VERSION "dbc-export 1 2025.20.8"

NS_ :

BS_:

BU_: ADSP APB APP APS APSB BB BMS CC CMP CMPD CP DAS DI DIF DIR DPB EPAS3P EPAS3S EPASTP EPASTS EPBL EPBR ESP EVSE FC GTW HCML HCMR HVP IBST ICR IDB LS OCS1P PARK PCS PM PMF PMR PNCD PTC RADC RCM RCM2 RCM3 RCU SCCM SCM SCS SDCR TAS TCU TPMS TRCM UI UIS UMC USM VC VCFRONT VCLEFT VCRIGHT VCSEC VEH

BO_ 753 VCFRONT_eFuseDebugStatus: 8 VCFRONT
 SG_ VCFRONT_eFuseDebugStatusIndex M : 0|5@1+ (1,0) [0|31] "" Vector__XXX
 SG_ VCFRONT_leftControllerState m1 : 8|2@1+ (1,0) [0|3] "" Vector__XXX
 SG_ VCFRONT_leftControllerFault m1 : 10|1@1+ (1,0) [0|1] "" Vector__XXX
 SG_ VCFRONT_vcleftSelfTestResult m1 : 11|4@1+ (1,0) [0|15] "" Vector__XXX
 SG_ VCFRONT_leftControllerTemp m1 : 15|11@1+ (0.125,-40) [-40|150] "degC" Vector__XXX
 SG_ VCFRONT_leftControllerEFuseVNFSt m1 : 26|3@1+ (1,0) [0|7] "" Vector__XXX
 SG_ VCFRONT_leftControllerEFuseOutpu m1 : 29|1@1+ (1,0) [0|1] "" Vector__XXX
 SG_ VCFRONT_leftControllerEFuse_0002 m1 : 30|1@1+ (1,0) [0|1] "" Vector__XXX
 SG_ VCFRONT_leftControllerVoltage m1 : 31|14@1+ (0.1,0) [0|1638.3] "V" Vector__XXX
 SG_ VCFRONT_leftControllerEFuseBypas m1 : 45|1@1+ (1,0) [0|1] "" Vector__XXX
 SG_ VCFRONT_leftControllerEFuse_0001 m1 : 46|1@1+ (1,0) [0|1] "" Vector__XXX
 SG_ VCFRONT_leftControllerCurrent m1 : 47|14@1+ (0.1,0) [0|1638.3] "A" Vector__XXX
 SG_ VCFRONT_leftControllerEFuseVNFSe m1 : 61|2@1+ (1,0) [0|3] "" Vector__XXX
 SG_ VCFRONT_PCSState m2 : 8|2@1+ (1,0) [0|3] "" Vector__XXX
 SG_ VCFRONT_PCSFault m2 : 10|1@1+ (1,0) [0|1] "" Vector__XXX
 SG_ VCFRONT_pcsSelfTestResult m2 : 11|4@1+ (1,0) [0|15] "" Vector__XXX
 SG_ VCFRONT_PCSTemp m2 : 15|11@1+ (0.125,-40) [-40|150] "degC" Vector__XXX
 SG_ VCFRONT_PCSEFuseVNFState m2 : 26|3@1+ (1,0) [0|7] "" Vector__XXX
 SG_ VCFRONT_PCSEFuseOutput m2 : 29|1@1+ (1,0) [0|1] "" Vector__XXX
 SG_ VCFRONT_PCSEFuseOutputDesired m2 : 30|1@1+ (1,0) [0|1] "" Vector__XXX
 SG_ VCFRONT_PCSVoltage m2 : 31|14@1+ (0.1,0) [0|1638.3] "V" Vector__XXX
 SG_ VCFRONT_PCSEFuseBypass m2 : 45|1@1+ (1,0) [0|1] "" Vector__XXX
 SG_ VCFRONT_PCSEFuseBypassDesired m2 : 46|1@1+ (1,0) [0|1] "" Vector__XXX
 SG_ VCFRONT_PCSEFuseVNFSelfTestStatu m2 : 61|2@1+ (1,0) [0|3] "" Vector__XXX
 SG_ VCFRONT_iBoosterState m3 : 8|2@1+ (1,0) [0|3] "" Vector__XXX
 SG_ VCFRONT_iBoosterFault m3 : 10|1@1+ (1,0) [0|1] "" Vector__XXX
 SG_ VCFRONT_iBoosterSelfTestResult m3 : 11|4@1+ (1,0) [0|15] "" Vector__XXX
 SG_ VCFRONT_iBoosterTemp m3 : 15|11@1+ (0.125,-40) [-40|150] "degC" Vector__XXX
 SG_ VCFRONT_IBoosterEFuseVNFState m3 : 26|3@1+ (1,0) [0|7] "" Vector__XXX
 SG_ VCFRONT_IBoosterEFuseOutput m3 : 29|1@1+ (1,0) [0|1] "" Vector__XXX
 SG_ VCFRONT_IBoosterEFuseOutputDesir m3 : 30|1@1+ (1,0) [0|1] "" Vector__XXX
 SG_ VCFRONT_iBoosterVoltage m3 : 31|14@1+ (0.1,0) [0|51.1] "V" Vector__XXX
 SG_ VCFRONT_IBoosterEFuseBypass m3 : 45|1@1+ (1,0) [0|1] "" Vector__XXX
 SG_ VCFRONT_IBoosterEFuseBypassDesir m3 : 46|1@1+ (1,0) [0|1] "" Vector__XXX
 SG_ VCFRONT_iBoosterCurrent m3 : 47|14@1+ (0.1,0) [0|1638.3] "A" Vector__XXX
 SG_ VCFRONT_IBoosterEFuseVNFSelfTest m3 : 61|2@1+ (1,0) [0|3] "" Vector__XXX
 SG_ VCFRONT_EPAS3PState m4 : 8|2@1+ (1,0) [0|3] "" Vector__XXX
 SG_ VCFRONT_EPAS3PFault m4 : 10|1@1+ (1,0) [0|1] "" Vector__XXX
 SG_ VCFRONT_EPAS3PSelfTestResult m4 : 11|4@1+ (1,0) [0|15] "" Vector__XXX
 SG_ VCFRONT_EPAS3PTemp m4 : 15|11@1+ (0.125,-40) [-40|150] "degC" Vector__XXX
 SG_ VCFRONT_EPAS3PEFuseVNFState m4 : 26|3@1+ (1,0) [0|7] "" Vector__XXX
 SG_ VCFRONT_EPAS3PEFuseOutput m4 : 29|1@1+ (1,0) [0|1] "" Vector__XXX
 SG_ VCFRONT_EPAS3PEFuseOutputDesired m4 : 30|1@1+ (1,0) [0|1] "" Vector__XXX
 SG_ VCFRONT_EPAS3PVoltage m4 : 31|9@1+ (0.1,0) [0|51.1] "V" Vector__XXX
 SG_ VCFRONT_EPAS3PEFuseHardshortThre m4 : 40|4@1+ (1,0) [0|15] "" Vector__XXX
 SG_ VCFRONT_EPAS3PEFuseBypass m4 : 45|1@1+ (1,0) [0|1] "" Vector__XXX
 SG_ VCFRONT_EPAS3PEFuseBypassDesired m4 : 46|1@1+ (1,0) [0|1] "" Vector__XXX
 SG_ VCFRONT_EPAS3PCurrent m4 : 47|14@1+ (0.1,0) [0|1638.3] "A" Vector__XXX
 SG_ VCFRONT_EPAS3PEFuseVNFSelfTestSt m4 : 61|2@1+ (1,0) [0|3] "" Vector__XXX
 SG_ VCFRONT_EPAS3SState m5 : 8|2@1+ (1,0) [0|3] "" Vector__XXX
 SG_ VCFRONT_EPAS3SFault m5 : 10|1@1+ (1,0) [0|1] "" Vector__XXX
 SG_ VCFRONT_EPAS3SSelfTestResult m5 : 11|4@1+ (1,0) [0|15] "" Vector__XXX
 SG_ VCFRONT_EPAS3STemp m5 : 15|11@1+ (0.125,-40) [-40|150] "degC" Vector__XXX
 SG_ VCFRONT_EPAS3SEFuseVNFState m5 : 26|3@1+ (1,0) [0|7] "" Vector__XXX
 SG_ VCFRONT_EPAS3SEFuseOutput m5 : 29|1@1+ (1,0) [0|1] "" Vector__XXX
 SG_ VCFRONT_EPAS3SEFuseOutputDesired m5 : 30|1@1+ (1,0) [0|1] "" Vector__XXX
 SG_ VCFRONT_EPAS3SVoltage m5 : 31|14@1+ (0.1,0) [0|1638.3] "V" Vector__XXX
 SG_ VCFRONT_EPAS3SEFuseBypass m5 : 45|1@1+ (1,0) [0|1] "" Vector__XXX
 SG_ VCFRONT_EPAS3SEFuseBypassDesired m5 : 46|1@1+ (1,0) [0|1] "" Vector__XXX
 SG_ VCFRONT_EPAS3SCurrent m5 : 47|14@1+ (0.1,0) [0|1638.3] "A" Vector__XXX
 SG_ VCFRONT_EPAS3SEFuseVNFSelfTestSt m5 : 61|2@1+ (1,0) [0|3] "" Vector__XXX
 SG_ VCFRONT_ESPMotorState m6 : 8|2@1+ (1,0) [0|3] "" Vector__XXX
 SG_ VCFRONT_ESPMotorFault m6 : 10|1@1+ (1,0) [0|1] "" Vector__XXX
 SG_ VCFRONT_ESPMotorSelfTestResult m6 : 11|4@1+ (1,0) [0|15] "" Vector__XXX
 SG_ VCFRONT_ESPMotorTemp m6 : 15|11@1+ (0.125,-40) [-40|150] "degC" Vector__XXX
 SG_ VCFRONT_ESPMotorEFuseVNFState m6 : 26|3@1+ (1,0) [0|7] "" Vector__XXX
 SG_ VCFRONT_ESPMotorEFuseOutput m6 : 29|1@1+ (1,0) [0|1] "" Vector__XXX
 SG_ VCFRONT_ESPMotorEFuseOutputDesir m6 : 30|1@1+ (1,0) [0|1] "" Vector__XXX
 SG_ VCFRONT_ESPMotorVoltage m6 : 31|14@1+ (0.1,0) [0|1638.3] "V" Vector__XXX
 SG_ VCFRONT_ESPMotorEFuseBypass m6 : 45|1@1+ (1,0) [0|1] "" Vector__XXX
 SG_ VCFRONT_ESPMotorEFuseBypassDesir m6 : 46|1@1+ (1,0) [0|1] "" Vector__XXX
 SG_ VCFRONT_ESPMotorCurrent m6 : 47|14@1+ (0.1,0) [0|1638.3] "A" Vector__XXX
 SG_ VCFRONT_ESPMotorEFuseVNFSelfTest m6 : 61|2@1+ (1,0) [0|3] "" Vector__XXX
 SG_ VCFRONT_ESPValveState m7 : 8|2@1+ (1,0) [0|3] "" Vector__XXX
 SG_ VCFRONT_ESPValveFault m7 : 10|1@1+ (1,0) [0|1] "" Vector__XXX
 SG_ VCFRONT_ESPValveTemp m7 : 12|11@1+ (0.125,-40) [-40|150] "degC" Vector__XXX
 SG_ VCFRONT_ESPValveVoltage m7 : 28|16@1+ (0.1,0) [0|6553.5] "V" Vector__XXX
 SG_ VCFRONT_ESPValveCurrent m7 : 44|16@1+ (0.01,0) [0|655.35] "A" Vector__XXX
 SG_ VCFRONT_autopilot2State m9 : 8|2@1+ (1,0) [0|3] "" Vector__XXX
 SG_ VCFRONT_autopilot2Fault m9 : 10|1@1+ (1,0) [0|1] "" Vector__XXX
 SG_ VCFRONT_autopilot2Temp m9 : 11|11@1+ (0.125,-40) [-40|150] "degC" Vector__XXX
 SG_ VCFRONT_autopilot2Voltage m9 : 27|16@1+ (0.1,0) [0|6553.5] "V" Vector__XXX
 SG_ VCFRONT_autopilot2Current m9 : 43|10@1+ (0.044,0) [0|45.012] "A" Vector__XXX
 SG_ VCFRONT_sleepBypassState m10 : 8|1@1+ (1,0) [0|1] "" Vector__XXX
 SG_ VCFRONT_sleepBypassFault m10 : 9|1@1+ (1,0) [0|1] "" Vector__XXX
 SG_ VCFRONT_sleepBypassVoltage m10 : 10|16@1+ (0.1,0) [0|6553.5] "V" Vector__XXX
 SG_ VCFRONT_sleepBypassCurrent m10 : 26|16@1+ (0.1,0) [0|6553.5] "A" Vector__XXX
 SG_ VCFRONT_vbatFusedHighState m13 : 8|1@1+ (1,0) [0|1] "" Vector__XXX
 SG_ VCFRONT_vbatFusedHighFault m13 : 9|1@1+ (1,0) [0|1] "" Vector__XXX
 SG_ VCFRONT_vbatFusedSelfTestResult m13 : 10|4@1+ (1,0) [0|15] "" Vector__XXX
 SG_ VCFRONT_vbatFusedHighTemp m13 : 14|11@1+ (0.125,-40) [-40|150] "degC" Vector__XXX
 SG_ VCFRONT_vbatFusedHighVoltage m13 : 30|16@1+ (0.1,0) [0|6553.5] "V" Vector__XXX
 SG_ VCFRONT_vbatFusedHighCurrent m13 : 46|16@1+ (0.1,0) [0|6553.5] "A" Vector__XXX
 SG_ VCFRONT_chargedIBSAmpHours m17 : 8|16@1+ (1,0) [0|65535] "Ah" Vector__XXX
 SG_ VCFRONT_dischargedIBSAmpHours m17 : 24|16@1+ (1,0) [0|65535] "Ah" Vector__XXX
 SG_ VCFRONT_IBSUnfilteredTemperature m17 : 40|16@1- (0.01,0) [-327.67|327.67] "degC" Vector__XXX

BO_ 769 VCFRONT_info: 8 VCFRONT
 SG_ VCFRONT_infoIndex M : 0|8@1+ (1,0) [0|255] "" Vector__XXX
 SG_ VCFRONT_infoBuildType m10 : 8|3@1+ (1,0) [0|7] "" Vector__XXX
 SG_ VCFRONT_infoBuildConfigId m10 : 16|16@1+ (1,0) [0|65535] "" Vector__XXX
 SG_ VCFRONT_infoHardwareId m10 : 32|16@1+ (1,0) [0|65535] "" Vector__XXX
 SG_ VCFRONT_infoComponentId m10 : 48|16@1+ (1,0) [0|65535] "" Vector__XXX
 SG_ VCFRONT_infoPcbaId m11 : 8|8@1+ (1,0) [0|255] "" Vector__XXX
 SG_ VCFRONT_infoAssemblyId m11 : 16|8@1+ (1,0) [0|255] "" Vector__XXX
 SG_ VCFRONT_infoUsageId m11 : 24|16@1+ (1,0) [0|65535] "" Vector__XXX
 SG_ VCFRONT_infoSubUsageId m11 : 40|16@1+ (1,0) [0|65535] "" Vector__XXX
 SG_ VCFRONT_infoAppCrc m13 : 8|32@1+ (1,0) [0|4294967295] "" Vector__XXX
 SG_ VC_infoHCMLAppCRC m16 : 32|32@1+ (1,0) [0|4294967295] "" Vector__XXX
 SG_ VCFRONT_infoAppGitHash m17 : 8|56@1+ (1,0) [0|7.20575940379e+16] "" Vector__XXX
 SG_ VCFRONT_infoBootGitHash m18 : 8|56@1+ (1,0) [0|7.20575940379e+16] "" Vector__XXX
 SG_ VCFRONT_infoPlatformType m19 : 8|8@1+ (1,0) [0|255] "" Vector__XXX
 SG_ VCFRONT_infoBootUdsProtoVersion m20 : 8|16@1+ (1,0) [0|65535] "" Vector__XXX
 SG_ VCFRONT_infoBootCrc m20 : 24|32@1+ (1,0) [0|4294967295] "" Vector__XXX
 SG_ VC_infoHCMRAppCRC m23 : 32|32@1+ (1,0) [0|4294967295] "" Vector__XXX

BO_ 1014 VCFRONT_lightStatus: 8 VCFRONT
 SG_ VCFRONT_lowBeamLeftStatus : 0|2@1+ (1,0) [0|3] "" Vector__XXX
 SG_ VCFRONT_lowBeamRightStatus : 2|2@1+ (1,0) [0|3] "" Vector__XXX
 SG_ VCFRONT_highBeamLeftStatus : 4|2@1+ (1,0) [0|3] "" Vector__XXX
 SG_ VCFRONT_highBeamRightStatus : 6|2@1+ (1,0) [0|3] "" Vector__XXX
 SG_ VCFRONT_DRLLeftStatus : 8|2@1+ (1,0) [0|3] "" Vector__XXX
 SG_ VCFRONT_DRLRightStatus : 10|2@1+ (1,0) [0|3] "" Vector__XXX
 SG_ VCFRONT_fogLeftStatus : 12|2@1+ (1,0) [0|3] "" Vector__XXX
 SG_ VCFRONT_fogRightStatus : 14|2@1+ (1,0) [0|3] "" Vector__XXX
 SG_ VCFRONT_sideMarkersStatus : 16|2@1+ (1,0) [0|3] "" Vector__XXX
 SG_ VCFRONT_sideRepeaterLeftStatus : 18|2@1+ (1,0) [0|3] "" Vector__XXX
 SG_ VCFRONT_sideRepeaterRightStatus : 20|2@1+ (1,0) [0|3] "" Vector__XXX
 SG_ VCFRONT_turnSignalLeftStatus : 22|2@1+ (1,0) [0|3] "" Vector__XXX
 SG_ VCFRONT_turnSignalRightStatus : 24|2@1+ (1,0) [0|3] "" Vector__XXX
 SG_ VCFRONT_parkLeftStatus : 26|2@1+ (1,0) [0|3] "" Vector__XXX
 SG_ VCFRONT_parkRightStatus : 28|2@1+ (1,0) [0|3] "" Vector__XXX
 SG_ VCFRONT_lowBeamLeftReadyForAimin : 30|1@1+ (1,0) [0|1] "" Vector__XXX
 SG_ VCFRONT_lowBeamRightReadyForAimi : 31|1@1+ (1,0) [0|1] "" Vector__XXX
 SG_ VCFRONT_lowBeamsOnForDRL : 32|1@1+ (1,0) [0|1] "" Vector__XXX
 SG_ VC_rightHeadlampHealth : 33|3@1+ (1,0) [0|7] "" Vector__XXX
 SG_ VC_leftHeadlampHealth : 36|3@1+ (1,0) [0|7] "" Vector__XXX
 SG_ VCFRONT_lightStatusMuxIndex M : 39|3@1+ (1,0) [0|7] "" Vector__XXX
 SG_ VCFRONT_isAdaptiveHighBeamAvaila m1 : 42|1@1+ (1,0) [0|1] "" Vector__XXX
 SG_ VCFRONT_isAdaptiveHighBeamFaulte m1 : 43|1@1+ (1,0) [0|1] "" Vector__XXX
 SG_ VCFRONT_isBendLightingAvailable m1 : 44|1@1+ (1,0) [0|1] "" Vector__XXX
 SG_ VCFRONT_advancedDrivingBeamStatu m1 : 45|2@1+ (1,0) [0|3] "" Vector__XXX
 SG_ VCFRONT_headlampBendAngle m1 : 47|8@1- (0.1,0) [-12.7|12.7] "deg" Vector__XXX
 SG_ VCFRONT_headlampRoadClass m1 : 55|2@1+ (1,0) [0|3] "" Vector__XXX

BO_ 1013 VCFRONT_lighting: 8 VCFRONT
 SG_ VCFRONT_indicatorLeftRequest : 0|2@1+ (1,0) [0|3] "" Vector__XXX
 SG_ VCFRONT_indicatorRightRequest : 2|2@1+ (1,0) [0|3] "" Vector__XXX
 SG_ VCFRONT_hazardLightRequest : 4|4@1+ (1,0) [0|15] "" Vector__XXX
 SG_ VCFRONT_ambientLightingBrightnes : 8|8@1+ (0.5,0) [0|127] "%" Vector__XXX
 SG_ VCFRONT_switchLightingBrightness : 16|8@1+ (0.5,0) [0|127] "%" Vector__XXX
 SG_ VCFRONT_courtesyLightingRequest : 24|1@1+ (1,0) [0|1] "" Vector__XXX
 SG_ VCFRONT_hazardSwitchBacklight : 27|1@1+ (1,0) [0|1] "" Vector__XXX
 SG_ VCFRONT_highBeamControlState : 28|2@1+ (1,0) [0|3] "" Vector__XXX
 SG_ VCFRONT_dynamicBrakeLightState : 30|2@1+ (1,0) [0|3] "" Vector__XXX
 SG_ VCFRONT_lightingCoreState : 32|4@1+ (1,0) [0|15] "" Vector__XXX
 SG_ VCFRONT_intHighBeamsFunctionStat : 36|1@1+ (1,0) [0|1] "" Vector__XXX
 SG_ VCFRONT_latchedHighBeamsFunction : 37|1@1+ (1,0) [0|1] "" Vector__XXX
 SG_ VCFRONT_frontFogFunctionState : 38|1@1+ (1,0) [0|1] "" Vector__XXX
 SG_ VCFRONT_headlightsReadyOrTimedOu : 39|1@1+ (1,0) [0|1] "" Vector__XXX
 SG_ VCFRONT_turnIndicatorStalk : 40|2@1+ (1,0) [0|3] "" Vector__XXX
 SG_ VCFRONT_highBeamLatchingState : 42|2@1+ (1,0) [0|3] "" Vector__XXX
 SG_ VCFRONT_lightingCustomState : 44|5@1+ (1,0) [0|31] "" Vector__XXX
 SG_ VC_fastFlashHazardsActive : 49|1@1+ (1,0) [0|1] "" Vector__XXX
 SG_ VCFRONT_indicatorLeftInternal : 50|2@1+ (1,0) [0|3] "" Vector__XXX
 SG_ VCFRONT_indicatorRightInternal : 52|2@1+ (1,0) [0|3] "" Vector__XXX

BO_ 1801 VCFRONT_logging0point1Hz: 8 VCFRONT
 SG_ VCFRONT_logging0point1HzIndex M : 0|5@1+ (1,0) [0|31] "" Vector__XXX
 SG_ VC_hcmlFactoryOfOrigin m26 : 5|2@1+ (1,0) [0|3] "" Vector__XXX
 SG_ VC_hcmlHellaPartNumberStatus m26 : 7|1@1+ (1,0) [0|1] "" Vector__XXX
 SG_ VC_hcmlHellaPartNumber m26 : 8|32@1+ (1,0) [0|4294967295] "-" Vector__XXX
 SG_ VC_hcmlCurrentBinMappingType m26 : 40|2@1+ (1,0) [0|3] "" Vector__XXX
 SG_ VC_hcmlCurrentBin0Value m26 : 42|3@1+ (1,0) [0|7] "" Vector__XXX
 SG_ VC_hcmlCurrentBin1Value m26 : 45|3@1+ (1,0) [0|7] "" Vector__XXX
 SG_ VC_hcmlCurrentBin2Value m26 : 48|3@1+ (1,0) [0|7] "" Vector__XXX
 SG_ VC_hcmlCurrentBin3Value m26 : 51|3@1+ (1,0) [0|7] "" Vector__XXX
 SG_ VC_hcmlCurrentBin4Value m26 : 54|3@1+ (1,0) [0|7] "" Vector__XXX
 SG_ VC_hcmlCurrentBin5Value m26 : 57|3@1+ (1,0) [0|7] "" Vector__XXX
 SG_ VC_hcmlRegionAndSide m26 : 60|3@1+ (1,0) [0|7] "" Vector__XXX
 SG_ VC_hcmrFactoryOfOrigin m27 : 5|2@1+ (1,0) [0|3] "" Vector__XXX
 SG_ VC_hcmrHellaPartNumberStatus m27 : 7|1@1+ (1,0) [0|1] "" Vector__XXX
 SG_ VC_hcmrHellaPartNumber m27 : 8|32@1+ (1,0) [0|4294967295] "-" Vector__XXX
 SG_ VC_hcmrCurrentBinMappingType m27 : 40|2@1+ (1,0) [0|3] "" Vector__XXX
 SG_ VC_hcmrCurrentBin0Value m27 : 42|3@1+ (1,0) [0|7] "" Vector__XXX
 SG_ VC_hcmrCurrentBin1Value m27 : 45|3@1+ (1,0) [0|7] "" Vector__XXX
 SG_ VC_hcmrCurrentBin2Value m27 : 48|3@1+ (1,0) [0|7] "" Vector__XXX
 SG_ VC_hcmrCurrentBin3Value m27 : 51|3@1+ (1,0) [0|7] "" Vector__XXX
 SG_ VC_hcmrCurrentBin4Value m27 : 54|3@1+ (1,0) [0|7] "" Vector__XXX
 SG_ VC_hcmrCurrentBin5Value m27 : 57|3@1+ (1,0) [0|7] "" Vector__XXX
 SG_ VC_hcmrRegionAndSide m27 : 60|3@1+ (1,0) [0|7] "" Vector__XXX

BO_ 705 VCFRONT_logging10Hz: 8 VCFRONT
 SG_ VCFRONT_logging10HzIndex M : 0|3@1+ (1,0) [0|7] "" Vector__XXX
 SG_ VCFRONT_pumpBatteryOutVoltage m0 : 3|7@1+ (0.2,0) [0|20] "V" Vector__XXX
 SG_ VCFRONT_pumpPowertrainOutVoltage m0 : 10|7@1+ (0.2,0) [0|20] "V" Vector__XXX
 SG_ VCFRONT_pumpBatteryInitd m0 : 17|1@1+ (1,0) [0|1] "" Vector__XXX
 SG_ VCFRONT_pumpPowertrainInitd m0 : 18|1@1+ (1,0) [0|1] "" Vector__XXX
 SG_ VCFRONT_pumpBatteryEnabled m0 : 19|1@1+ (1,0) [0|1] "" Vector__XXX
 SG_ VCFRONT_pumpPowertrainEnabled m0 : 20|1@1+ (1,0) [0|1] "" Vector__XXX
 SG_ VCFRONT_pumpBatteryPowerOn m0 : 21|1@1+ (1,0) [0|1] "" Vector__XXX
 SG_ VCFRONT_pumpPowertrainPowerOn m0 : 22|1@1+ (1,0) [0|1] "" Vector__XXX
 SG_ VCFRONT_pumpsWake m0 : 23|1@1+ (1,0) [0|1] "" Vector__XXX
 SG_ VCFRONT_pumpBatSpiError m0 : 24|1@1+ (1,0) [0|1] "" Vector__XXX
 SG_ VCFRONT_pumpPtSpiError m0 : 25|1@1+ (1,0) [0|1] "" Vector__XXX
 SG_ VCFRONT_coolantFlowChillerActual m0 : 26|8@1+ (0.1,0) [0|25] "LPM" Vector__XXX
 SG_ VCFRONT_radiatorFanOutVoltage m0 : 34|7@1+ (0.2,0) [0|20] "V" Vector__XXX
 SG_ VCFRONT_radiatorFanInitd m0 : 41|1@1+ (1,0) [0|1] "" Vector__XXX
 SG_ VCFRONT_radiatorFanEnabled m0 : 42|1@1+ (1,0) [0|1] "" Vector__XXX
 SG_ VCFRONT_radiatorFanPowerOn m0 : 43|1@1+ (1,0) [0|1] "" Vector__XXX
 SG_ VCFRONT_radiatorFanPhaseCurrent m0 : 44|8@1+ (0.25,-10) [-10|50] "A" Vector__XXX
 SG_ VCFRONT_radiatorFanPhaseIMax m0 : 52|7@1+ (0.25,5) [5|35] "A" Vector__XXX
 SG_ VCFRONT_thmlFanSpiError m0 : 59|1@1+ (1,0) [0|1] "" Vector__XXX
 SG_ VCFRONT_chargeTrapNominalCOP1Bat m0 : 60|1@1+ (1,0) [0|1] "" Vector__XXX
 SG_ VCFRONT_chargeTrapNominalCOP1Chi m0 : 61|1@1+ (1,0) [0|1] "" Vector__XXX

BO_ 897 VCFRONT_logging1Hz: 8 VCFRONT
 SG_ VCFRONT_logging1HzIndex M : 0|5@1+ (1,0) [0|31] "" Vector__XXX
 SG_ VCFRONT_modeTransitionID m0 : 5|6@1+ (1,0) [0|63] "" Vector__XXX
 SG_ VCFRONT_modeDesired m0 : 11|2@1+ (1,0) [0|3] "" Vector__XXX
 SG_ VCFRONT_targetPTActiveCool m0 : 13|7@1+ (1,0) [0|100] "degC" Vector__XXX
 SG_ VCFRONT_targetPtOptionalActiveCo m0 : 20|7@1+ (1,0) [0|100] "degC" Vector__XXX
 SG_ VCFRONT_targetPTPassive m0 : 27|7@1+ (1,-20) [-20|80] "degC" Vector__XXX
 SG_ VCFRONT_targetBatActiveCool m0 : 34|7@1+ (1,0) [0|100] "degC" Vector__XXX
 SG_ VCFRONT_targetBatOptionalActiveC m0 : 41|7@1+ (1,0) [0|100] "degC" Vector__XXX
 SG_ VCFRONT_targetBatPassive m0 : 48|7@1+ (1,-20) [-20|80] "degC" Vector__XXX
 SG_ VCFRONT_targetBatActiveHeat m0 : 55|7@1+ (1,-40) [-40|60] "degC" Vector__XXX
 SG_ VCFRONT_condenserPressureLimit m1 : 5|6@1+ (0.16,10) [10|20] "bar" Vector__XXX
 SG_ VCFRONT_fanDemandCondenser m1 : 11|7@1+ (1,0) [0|100] "%" Vector__XXX
 SG_ VCFRONT_fanDemandRadiator m1 : 18|7@1+ (1,0) [0|100] "%" Vector__XXX
 SG_ VCFRONT_tempRefrigSuction m1 : 25|8@1+ (0.5,-40) [-40|85] "degC" Vector__XXX
 SG_ VCFRONT_pumpBatteryFETTemp m1 : 33|8@1+ (1,-40) [-40|150] "degC" Vector__XXX
 SG_ VCFRONT_pumpPowertrainFETTemp m1 : 41|8@1+ (1,-40) [-40|150] "degC" Vector__XXX
 SG_ VCFRONT_radiatorFanFETTemp m1 : 49|8@1+ (1,-40) [-40|150] "degC" Vector__XXX
 SG_ VCFRONT_radiatorFanRunReason m1 : 57|4@1+ (1,0) [0|15] "" Vector__XXX
 SG_ VCFRONT_coolantValveModeWrong m1 : 61|1@1+ (1,0) [0|1] "" Vector__XXX
 SG_ VCFRONT_coolantTempBasedMode m1 : 62|2@1+ (1,0) [0|3] "" Vector__XXX
 SG_ VCFRONT_coolantValveRecalReason m2 : 5|3@1+ (1,0) [0|7] "" Vector__XXX
 SG_ VCFRONT_coolantValveCountRange m2 : 8|10@1+ (1,375) [375|1375] "ticks" Vector__XXX
 SG_ VCFRONT_coolantValveAngleDrift m2 : 18|10@1+ (0.25,-127) [-127|127] "degrees" Vector__XXX
 SG_ VCFRONT_coolantValveRecalCount m2 : 28|16@1+ (1,0) [0|65535] "" Vector__XXX
 SG_ VCFRONT_coolantValveWindupEst m2 : 44|6@1+ (2,0) [0|126] "ticks" Vector__XXX
 SG_ VCFRONT_coolantValveRadBypass m2 : 50|7@1+ (1,0) [0|100] "%" Vector__XXX
 SG_ VCFRONT_usingModeledPs m2 : 57|1@1+ (1,0) [0|1] "" Vector__XXX
 SG_ VCFRONT_usingModeledPd m2 : 58|1@1+ (1,0) [0|1] "" Vector__XXX
 SG_ VCFRONT_usingModeledPl m2 : 59|1@1+ (1,0) [0|1] "" Vector__XXX
 SG_ VCFRONT_usingModeledTs m2 : 60|1@1+ (1,0) [0|1] "" Vector__XXX
 SG_ VCFRONT_usingModeledTd m2 : 61|1@1+ (1,0) [0|1] "" Vector__XXX
 SG_ VCFRONT_usingModeledTl m2 : 62|1@1+ (1,0) [0|1] "" Vector__XXX
 SG_ VCFRONT_hpChargeCableType m5 : 5|2@1+ (1,0) [0|3] "" Vector__XXX
 SG_ VCFRONT_subcoolActual m5 : 8|7@1- (0.4,15.2) [-10|40] "degC" Vector__XXX
 SG_ VCFRONT_hpSubcoolTarget m5 : 16|5@1+ (1,0) [0|31] "degC" Vector__XXX
 SG_ VCFRONT_CMPDischargeSuperheat m5 : 21|5@1- (1,6) [-10|21] "degC" Vector__XXX
 SG_ VCFRONT_hpCOP m5 : 26|6@1+ (0.1,0) [0|6] "-" Vector__XXX
 SG_ VCFRONT_lowSideWattsLift m5 : 32|7@1+ (60,0) [0|7600] "W" Vector__XXX
 SG_ VCFRONT_tempSuperheatActual m5 : 39|10@1+ (0.1,-20) [-20|80] "degC" Vector__XXX
 SG_ VCFRONT_tempSuperheatTarget m5 : 49|10@1+ (0.1,0) [0|60] "degC" Vector__XXX
 SG_ VCFRONT_refrigerantHasBeenFilled m5 : 59|1@1+ (1,0) [0|1] "" Vector__XXX
 SG_ VCFRONT_refCommissionStatus m5 : 60|2@1+ (1,0) [0|3] "" Vector__XXX
 SG_ VCFRONT_LCCPurgeActive m5 : 62|1@1+ (1,0) [0|1] "" Vector__XXX
 SG_ VCFRONT_exteriorQuietModeEnabled m6 : 5|1@1+ (1,0) [0|1] "" Vector__XXX
 SG_ VCFRONT_exteriorQuietModeAllowed m6 : 6|1@1+ (1,0) [0|1] "" Vector__XXX
 SG_ VCFRONT_CCQdotFdFrwrdTarget m6 : 7|7@1+ (80,0) [0|10100] "W" Vector__XXX
 SG_ VCFRONT_CCQdotFdbk m6 : 14|7@1- (80,0) [-5000|5000] "W" Vector__XXX
 SG_ VCFRONT_CCQdotActual m6 : 21|7@1+ (80,0) [0|10100] "W" Vector__XXX
 SG_ VCFRONT_evapFdFrwrdTarget m6 : 28|7@1+ (80,0) [0|10100] "W" Vector__XXX
 SG_ VCFRONT_evapFdbk m6 : 35|7@1- (100,-3300) [-9700|3000] "W" Vector__XXX
 SG_ VCFRONT_DIQdotA m6 : 42|7@1+ (80,0) [0|10000] "W" Vector__XXX
 SG_ VCFRONT_evapFdFrwrdTargetMinimum m6 : 49|7@1+ (80,0) [0|10000] "W" Vector__XXX
 SG_ VCFRONT_passiveCoolingState m6 : 56|2@1+ (1,0) [0|3] "" Vector__XXX
 SG_ VCFRONT_totalLoadCoolingDominant m6 : 58|1@1+ (1,0) [0|1] "" Vector__XXX
 SG_ VCFRONT_feedfwdLoadCoolingDomina m6 : 59|1@1+ (1,0) [0|1] "" Vector__XXX
 SG_ VCFRONT_modelLoadCoolingDominant m6 : 60|1@1+ (1,0) [0|1] "" Vector__XXX
 SG_ VCFRONT_hpPotentialLowRefrig m6 : 61|1@1+ (1,0) [0|1] "" Vector__XXX
 SG_ VCFRONT_hpRefrigerantPurgeState m6 : 62|2@1+ (1,0) [0|3] "" Vector__XXX
 SG_ VCFRONT_estPressureLiq m7 : 5|6@1+ (0.5,0) [0|31] "bar" Vector__XXX
 SG_ VCFRONT_estPressureSuct m7 : 11|7@1+ (0.125,0) [0|11.5] "bar" Vector__XXX
 SG_ VCFRONT_estPressureDisch m7 : 18|7@1+ (0.25,0) [0|31.75] "bar" Vector__XXX
 SG_ VCFRONT_estTempLiq m7 : 25|8@1- (0.8,68.8) [-33|170] "degC" Vector__XXX
 SG_ VCFRONT_estTempSuct m7 : 33|6@1- (1,2) [-30|33] "degC" Vector__XXX
 SG_ VCFRONT_estTempDisch m7 : 39|7@1- (1.5,75) [-20|169] "degC" Vector__XXX
 SG_ VCFRONT_estCompressorRpm m7 : 46|9@1+ (30,0) [0|15000] "rpm" Vector__XXX
 SG_ VCFRONT_estQLift m7 : 55|6@1+ (100,0) [0|6300] "W" Vector__XXX
 SG_ VCFRONT_cycleModelConverged m7 : 61|1@1+ (1,0) [0|1] "" Vector__XXX
 SG_ VCFRONT_compStandbyCoastDownMode m7 : 62|1@1+ (1,0) [0|1] "" Vector__XXX
 SG_ VCFRONT_compStandbyShowroomMode m7 : 63|1@1+ (1,0) [0|1] "" Vector__XXX
 SG_ VCFRONT_chillerExvCalibOffset m8 : 5|5@1- (8,0) [-127|120] "ticks" Vector__XXX
 SG_ VCFRONT_evapExvCalibOffset m8 : 10|5@1- (8,0) [-127|120] "ticks" Vector__XXX
 SG_ VCFRONT_recircExvCalibOffset m8 : 15|5@1- (8,0) [-127|120] "ticks" Vector__XXX
 SG_ VCFRONT_lccExvCalibOffset m8 : 20|5@1- (8,0) [-127|120] "ticks" Vector__XXX
 SG_ VCFRONT_ccLeftExvCalibOffset m8 : 25|5@1- (8,0) [-127|120] "ticks" Vector__XXX
 SG_ VCFRONT_ccRightExvCalibOffset m8 : 30|5@1- (8,0) [-127|120] "ticks" Vector__XXX
 SG_ VCFRONT_chillerEXVControlState m8 : 35|3@1+ (1,0) [0|7] "" Vector__XXX
 SG_ VCFRONT_evapEXVControlState m8 : 38|3@1+ (1,0) [0|7] "" Vector__XXX
 SG_ VCFRONT_recircEXVControlState m8 : 41|3@1+ (1,0) [0|7] "" Vector__XXX
 SG_ VCFRONT_lccEXVControlState m8 : 44|3@1+ (1,0) [0|7] "" Vector__XXX
 SG_ VCFRONT_cclEXVControlState m8 : 47|3@1+ (1,0) [0|7] "" Vector__XXX
 SG_ VCFRONT_ccrEXVControlState m8 : 50|3@1+ (1,0) [0|7] "" Vector__XXX
 SG_ VCFRONT_chillerExvCalibFailed m8 : 53|1@1+ (1,0) [0|1] "" Vector__XXX
 SG_ VCFRONT_evapExvCalibFailed m8 : 54|1@1+ (1,0) [0|1] "" Vector__XXX
 SG_ VCFRONT_recircExvCalibFailed m8 : 55|1@1+ (1,0) [0|1] "" Vector__XXX
 SG_ VCFRONT_lccExvCalibFailed m8 : 56|1@1+ (1,0) [0|1] "" Vector__XXX
 SG_ VCFRONT_ccLeftExvCalibFailed m8 : 57|1@1+ (1,0) [0|1] "" Vector__XXX
 SG_ VCFRONT_ccRightExvCalibFailed m8 : 58|1@1+ (1,0) [0|1] "" Vector__XXX
 SG_ VCFRONT_ambientTempSniffActive m8 : 59|1@1+ (1,0) [0|1] "" Vector__XXX
 SG_ VCFRONT_ambientTempPassiveSniffi m8 : 60|1@1+ (1,0) [0|1] "" Vector__XXX
 SG_ VCFRONT_ambientTempRadSampling m8 : 61|1@1+ (1,0) [0|1] "" Vector__XXX
 SG_ VCFRONT_ambientTempSpeedSampling m8 : 62|1@1+ (1,0) [0|1] "" Vector__XXX
 SG_ VCFRONT_feedFwdMDotEvaporator m12 : 5|8@1+ (0.005,0) [0|1] "-" Vector__XXX
 SG_ VCFRONT_hpCabinHeatBatteryHeatAm m12 : 13|1@1+ (1,0) [0|1] "" Vector__XXX
 SG_ VCFRONT_hpCabinHeatBatteryHeatCO m12 : 14|1@1+ (1,0) [0|1] "" Vector__XXX
 SG_ VCFRONT_feedFwdMDotCabinCondense m12 : 15|8@1+ (0.005,0) [0|1] "-" Vector__XXX
 SG_ VCFRONT_feedBackEvapTempControll m12 : 23|7@1+ (0.01,-0.5) [-0.5|0.5] "-" Vector__XXX
 SG_ VCFRONT_feedBackDuctTempControll m12 : 30|8@1+ (0.01,-1) [-1|1] "-" Vector__XXX
 SG_ VCFRONT_isSolenoidAllowed m12 : 38|1@1+ (1,0) [0|1] "" Vector__XXX
 SG_ VCFRONT_maxChillerCoolingPower m12 : 39|8@1+ (100,0) [0|20000] "W" Vector__XXX
 SG_ VCFRONT_fanControlRadCanCool m12 : 47|1@1+ (1,0) [0|1] "" Vector__XXX
 SG_ VCFRONT_fanControlFeedfwdActive m12 : 48|1@1+ (1,0) [0|1] "" Vector__XXX
 SG_ VCFRONT_fanControlRadiatorUa m12 : 49|7@1+ (8,0) [0|1000] "W/C" Vector__XXX
 SG_ VCFRONT_fanControlRadiatorInletT m12 : 56|6@1- (1.8,36) [-20|90] "C" Vector__XXX
 SG_ VCFRONT_hpASBatteryHeatingAllowe m14 : 5|1@1+ (1,0) [0|1] "" Vector__XXX
 SG_ VCFRONT_hpCOP1BatteryHeatingAllo m14 : 6|1@1+ (1,0) [0|1] "" Vector__XXX
 SG_ VCFRONT_hpCabinHeatScavengeOnly m14 : 7|1@1+ (1,0) [0|1] "" Vector__XXX
 SG_ VCFRONT_hpCabinHeatAmbientSource m14 : 8|1@1+ (1,0) [0|1] "" Vector__XXX
 SG_ VCFRONT_hpCabinHeatReheatScaveng m14 : 9|1@1+ (1,0) [0|1] "" Vector__XXX
 SG_ VCFRONT_hpCabinHeatReheatAmbient m14 : 10|1@1+ (1,0) [0|1] "" Vector__XXX
 SG_ VCFRONT_hpCabinHeatBlend m14 : 11|1@1+ (1,0) [0|1] "" Vector__XXX
 SG_ VCFRONT_hpCabinHeatCOP1 m14 : 12|1@1+ (1,0) [0|1] "" Vector__XXX
 SG_ VCFRONT_hpCabinHeatBatteryHeatRe m14 : 13|1@1+ (1,0) [0|1] "" Vector__XXX
 SG_ VCFRONT_hpCabinHeatBatteryCoolRe m14 : 14|1@1+ (1,0) [0|1] "" Vector__XXX
 SG_ VCFRONT_hpCabinCoolEvaporator m14 : 15|1@1+ (1,0) [0|1] "" Vector__XXX
 SG_ VCFRONT_hpCabinCoolEvaporatorReh m14 : 16|1@1+ (1,0) [0|1] "" Vector__XXX
 SG_ VCFRONT_hpBatteryHeatAmbientSour m14 : 17|1@1+ (1,0) [0|1] "" Vector__XXX
 SG_ VCFRONT_hpBatteryHeatCOP1 m14 : 18|1@1+ (1,0) [0|1] "" Vector__XXX
 SG_ VCFRONT_hpBatteryCool m14 : 19|1@1+ (1,0) [0|1] "" Vector__XXX
 SG_ VCFRONT_hpBatteryCoolCabinConden m14 : 20|1@1+ (1,0) [0|1] "" Vector__XXX
 SG_ VCFRONT_hpBatteryCoolCabinC_0001 m14 : 21|1@1+ (1,0) [0|1] "" Vector__XXX
 SG_ VCFRONT_hpBatteryCoolCabinReheat m14 : 22|1@1+ (1,0) [0|1] "" Vector__XXX
 SG_ VCFRONT_hpBatteryCoolEvaporator m14 : 23|1@1+ (1,0) [0|1] "" Vector__XXX
 SG_ VCFRONT_suctionSuperheatEstTsSNA m14 : 24|4@1+ (2,0) [0|30] "degC" Vector__XXX
 SG_ VCFRONT_tempRefrigSuctionEst m14 : 28|6@1- (1.2,0) [-25|37.2] "degC" Vector__XXX
 SG_ VCFRONT_hpBattOverTempHvacDisabl m14 : 34|1@1+ (1,0) [0|1] "" Vector__XXX
 SG_ VCFRONT_hpDiagLouverCalib m14 : 35|1@1+ (1,0) [0|1] "" Vector__XXX
 SG_ VCFRONT_hpDiagHighSideNotNominal m14 : 36|1@1+ (1,0) [0|1] "" Vector__XXX
 SG_ VCFRONT_hpForceModeRadClear m14 : 37|1@1+ (1,0) [0|1] "" Vector__XXX
 SG_ VCFRONT_estPressureDischargeSat m14 : 38|7@1+ (0.25,0) [0|31.75] "bar" Vector__XXX
 SG_ VCFRONT_tempRefrigLiquid m14 : 45|11@1+ (0.125,-40) [-40|150] "degC" Vector__XXX
 SG_ VCFRONT_totalBattHeatingPower m14 : 56|7@1+ (150,0) [0|19050] "W" Vector__XXX
 SG_ VCFRONT_hpPotentialFrozenRadiato m14 : 63|1@1+ (1,0) [0|1] "" Vector__XXX
 SG_ VCFRONT_passiveSeriesRegOn m16 : 5|1@1+ (1,0) [0|1] "" Vector__XXX
 SG_ VCFRONT_passiveDemandRadBypass m16 : 8|7@1+ (1,0) [0|100] "%" Vector__XXX
 SG_ VCFRONT_targetLccActiveCoolCap m16 : 16|7@1+ (1,0) [0|100] "degC" Vector__XXX
 SG_ VCFRONT_targetLccActiveCoolEff m16 : 24|7@1+ (1,0) [0|100] "degC" Vector__XXX
 SG_ VCFRONT_coolantValveDailyAngleTr m16 : 32|7@1+ (60,0) [0|7500] "degrees" Vector__XXX
 SG_ VCFRONT_dischargePressureLimit m16 : 40|7@1+ (0.25,0) [0|26] "bar" Vector__XXX
 SG_ VCFRONT_radMovementBlockActive m16 : 47|1@1+ (1,0) [0|1] "" Vector__XXX
 SG_ VCFRONT_radBypassMoveReason m16 : 48|4@1+ (1,0) [0|15] "" Vector__XXX
 SG_ VCFRONT_hpBattHeatingPower m16 : 52|7@1+ (100,0) [0|10000] "W" Vector__XXX
 SG_ VCFRONT_tempCoolantPTInletEstSta m16 : 59|2@1+ (1,0) [0|3] "" Vector__XXX
 SG_ VCFRONT_hpColdStagnationLimit m17 : 8|7@1+ (1,-40) [-40|80] "degC" Vector__XXX
 SG_ VCFRONT_hpHotStagnationLimit m17 : 16|7@1+ (1,-40) [-40|80] "degC" Vector__XXX
 SG_ VCFRONT_hpCompFlowIndex m17 : 23|8@1+ (1,0) [30|255] "-" Vector__XXX
 SG_ VCFRONT_hpCompFlowIndexFiltered m17 : 31|8@1+ (1,0) [30|255] "-" Vector__XXX
 SG_ VCFRONT_subcoolEstTlSNA m17 : 39|6@1- (2,0) [-10|53] "degC" Vector__XXX
 SG_ VCFRONT_subcoolEstPlSNA m17 : 45|6@1- (2,0) [-10|53] "degC" Vector__XXX
 SG_ VCFRONT_tempRefrigLiquidEst m17 : 51|6@1+ (2,0) [0|125] "degC" Vector__XXX
 SG_ VCFRONT_pressureRefrigLiquidEst m17 : 57|6@1+ (0.5,0) [0|31] "bar" Vector__XXX
 SG_ VCFRONT_cmpIsentropicCheckPassed m17 : 63|1@1+ (1,0) [0|1] "" Vector__XXX
 SG_ VCFRONT_louverPosReason m18 : 5|4@1+ (1,0) [0|15] "" Vector__XXX
 SG_ VCFRONT_hpEnergyFlowIndex m18 : 9|8@1+ (4,0) [0|1020] "-" Vector__XXX
 SG_ VCFRONT_hpEnergyFlowIndexFiltere m18 : 17|8@1+ (4,0) [0|1020] "-" Vector__XXX
 SG_ VCFRONT_ductLeftAtSS m18 : 25|1@1+ (1,0) [0|1] "" Vector__XXX
 SG_ VCFRONT_ductRightAtSS m18 : 26|1@1+ (1,0) [0|1] "" Vector__XXX
 SG_ VCFRONT_minCompressorRPMAllowed m18 : 27|7@1+ (90,0) [0|11430] "rpm" Vector__XXX
 SG_ VCFRONT_ccRefrigerantMassFlow m18 : 34|6@1+ (4,0) [0|251] "g/s" Vector__XXX
 SG_ VCFRONT_highSideDpResidual m18 : 40|7@1- (0.1,0) [-6|6] "bar" Vector__XXX
 SG_ VCFRONT_abnormalHighSuctionSuper m18 : 47|1@1+ (1,0) [0|1] "" Vector__XXX
 SG_ VCFRONT_coolantValveAngleTravel m18 : 48|10@1+ (5,0) [0|5000] "degrees" Vector__XXX
 SG_ VCFRONT_chargeShuttleType m18 : 58|2@1+ (1,0) [0|3] "" Vector__XXX
 SG_ VCFRONT_hpRefrigTempSensorCheckC m18 : 60|1@1+ (1,0) [0|1] "" Vector__XXX
 SG_ VCFRONT_hpRefrigPressureSensorCh m18 : 61|1@1+ (1,0) [0|1] "" Vector__XXX
 SG_ VCFRONT_tempSuperheatActFiltered m21 : 5|8@1- (0.25,26.5) [-5|58] "degC" Vector__XXX
 SG_ VCFRONT_tempRefrigDischarge m21 : 13|11@1+ (0.125,-40) [-40|150] "degC" Vector__XXX
 SG_ VCFRONT_pumpBatteryRPMTarget m21 : 24|8@1+ (30,0) [0|7500] "rpm" Vector__XXX
 SG_ VCFRONT_pumpPowertrainRPMTarget m21 : 32|8@1+ (30,0) [0|7500] "rpm" Vector__XXX
 SG_ VCFRONT_coolantFlowChillerTarget m21 : 40|8@1+ (0.161,0) [0|25] "LPM" Vector__XXX
 SG_ VCFRONT_radiatorFanRPMTarget m21 : 48|8@1+ (40,0) [0|10000] "rpm" Vector__XXX
 SG_ VCFRONT_batteryDischArbState m21 : 56|3@1+ (1,0) [0|7] "" Vector__XXX
 SG_ VCFRONT_preventReEntryTillNexthp m21 : 59|1@1+ (1,0) [0|1] "" Vector__XXX
 SG_ VCFRONT_chillerBattHeatingPowerA m21 : 60|1@1+ (1,0) [0|1] "" Vector__XXX
 SG_ VCFRONT_isExpectedQChillerVeryHi m21 : 61|1@1+ (1,0) [0|1] "" Vector__XXX
 SG_ VCFRONT_superheatProtectionLimit m25 : 5|10@1+ (0.1,0) [0|60] "degC" Vector__XXX
 SG_ VCFRONT_chillerDemandWatts m25 : 16|8@1+ (100,0) [0|20000] "W" Vector__XXX
 SG_ VCFRONT_nominalTevapHWLimit m25 : 24|7@1+ (0.5,0) [0|60] "degC" Vector__XXX
 SG_ VCFRONT_solverIterTotalLoad m25 : 32|6@1+ (2,0) [0|126] "" Vector__XXX
 SG_ VCFRONT_battCoolEvapEnableDelay m25 : 38|1@1+ (1,0) [0|1] "" Vector__XXX
 SG_ VCFRONT_solverIterFeedforward m25 : 40|6@1+ (2,0) [0|126] "" Vector__XXX
 SG_ VCFRONT_ambientTempState m25 : 46|2@1+ (1,0) [0|3] "" Vector__XXX
 SG_ VCFRONT_ambientTempUnlatchReason m25 : 48|3@1+ (1,0) [0|7] "" Vector__XXX
 SG_ VCFRONT_compressorSuctionVaporQu m25 : 51|5@1+ (0.01,0.7) [0.7|1] "-" Vector__XXX
 SG_ VCFRONT_cabinHeatingCOP1MinActiv m25 : 56|7@1+ (10,0) [0|1100] "-" Vector__XXX

BO_ 513 VCFRONT_loggingAndVitals10Hz: 8 VCFRONT
 SG_ VCFRONT_loggingAndVitals10HzInde M : 0|3@1+ (1,0) [0|7] "" Vector__XXX
 SG_ VCFRONT_pumpBatteryRPMActual m0 : 8|8@1+ (30,0) [0|7500] "rpm" Vector__XXX
 SG_ VCFRONT_pumpPowertrainRPMActual m0 : 16|8@1+ (30,0) [0|7500] "rpm" Vector__XXX
 SG_ VCFRONT_radiatorFanRPMActual m0 : 24|8@1+ (40,0) [0|10000] "rpm" Vector__XXX
 SG_ VCFRONT_exvFlowTarget m0 : 32|8@1+ (0.5,0) [0|100] "%" Vector__XXX
 SG_ VCFRONT_activeLouverOpenPosTarg m0 : 40|7@1+ (1,0) [0|100] "%" Vector__XXX
 SG_ VCFRONT_pressureRefrigLiquid m0 : 47|9@1+ (0.08,0) [0|37.25] "bar" Vector__XXX
 SG_ VCFRONT_compSleepRequest m0 : 56|1@1+ (1,0) [0|1] "" Vector__XXX
 SG_ VCFRONT_fanDemand m1 : 3|7@1+ (1,0) [0|100] "%" Vector__XXX
 SG_ VCFRONT_compressorState m1 : 10|2@1+ (1,0) [0|3] "" Vector__XXX
 SG_ VCFRONT_compDemandEvap m1 : 12|7@1+ (1,0) [0|100] "%" Vector__XXX
 SG_ VCFRONT_exvState m1 : 19|4@1+ (1,0) [0|15] "" Vector__XXX
 SG_ VCFRONT_solenoidEvapState m1 : 23|2@1+ (1,0) [0|3] "" Vector__XXX
 SG_ VCFRONT_compDemandChiller m1 : 25|7@1+ (1,0) [0|100] "%" Vector__XXX
 SG_ VCFRONT_coolantValveMode m1 : 32|2@1+ (1,0) [0|3] "" Vector__XXX
 SG_ VCFRONT_compFaultSeverity m1 : 34|2@1+ (1,0) [0|3] "" Vector__XXX
 SG_ VCFRONT_solenoidEngaged m1 : 36|1@1+ (1,0) [0|1] "" Vector__XXX
 SG_ VCFRONT_hpHighSideHX m1 : 37|2@1+ (1,0) [0|3] "" Vector__XXX
 SG_ VCFRONT_hpLowSideHX m1 : 39|2@1+ (1,0) [0|3] "" Vector__XXX
 SG_ VCFRONT_hpDominantLoad m1 : 41|3@1+ (1,0) [0|7] "" Vector__XXX
 SG_ VCFRONT_hpBlendType m1 : 44|2@1+ (1,0) [0|3] "" Vector__XXX
 SG_ VCFRONT_hpQuietModeEnabled m1 : 46|1@1+ (1,0) [0|1] "" Vector__XXX
 SG_ VCFRONT_hpCabinLoadType m1 : 47|2@1+ (1,0) [0|3] "" Vector__XXX
 SG_ VCFRONT_hpBatteryLoadType m1 : 49|2@1+ (1,0) [0|3] "" Vector__XXX
 SG_ VCFRONT_hpReqCoolantMode m1 : 51|3@1+ (1,0) [0|7] "" Vector__XXX
 SG_ VCFRONT_hpReqTransScavenge m1 : 54|1@1+ (1,0) [0|1] "" Vector__XXX
 SG_ VCFRONT_compLiqPumpOutState m1 : 55|3@1+ (1,0) [0|7] "" Vector__XXX
 SG_ VCFRONT_frunkStateDBG m1 : 58|4@1+ (1,0) [0|15] "" Vector__XXX
 SG_ VCFRONT_frunkSwitchGroupState m1 : 62|2@1+ (1,0) [0|3] "" Vector__XXX
 SG_ VCFRONT_chillerExvFlow m2 : 3|8@1+ (0.5,0) [0|100] "%" Vector__XXX
 SG_ VCFRONT_evapExvFlow m2 : 11|8@1+ (0.5,0) [0|100] "%" Vector__XXX
 SG_ VCFRONT_recircExvFlow m2 : 19|8@1+ (0.5,0) [0|100] "%" Vector__XXX
 SG_ VCFRONT_lccExvFlow m2 : 27|8@1+ (0.5,0) [0|100] "%" Vector__XXX
 SG_ VCFRONT_cclExvFlow m2 : 35|8@1+ (0.5,0) [0|100] "%" Vector__XXX
 SG_ VCFRONT_ccrExvFlow m2 : 43|8@1+ (0.5,0) [0|100] "%" Vector__XXX
 SG_ VCFRONT_chillerExvState m2 : 51|4@1+ (1,0) [0|15] "" Vector__XXX
 SG_ VCFRONT_evapExvState m2 : 55|4@1+ (1,0) [0|15] "" Vector__XXX
 SG_ VCFRONT_recircExvState m2 : 59|4@1+ (1,0) [0|15] "" Vector__XXX
 SG_ VCFRONT_chillerExvFlowTarget m3 : 3|8@1+ (0.5,0) [0|100] "%" Vector__XXX
 SG_ VCFRONT_evapExvFlowTarget m3 : 11|8@1+ (0.5,0) [0|100] "%" Vector__XXX
 SG_ VCFRONT_recircExvFlowTarget m3 : 19|8@1+ (0.5,0) [0|100] "%" Vector__XXX
 SG_ VCFRONT_lccExvFlowTarget m3 : 27|8@1+ (0.5,0) [0|100] "%" Vector__XXX
 SG_ VCFRONT_cclExvFlowTarget m3 : 35|8@1+ (0.5,0) [0|100] "%" Vector__XXX
 SG_ VCFRONT_ccrExvFlowTarget m3 : 43|8@1+ (0.5,0) [0|100] "%" Vector__XXX
 SG_ VCFRONT_lccExvState m3 : 51|4@1+ (1,0) [0|15] "" Vector__XXX
 SG_ VCFRONT_cclExvState m3 : 55|4@1+ (1,0) [0|15] "" Vector__XXX
 SG_ VCFRONT_ccrExvState m3 : 59|4@1+ (1,0) [0|15] "" Vector__XXX

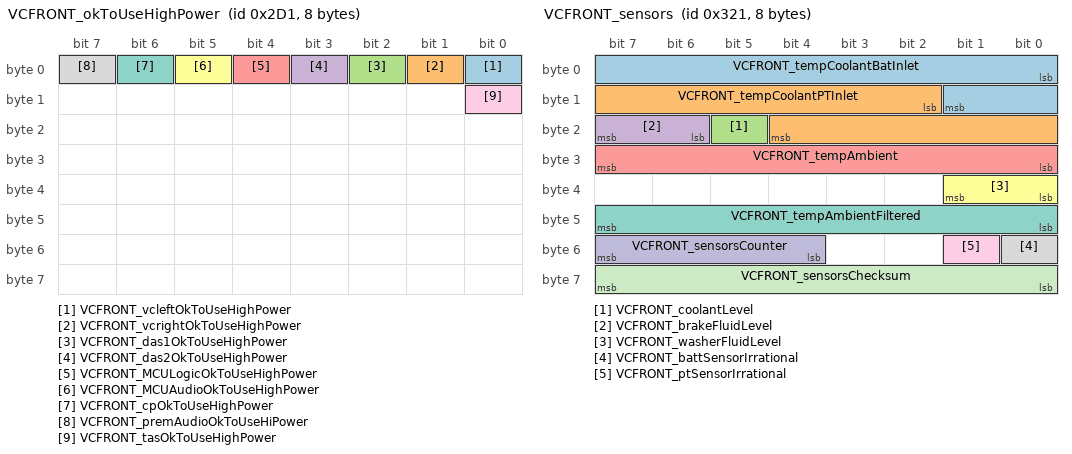
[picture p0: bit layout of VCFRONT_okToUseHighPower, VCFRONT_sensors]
BO_ 721 VCFRONT_okToUseHighPower: 8 VCFRONT
 SG_ VCFRONT_vcleftOkToUseHighPower : 0|1@1+ (1,0) [0|1] "" Vector__XXX
 SG_ VCFRONT_vcrightOkToUseHighPower : 1|1@1+ (1,0) [0|1] "" Vector__XXX
 SG_ VCFRONT_das1OkToUseHighPower : 2|1@1+ (1,0) [0|1] "" Vector__XXX
 SG_ VCFRONT_das2OkToUseHighPower : 3|1@1+ (1,0) [0|1] "" Vector__XXX
 SG_ VCFRONT_MCULogicOkToUseHighPower : 4|1@1+ (1,0) [0|1] "" Vector__XXX
 SG_ VCFRONT_MCUAudioOkToUseHighPower : 5|1@1+ (1,0) [0|1] "" Vector__XXX
 SG_ VCFRONT_cpOkToUseHighPower : 6|1@1+ (1,0) [0|1] "" Vector__XXX
 SG_ VCFRONT_premAudioOkToUseHiPower : 7|1@1+ (1,0) [0|1] "" Vector__XXX
 SG_ VCFRONT_tasOkToUseHighPower : 8|1@1+ (1,0) [0|1] "" Vector__XXX

BO_ 957 VCFRONT_parkedEnergyLoss: 8 VCFRONT
 SG_ VCFRONT_energyLossIndex M : 0|3@1+ (1,0) [0|7] "" Vector__XXX
 SG_ VCFRONT_userEnergyLossSinceDrive m1 : 8|14@1+ (0.01,0) [0|163.83] "kWh" Vector__XXX
 SG_ VCFRONT_preconditioningEner_0001 m1 : 22|14@1+ (0.01,0) [0|163.83] "kWh" Vector__XXX
 SG_ VCFRONT_cabinOverheatEnergy_0001 m1 : 36|14@1+ (0.01,0) [0|163.83] "kWh" Vector__XXX
 SG_ VCFRONT_mobileAppEnergyLoss_0001 m1 : 50|14@1+ (0.01,0) [0|163.83] "kWh" Vector__XXX
 SG_ VCFRONT_summonStandbyEnergy_0001 m2 : 8|14@1+ (0.01,0) [0|163.83] "kWh" Vector__XXX
 SG_ VCFRONT_sentryModeEnergyLos_0001 m2 : 22|14@1+ (0.01,0) [0|163.83] "kWh" Vector__XXX
 SG_ VCFRONT_backgroundEnergyLos_0001 m2 : 36|14@1+ (0.01,0) [0|163.83] "kWh" Vector__XXX
 SG_ VCFRONT_evapDryingEnergyLos_0001 m2 : 50|14@1+ (0.01,0) [0|163.83] "kWh" Vector__XXX
 SG_ VCFRONT_userEnergyLossSinceCharg m3 : 8|14@1+ (0.01,0) [0|163.83] "kWh" Vector__XXX
 SG_ VCFRONT_preconditioningEnergyLos m3 : 22|14@1+ (0.01,0) [0|163.83] "kWh" Vector__XXX
 SG_ VCFRONT_cabinOverheatEnergyLossS m3 : 36|14@1+ (0.01,0) [0|163.83] "kWh" Vector__XXX
 SG_ VCFRONT_mobileAppEnergyLossSince m3 : 50|14@1+ (0.01,0) [0|163.83] "kWh" Vector__XXX
 SG_ VCFRONT_summonStandbyEnergyLossS m4 : 8|14@1+ (0.01,0) [0|163.83] "kWh" Vector__XXX
 SG_ VCFRONT_sentryModeEnergyLossSinc m4 : 22|14@1+ (0.01,0) [0|163.83] "kWh" Vector__XXX
 SG_ VCFRONT_backgroundEnergyLossSinc m4 : 36|14@1+ (0.01,0) [0|163.83] "kWh" Vector__XXX
 SG_ VCFRONT_evapDryingEnergyLossSinc m4 : 50|14@1+ (0.01,0) [0|163.83] "kWh" Vector__XXX

BO_ 260 VCFRONT_partyDebug: 8 VCFRONT
 SG_ VCFRONT_vcleftHighPower : 0|1@1+ (1,0) [0|1] "" Vector__XXX
 SG_ VCFRONT_vcrightHighPower : 1|1@1+ (1,0) [0|1] "" Vector__XXX
 SG_ VCFRONT_uiHighPower : 2|1@1+ (1,0) [0|1] "" Vector__XXX
 SG_ VCFRONT_5VAStable : 3|1@1+ (1,0) [0|1] "" Vector__XXX
 SG_ VCFRONT_5VBStable : 4|1@1+ (1,0) [0|1] "" Vector__XXX
 SG_ VCFRONT_12VAStable : 5|1@1+ (1,0) [0|1] "" Vector__XXX
 SG_ VCFRONT_12VBStable : 6|1@1+ (1,0) [0|1] "" Vector__XXX
 SG_ VCFRONT_railA : 7|1@1+ (1,0) [0|1] "" Vector__XXX
 SG_ VCFRONT_railB : 8|1@1+ (1,0) [0|1] "" Vector__XXX
 SG_ VCFRONT_chargePumpStable : 9|1@1+ (1,0) [0|1] "" Vector__XXX
 SG_ VCFRONT_vehicleSM : 10|5@1+ (1,0) [0|31] "" Vector__XXX
 SG_ VCFRONT_revBattFault : 15|1@1+ (1,0) [0|1] "" Vector__XXX
 SG_ VCFRONT_battSM : 16|4@1+ (1,0) [0|15] "" Vector__XXX
 SG_ VCFRONT_U13Init : 20|1@1+ (1,0) [0|1] "" Vector__XXX
 SG_ VCFRONT_U16Init : 21|1@1+ (1,0) [0|1] "" Vector__XXX
 SG_ VCFRONT_anyVehLoadShedActiveDBG : 22|1@1+ (1,0) [0|1] "" Vector__XXX
 SG_ VCFRONT_battVoltage : 24|12@1+ (0.005443676,0) [0|22.29185322] "V" Vector__XXX
 SG_ VCFRONT_battCurrent : 40|16@1- (0.005,0) [-163.84|163.835] "A" Vector__XXX

BO_ 801 VCFRONT_sensors: 8 VCFRONT
 SG_ VCFRONT_tempCoolantBatInlet : 0|10@1+ (0.125,-40) [-40|85] "degC" Vector__XXX
 SG_ VCFRONT_tempCoolantPTInlet : 10|11@1+ (0.125,-40) [-40|200] "degC" Vector__XXX
 SG_ VCFRONT_coolantLevel : 21|1@1+ (1,0) [0|1] "" Vector__XXX
 SG_ VCFRONT_brakeFluidLevel : 22|2@1+ (1,0) [0|3] "" Vector__XXX
 SG_ VCFRONT_tempAmbient : 24|8@1+ (0.5,-40) [-40|80] "degC" Vector__XXX
 SG_ VCFRONT_washerFluidLevel : 32|2@1+ (1,0) [0|3] "" Vector__XXX
 SG_ VCFRONT_tempAmbientFiltered : 40|8@1+ (0.5,-40) [-40|80] "degC" Vector__XXX
 SG_ VCFRONT_battSensorIrrational : 48|1@1+ (1,0) [0|1] "" Vector__XXX
 SG_ VCFRONT_ptSensorIrrational : 49|1@1+ (1,0) [0|1] "" Vector__XXX
 SG_ VCFRONT_sensorsCounter : 52|4@1+ (1,0) [0|15] "" Vector__XXX
 SG_ VCFRONT_sensorsChecksum : 56|8@1+ (1,0) [0|255] "" Vector__XXX

BO_ 737 VCFRONT_status: 8 VCFRONT
 SG_ VCFRONT_statusIndex M : 0|3@1+ (1,0) [0|7] "" Vector__XXX
 SG_ VCFRONT_frunkLatchStatus m0 : 3|4@1+ (1,0) [0|15] "" Vector__XXX
 SG_ VCFRONT_wiperSpeed m0 : 8|4@1+ (1,0) [0|15] "" Vector__XXX
 SG_ VCFRONT_wiperPosition m0 : 12|3@1+ (1,0) [0|7] "" Vector__XXX
 SG_ VCFRONT_wiperBlocked m0 : 15|1@1+ (1,0) [0|1] "" Vector__XXX
 SG_ VCFRONT_wiperState m0 : 16|4@1+ (1,0) [0|15] "" Vector__XXX
 SG_ VCFRONT_crashDetectedType m0 : 20|2@1+ (1,0) [0|3] "" Vector__XXX
 SG_ VCFRONT_crashState m0 : 22|2@1+ (1,0) [0|3] "" Vector__XXX
 SG_ VCFRONT_crashUnlockOverrideSet m0 : 24|1@1+ (1,0) [0|1] "" Vector__XXX
 SG_ VCFRONT_washPumpState m0 : 25|2@1+ (1,0) [0|3] "" Vector__XXX
 SG_ VCFRONT_turnIndicatorControlType m0 : 27|2@1+ (1,0) [0|3] "" Vector__XXX
 SG_ VCFRONT_wiperHealth m0 : 32|3@1+ (1,0) [0|7] "" Vector__XXX
 SG_ VCFRONT_frunkLatchCurrent m0 : 40|8@1- (0.157480314374,0) [-10|10] "A" Vector__XXX
 SG_ VCFRONT_frunkInteriorRelSwitch m0 : 48|1@1+ (1,0) [0|1] "" Vector__XXX
 SG_ VCFRONT_anyClosureOpen m0 : 49|1@1+ (1,0) [0|1] "" Vector__XXX
 SG_ VCFRONT_anyDoorOpen m0 : 50|1@1+ (1,0) [0|1] "" Vector__XXX
 SG_ VCFRONT_hornOn m0 : 51|1@1+ (1,0) [0|1] "" Vector__XXX
 SG_ VCFRONT_radarHeaterState m0 : 52|3@1+ (1,0) [0|7] "" Vector__XXX
 SG_ VCFRONT_trunkExteriorWakeSwitch m0 : 55|1@1+ (1,0) [0|1] "" Vector__XXX
 SG_ VCFRONT_passengerBuckleStatus m0 : 57|1@1+ (1,0) [0|1] "" Vector__XXX
 SG_ VCFRONT_frunkLatchType m0 : 58|2@1+ (1,0) [0|3] "" Vector__XXX
 SG_ VCFRONT_headlampLeftFanStatus m0 : 60|1@1+ (1,0) [0|1] "" Vector__XXX
 SG_ VCFRONT_headlampRightFanStatus m0 : 61|1@1+ (1,0) [0|1] "" Vector__XXX
 SG_ VCFRONT_frunkAccessPost m0 : 62|1@1+ (1,0) [0|1] "" Vector__XXX
 SG_ VCFRONT_isActiveHeatingBattery m0 : 63|1@1+ (1,0) [0|1] "" Vector__XXX
 SG_ VCFRONT_iBoosterWakeLine m1 : 3|1@1+ (1,0) [0|1] "" Vector__XXX
 SG_ VCFRONT_epasWakeLine m1 : 4|1@1+ (1,0) [0|1] "" Vector__XXX
 SG_ VCFRONT_iBoosterStateDBG m1 : 5|3@1+ (1,0) [0|7] "" Vector__XXX
 SG_ VCFRONT_vehicleStatusDBG m1 : 8|5@1+ (1,0) [0|31] "" Vector__XXX
 SG_ VCFRONT_timeSpentSleeping m1 : 13|10@1+ (1,0) [0|1023] "s" Vector__XXX
 SG_ VCFRONT_sleepCurrent m1 : 24|12@1+ (0.125,-511.875) [-511.875|-0.125] "mA" Vector__XXX
 SG_ VCFRONT_hibernationState m1 : 36|3@1+ (1,0) [0|7] "" Vector__XXX
 SG_ VCFRONT_wiperECUType m1 : 40|2@1+ (1,0) [0|3] "" Vector__XXX
 SG_ VCFRONT_wiperHeaterState m1 : 42|3@1+ (1,0) [0|7] "" Vector__XXX
 SG_ VCFRONT_occupantCount m1 : 45|3@1+ (1,0) [0|7] "" Vector__XXX
 SG_ VCFRONT_closureEasterEggState m1 : 48|3@1+ (1,0) [0|7] "" Vector__XXX
 SG_ VCFRONT_espWakeLine m1 : 51|1@1+ (1,0) [0|1] "" Vector__XXX
 SG_ VCFRONT_allowEvapInLowAmbient m1 : 52|1@1+ (1,0) [0|1] "" Vector__XXX
 SG_ VCFRONT_potentialRadiatorSteam m1 : 53|1@1+ (1,0) [0|1] "" Vector__XXX
 SG_ VCFRONT_potentialRadiatorSteamUI m1 : 54|1@1+ (1,0) [0|1] "" Vector__XXX
 SG_ VCFRONT_hvacReqOffForFasterCharg m1 : 55|1@1+ (1,0) [0|1] "" Vector__XXX
 SG_ VCFRONT_homelinkV2Response0 m2 : 8|8@1+ (1,0) [0|255] "" Vector__XXX
 SG_ VCFRONT_homelinkV2Response1 m2 : 16|8@1+ (1,0) [0|255] "" Vector__XXX
 SG_ VCFRONT_homelinkV2Response2 m2 : 24|8@1+ (1,0) [0|255] "" Vector__XXX
 SG_ VCFRONT_homelinkV2Response3 m2 : 32|8@1+ (1,0) [0|255] "" Vector__XXX
 SG_ VCFRONT_homelinkV2Response4 m2 : 40|8@1+ (1,0) [0|255] "" Vector__XXX
 SG_ VCFRONT_homelinkCommStatus m2 : 48|2@1+ (1,0) [0|3] "" Vector__XXX
 SG_ VCFRONT_maxEvapHeatRejection m3 : 8|8@1+ (65,0) [0|16575] "W" Vector__XXX
 SG_ VCFRONT_minEvapHeatRejection m3 : 16|8@1+ (15,0) [0|3800] "W" Vector__XXX
 SG_ VCFRONT_freezeEvapITerm m3 : 24|1@1+ (1,0) [0|1] "" Vector__XXX
 SG_ VCFRONT_isEvapOperationAllowed m3 : 25|1@1+ (1,0) [0|1] "" Vector__XXX
 SG_ VCFRONT_chillerDemandActive m3 : 26|1@1+ (1,0) [0|1] "" Vector__XXX
 SG_ VCFRONT_compPerfRecoveryLimited m3 : 27|1@1+ (1,0) [0|1] "" Vector__XXX
 SG_ VCFRONT_hvacModeNotAttainable m3 : 28|1@1+ (1,0) [0|1] "" Vector__XXX
 SG_ VCFRONT_hasLowRefrigerant m3 : 29|1@1+ (1,0) [0|1] "" Vector__XXX
 SG_ VCFRONT_isColdStartRunning m3 : 30|1@1+ (1,0) [0|1] "" Vector__XXX
 SG_ VCFRONT_isHeatPumpOilPurgeActive m3 : 31|1@1+ (1,0) [0|1] "" Vector__XXX
 SG_ VCFRONT_pressureRefrigSuction m3 : 32|7@1+ (0.125,0) [0|11.5] "bar" Vector__XXX
 SG_ VCFRONT_pressureRefrigDischarge m3 : 40|9@1+ (0.08,0) [0|37.25] "bar" Vector__XXX
 SG_ VCFRONT_hvacPerfTestCommand m3 : 49|3@1+ (1,0) [0|7] "" Vector__XXX
 SG_ VCFRONT_coolantFillRoutineStatus m3 : 52|2@1+ (1,0) [0|3] "" Vector__XXX
 SG_ VCFRONT_refrigFillRoutineStatus m3 : 54|2@1+ (1,0) [0|3] "" Vector__XXX
 SG_ VCFRONT_isCOP1Running m3 : 56|1@1+ (1,0) [0|1] "" Vector__XXX
 SG_ VCFRONT_closeValvesRoutineStatus m3 : 57|2@1+ (1,0) [0|3] "" Vector__XXX
 SG_ VCFRONT_thermalPerfTestRunning m3 : 59|1@1+ (1,0) [0|1] "" Vector__XXX
 SG_ VCFRONT_5VARailStable m4 : 3|1@1+ (1,0) [0|1] "" Vector__XXX
 SG_ VCFRONT_5VBRailStable m4 : 4|1@1+ (1,0) [0|1] "" Vector__XXX
 SG_ VCFRONT_12VARailStable m4 : 5|1@1+ (1,0) [0|1] "" Vector__XXX
 SG_ VCFRONT_12VBRailStable m4 : 6|1@1+ (1,0) [0|1] "" Vector__XXX
 SG_ VCFRONT_railAState m4 : 7|1@1+ (1,0) [0|1] "" Vector__XXX
 SG_ VCFRONT_railBState m4 : 8|1@1+ (1,0) [0|1] "" Vector__XXX
 SG_ VCFRONT_ChargePumpVoltageStable m4 : 9|1@1+ (1,0) [0|1] "" Vector__XXX
 SG_ VCFRONT_PEResetLineState m4 : 10|1@1+ (1,0) [0|1] "" Vector__XXX
 SG_ VCFRONT_HSDInitCompleteU13 m4 : 11|1@1+ (1,0) [0|1] "" Vector__XXX
 SG_ VCFRONT_HSDInitCompleteU16 m4 : 12|1@1+ (1,0) [0|1] "" Vector__XXX
 SG_ VCFRONT_vbatMonitorVoltage m4 : 16|12@1+ (0.005443676,0) [0|22.2864099452] "V" Vector__XXX
 SG_ VCFRONT_AS8510Voltage m4 : 28|12@1+ (0.005443676,0) [0|22.2864099452] "V" Vector__XXX
 SG_ VCFRONT_vbatProt m4 : 40|12@1+ (0.005443676,0) [0|22.29185322] "V" Vector__XXX
 SG_ VCFRONT_logVerbosity m4 : 52|3@1+ (1,0) [0|7] "" Vector__XXX
 SG_ VCFRONT_cabinCoolingCapacityLimi m5 : 6|1@1+ (1,0) [0|1] "" Vector__XXX
 SG_ VCFRONT_cabinHeatingCapacityLimi m5 : 7|1@1+ (1,0) [0|1] "" Vector__XXX
 SG_ VCFRONT_compPowerSupportingHvac m5 : 8|11@1+ (10,0) [0|20470] "W" Vector__XXX
 SG_ VCFRONT_compPowerSupportingPT m5 : 19|11@1+ (10,0) [0|20470] "W" Vector__XXX
 SG_ VCFRONT_maxHeatingPowerLeftCC m5 : 30|7@1+ (100,0) [0|12000] "W" Vector__XXX
 SG_ VCFRONT_maxHeatingPowerRightCC m5 : 37|7@1+ (100,0) [0|12000] "W" Vector__XXX
 SG_ VCFRONT_activeLouverOpenPos m5 : 44|7@1+ (1,0) [0|100] "%" Vector__XXX
 SG_ VCFRONT_activeLouverState m5 : 51|5@1+ (1,0) [0|31] "" Vector__XXX
 SG_ VCFRONT_windshieldCameraHeaterPo m5 : 56|6@1+ (2.5,0) [0|155] "W" Vector__XXX

BO_ 1349 VCFRONT_systemStatus: 8 VCFRONT
 SG_ VCFRONT_systemStatusMuxIndex M : 0|2@1+ (1,0) [0|3] "" Vector__XXX
 SG_ VCFRONT_systemStatusCounter : 52|4@1+ (1,0) [0|15] "" Vector__XXX
 SG_ VCFRONT_systemStatusChecksum : 56|8@1+ (1,0) [0|255] "" Vector__XXX
 SG_ VCFRONT_loadShedReason m1 : 3|9@1+ (1,0) [0|511] "" Vector__XXX
 SG_ VCFRONT_VCRightEFuseLoadShedStag m1 : 12|5@1+ (1,0) [0|31] "" Vector__XXX
 SG_ VCFRONT_VCLeftEFuseLoadShedStage m1 : 20|5@1+ (1,0) [0|31] "" Vector__XXX
 SG_ VCFRONT_DCDCSaturationLoadShedSt m1 : 28|5@1+ (1,0) [0|31] "" Vector__XXX
 SG_ VCFRONT_vehicleLoadShedStage m1 : 36|2@1+ (1,0) [0|3] "" Vector__XXX
 SG_ VCFRONT_HVFaultVehicleLoadShedRe m1 : 38|1@1+ (1,0) [0|1] "" Vector__XXX
 SG_ VCFRONT_postCrashVehicleLoadShed m1 : 39|1@1+ (1,0) [0|1] "" Vector__XXX
 SG_ VCFRONT_HVFaultVehicleLoadShedAc m1 : 40|1@1+ (1,0) [0|1] "" Vector__XXX
 SG_ VCFRONT_factoryVehicleLoadShedAc m1 : 41|1@1+ (1,0) [0|1] "" Vector__XXX
 SG_ VCFRONT_anyVehicleLoadShedActive m1 : 42|1@1+ (1,0) [0|1] "" Vector__XXX
 SG_ VCFRONT_DIVehLoadShedActive m1 : 43|1@1+ (1,0) [0|1] "" Vector__XXX
 SG_ VCFRONT_HVFaultLoadShedStateDBG m1 : 44|2@1+ (1,0) [0|3] "" Vector__XXX
 SG_ VCFRONT_LVUnhealthyVehicleLoadSh m1 : 46|1@1+ (1,0) [0|1] "" Vector__XXX
 SG_ VCFRONT_loadShedStsCondenserFan m2 : 3|1@1+ (1,0) [0|1] "" Vector__XXX
 SG_ VCFRONT_loadShedStsPTPump m2 : 6|1@1+ (1,0) [0|1] "" Vector__XXX
 SG_ VCFRONT_loadShedMCUAudio m2 : 10|1@1+ (1,0) [0|1] "" Vector__XXX
 SG_ VCFRONT_loadShedHVDownTriggerDBG m2 : 11|1@1+ (1,0) [0|1] "" Vector__XXX
 SG_ VCFRONT_loadShedPCSSatTriggerDBG m2 : 12|1@1+ (1,0) [0|1] "" Vector__XXX
 SG_ VCFRONT_loadShedStsBatteryPump m2 : 13|1@1+ (1,0) [0|1] "" Vector__XXX
 SG_ VCFRONT_loadShedStsAPGlassHeater m2 : 14|1@1+ (1,0) [0|1] "" Vector__XXX
 SG_ VCFRONT_loadShedStsMCUGraphics m2 : 15|1@1+ (1,0) [0|1] "" Vector__XXX
 SG_ VCFRONT_IBSCurrentRMS_loadShed m2 : 16|7@1+ (0.05,0) [0|6.35] "A" Vector__XXX
 SG_ VCFRONT_loadShedAhLeakyBktCntDBG m2 : 23|9@1+ (0.001,0) [0|0.511] "Ah" Vector__XXX
 SG_ VCFRONT_loadShedPcs m2 : 33|1@1+ (1,0) [0|1] "" Vector__XXX
 SG_ VCFRONT_loadShedGTWDownstrmRails m2 : 35|1@1+ (1,0) [0|1] "" Vector__XXX
 SG_ VCFRONT_loadShedPCSMIATriggerDBG m2 : 36|1@1+ (1,0) [0|1] "" Vector__XXX
 SG_ VCFRONT_loadShedTAS m2 : 37|1@1+ (1,0) [0|1] "" Vector__XXX
 SG_ VCFRONT_loadShedBackStopBktCntDB m2 : 38|5@1+ (0.05,0) [0|1.55] "Ah" Vector__XXX
 SG_ VCFRONT_loadShedPCSLeakyBktCtDBG m2 : 44|6@1+ (100,0) [0|6300] "mV" Vector__XXX
 SG_ VCFRONT_loadShedUI m2 : 50|1@1+ (1,0) [0|1] "" Vector__XXX
 SG_ VCFRONT_loadShedAutoPilot m2 : 51|1@1+ (1,0) [0|1] "" Vector__XXX

BO_ 929 VCFRONT_vehicleStatus: 8 VCFRONT
 SG_ VCFRONT_vehicleStatusMuxIndex M : 0|1@1+ (1,0) [0|1] "" Vector__XXX
 SG_ VCFRONT_vehicleStatusCounter : 52|4@1+ (1,0) [0|15] "" Vector__XXX
 SG_ VCFRONT_vehicleStatusChecksum : 56|8@1+ (1,0) [0|255] "" Vector__XXX
 SG_ VCFRONT_preconditionRequest m0 : 1|1@1+ (1,0) [0|1] "" Vector__XXX
 SG_ VCFRONT_APGlassHeaterState m0 : 2|3@1+ (1,0) [0|7] "" Vector__XXX
 SG_ VCFRONT_thermalSystemType m0 : 5|1@1+ (1,0) [0|1] "" Vector__XXX
 SG_ VCFRONT_standbySupplySupported m0 : 6|1@1+ (1,0) [0|1] "" Vector__XXX
 SG_ VCFRONT_driverPresent m0 : 7|1@1+ (1,0) [0|1] "" Vector__XXX
 SG_ VCFRONT_passengerPresent m0 : 8|1@1+ (1,0) [0|1] "" Vector__XXX
 SG_ VCFRONT_accPlusAvailable m0 : 9|1@1+ (1,0) [0|1] "" Vector__XXX
 SG_ VCFRONT_diPowerOnState m0 : 10|3@1+ (1,0) [0|7] "" Vector__XXX
 SG_ VCFRONT_12vStatusForDrive m0 : 14|2@1+ (1,0) [0|3] "" Vector__XXX
 SG_ VCFRONT_dcr12VMilliOhms m0 : 16|8@1+ (1,0) [0|255] "mOhm" Vector__XXX
 SG_ VC_userPresenceState m0 : 24|2@1+ (1,0) [0|3] "" Vector__XXX
 SG_ VCFRONT_factoryLimitsOverrideOk m0 : 27|1@1+ (1,0) [0|1] "" Vector__XXX
 SG_ VCFRONT_ota12VSupportRequest m0 : 29|1@1+ (1,0) [0|1] "" Vector__XXX
 SG_ VCFRONT_driverBuckleStatus m0 : 30|1@1+ (1,0) [0|1] "" Vector__XXX
 SG_ VCFRONT_driverDoorStatus m0 : 31|1@1+ (1,0) [0|1] "" Vector__XXX
 SG_ VCFRONT_driverUnbuckled m0 : 32|2@1+ (1,0) [0|3] "" Vector__XXX
 SG_ VCFRONT_passengerUnbuckled m0 : 34|2@1+ (1,0) [0|3] "" Vector__XXX
 SG_ VCFRONT_2RowLeftUnbuckled m0 : 36|2@1+ (1,0) [0|3] "" Vector__XXX
 SG_ VCFRONT_2RowCenterUnbuckled m0 : 38|2@1+ (1,0) [0|3] "" Vector__XXX
 SG_ VCFRONT_2RowRightUnbuckled m0 : 40|2@1+ (1,0) [0|3] "" Vector__XXX
 SG_ VCFRONT_pcsEFuseVoltage m0 : 42|10@1+ (0.1,0) [0|102.2] "V" Vector__XXX
 SG_ VCFRONT_bmsHvChargeEnable m1 : 1|1@1+ (1,0) [0|1] "" Vector__XXX
 SG_ VCFRONT_3RowLeftUnbuckled m1 : 2|2@1+ (1,0) [0|3] "" Vector__XXX
 SG_ VCFRONT_3RowRightUnbuckled m1 : 4|2@1+ (1,0) [0|3] "" Vector__XXX
 SG_ VCFRONT_maxBattHeatRejection m1 : 6|10@1+ (30,0) [0|30690] "W" Vector__XXX
 SG_ VCFRONT_hvacReqBattCoolOutTemp m1 : 16|9@1+ (0.1,40) [40|91.1] "degC" Vector__XXX
 SG_ VCFRONT_PCSCurrent m1 : 25|13@1- (0.1,0) [-409.6|409.5] "A" Vector__XXX
 SG_ VCFRONT_refSystemNominal m1 : 38|1@1+ (1,0) [0|1] "" Vector__XXX
 SG_ VCFRONT_driverEnteredCabinEstima m1 : 39|1@1+ (1,0) [0|1] "" Vector__XXX
 SG_ VCFRONT_anySWEFuseActive m1 : 40|1@1+ (1,0) [0|1] "" Vector__XXX
 SG_ VCFRONT_hpBattHeatingPowerTrgt m1 : 41|7@1+ (100,0) [0|10000] "W" Vector__XXX

BO_ 507 VCLEFT_TLCStatus: 8 VCLEFT
 SG_ VCLEFT_TLCStatusIndex M : 0|2@1+ (1,0) [0|3] "" Vector__XXX
 SG_ VCLEFT_TLCTemperature m1 : 2|8@1- (1,68) [-59|195] "degC" Vector__XXX
 SG_ VCLEFT_TLCLeftTurnVoltage m1 : 10|8@1+ (0.1,0) [0|25.4] "V" Vector__XXX
 SG_ VCLEFT_TLCRightTurnVoltage m1 : 18|8@1+ (0.1,0) [0|25.4] "V" Vector__XXX
 SG_ VCLEFT_TLCState_LeftTurn m1 : 26|3@1+ (1,0) [0|7] "" Vector__XXX
 SG_ VCLEFT_TLCState_RightTurn m1 : 29|3@1+ (1,0) [0|7] "" Vector__XXX
 SG_ VCLEFT_TLCState_Tail m1 : 32|3@1+ (1,0) [0|7] "" Vector__XXX
 SG_ VCLEFT_TLCState_Stop m1 : 35|3@1+ (1,0) [0|7] "" Vector__XXX
 SG_ VCLEFT_TLCState_Fog m1 : 38|3@1+ (1,0) [0|7] "" Vector__XXX
 SG_ VCLEFT_TLCState_Reverse m1 : 41|3@1+ (1,0) [0|7] "" Vector__XXX

BO_ 2013 VCLEFT_alertLog: 8 VCLEFT
 SG_ VCLEFT_alertID M : 0|10@1+ (1,0) [0|1023] "" Vector__XXX
 SG_ VCLEFT_alertState : 15|1@1+ (1,0) [0|1] "" Vector__XXX
 SG_ VCLEFT_a001_InternalWatchdog m1 : 16|1@1+ (1,0) [0|1] "" Vector__XXX
 SG_ VCLEFT_a002_CPUUndervoltage m2 : 16|1@1+ (1,0) [0|1] "" Vector__XXX
 SG_ VCLEFT_a002_PowerOnReset m2 : 17|1@1+ (1,0) [0|1] "" Vector__XXX
 SG_ VCLEFT_a010_UnderVoltageDetected m10 : 16|1@1+ (1,0) [0|1] "" Vector__XXX
 SG_ VCLEFT_a010_UnderVoltageTimeout m10 : 17|1@1+ (1,0) [0|1] "" Vector__XXX
 SG_ VCLEFT_a015_NVMMMemOverflow m15 : 16|1@1+ (1,0) [0|1] "" Vector__XXX
 SG_ VCLEFT_a015_NVMMFilesystemError m15 : 17|1@1+ (1,0) [0|1] "" Vector__XXX
 SG_ VCLEFT_a015_NVMMRecordIDError m15 : 18|1@1+ (1,0) [0|1] "" Vector__XXX
 SG_ VCLEFT_a057_VEH_cpControl m57 : 16|1@1+ (1,0) [0|1] "" Vector__XXX
 SG_ VCLEFT_a059_voltageDrop m59 : 16|12@1+ (0.005443676,0) [0|22.29185322] "" Vector__XXX
 SG_ VCLEFT_a059_resistanceEstimate m59 : 28|12@1+ (0.00244,0) [0|9.9918] "" Vector__XXX
 SG_ VCLEFT_a059_current m59 : 40|12@1+ (0.05,0) [0|204.75] "" Vector__XXX
 SG_ VCLEFT_a063_switchChannel m63 : 16|8@1+ (1,0) [0|255] "" Vector__XXX
 SG_ VCLEFT_a063_switchType m63 : 24|8@1+ (1,0) [0|255] "" Vector__XXX
 SG_ VCLEFT_a063_ADCVoltage m63 : 32|8@1+ (0.025,0) [0|6.375] "" Vector__XXX
 SG_ VCLEFT_a063_disconnected m63 : 40|1@1+ (1,0) [0|1] "" Vector__XXX
 SG_ VCLEFT_a063_indeterminate m63 : 41|1@1+ (1,0) [0|1] "" Vector__XXX
 SG_ VCLEFT_a063_stuckActive m63 : 42|1@1+ (1,0) [0|1] "" Vector__XXX
 SG_ VCLEFT_a063_faulted m63 : 43|1@1+ (1,0) [0|1] "" Vector__XXX
 SG_ VCLEFT_a082_RIPC_epbPrivateState m82 : 16|1@1+ (1,0) [0|1] "" Vector__XXX
 SG_ VCLEFT_a082_RIPC_remoteHSD m82 : 17|1@1+ (1,0) [0|1] "" Vector__XXX
 SG_ VCLEFT_a082_RIPC_railStatus m82 : 18|1@1+ (1,0) [0|1] "" Vector__XXX
 SG_ VCLEFT_a082_RIPC_remoteMux m82 : 19|1@1+ (1,0) [0|1] "" Vector__XXX
 SG_ VCLEFT_a083_LIPC_epbPrivateState m83 : 16|1@1+ (1,0) [0|1] "" Vector__XXX
 SG_ VCLEFT_a083_LIPC_remoteHSD m83 : 17|1@1+ (1,0) [0|1] "" Vector__XXX
 SG_ VCLEFT_a083_LIPC_railStatus m83 : 18|1@1+ (1,0) [0|1] "" Vector__XXX
 SG_ VCLEFT_a083_LIPC_HSDFaults m83 : 19|1@1+ (1,0) [0|1] "" Vector__XXX
 SG_ VCLEFT_a084_CH_StatusC m84 : 16|1@1+ (1,0) [0|1] "" Vector__XXX
 SG_ VCLEFT_a085_PARTY_buttonStatus m85 : 16|1@1+ (1,0) [0|1] "" Vector__XXX
 SG_ VCLEFT_a086_VEH_LVBMS_statusHigh m86 : 16|1@1+ (1,0) [0|1] "" Vector__XXX
 SG_ VCLEFT_a086_VEH_LVBMS_statusLow m86 : 17|1@1+ (1,0) [0|1] "" Vector__XXX
 SG_ VCLEFT_a086_VEH_status m86 : 18|1@1+ (1,0) [0|1] "" Vector__XXX
 SG_ VCLEFT_a086_VEH_12VBatteryStatus m86 : 19|1@1+ (1,0) [0|1] "" Vector__XXX
 SG_ VCLEFT_a086_VEH_LVPowerState m86 : 20|1@1+ (1,0) [0|1] "" Vector__XXX
 SG_ VCLEFT_a086_VEH_lightStatus m86 : 21|1@1+ (1,0) [0|1] "" Vector__XXX
 SG_ VCLEFT_a086_VEH_systemStatus m86 : 22|1@1+ (1,0) [0|1] "" Vector__XXX
 SG_ VCLEFT_a086_VEH_thermalStatus m86 : 23|1@1+ (1,0) [0|1] "" Vector__XXX
 SG_ VCLEFT_a086_VEH_vehNm m86 : 24|1@1+ (1,0) [0|1] "" Vector__XXX
 SG_ VCLEFT_a086_BDY_12VBatteryStatus m86 : 63|1@1+ (1,0) [0|1] "" Vector__XXX
 SG_ VCLEFT_a087_VEH_temperature m87 : 16|1@1+ (1,0) [0|1] "" Vector__XXX
 SG_ VCLEFT_a087_VEH_thermalControl m87 : 17|1@1+ (1,0) [0|1] "" Vector__XXX
 SG_ VCLEFT_a087_VEH_torque m87 : 18|1@1+ (1,0) [0|1] "" Vector__XXX
 SG_ VCLEFT_a087_VEH_status m87 : 19|1@1+ (1,0) [0|1] "" Vector__XXX
 SG_ VCLEFT_a087_PARTY_torque m87 : 20|1@1+ (1,0) [0|1] "" Vector__XXX
 SG_ VCLEFT_a087_PARTY_status m87 : 21|1@1+ (1,0) [0|1] "" Vector__XXX
 SG_ VCLEFT_a087_PARTY_temperature m87 : 22|1@1+ (1,0) [0|1] "" Vector__XXX
 SG_ VCLEFT_a087_PARTY_thermalControl m87 : 23|1@1+ (1,0) [0|1] "" Vector__XXX
 SG_ VCLEFT_a088_VEH_temperature m88 : 16|1@1+ (1,0) [0|1] "" Vector__XXX
 SG_ VCLEFT_a088_VEH_thermalControl m88 : 17|1@1+ (1,0) [0|1] "" Vector__XXX
 SG_ VCLEFT_a088_VEH_torque m88 : 18|1@1+ (1,0) [0|1] "" Vector__XXX
 SG_ VCLEFT_a088_VEH_status m88 : 19|1@1+ (1,0) [0|1] "" Vector__XXX
 SG_ VCLEFT_a088_PARTY_torque m88 : 20|1@1+ (1,0) [0|1] "" Vector__XXX
 SG_ VCLEFT_a088_PARTY_status m88 : 21|1@1+ (1,0) [0|1] "" Vector__XXX
 SG_ VCLEFT_a088_PARTY_temperature m88 : 22|1@1+ (1,0) [0|1] "" Vector__XXX
 SG_ VCLEFT_a088_PARTY_thermalControl m88 : 23|1@1+ (1,0) [0|1] "" Vector__XXX
 SG_ VCLEFT_a089_PARTY_party1 m89 : 16|1@1+ (1,0) [0|1] "" Vector__XXX
 SG_ VCLEFT_a089_PARTY_status m89 : 17|1@1+ (1,0) [0|1] "" Vector__XXX
 SG_ VCLEFT_a089_VEH_status m89 : 18|1@1+ (1,0) [0|1] "" Vector__XXX
 SG_ VCLEFT_a089_BDY_party1 m89 : 19|1@1+ (1,0) [0|1] "" Vector__XXX
 SG_ VCLEFT_a089_BDY_status m89 : 20|1@1+ (1,0) [0|1] "" Vector__XXX

CM_ BO_ 753 "Front body controller message: e fuse debug status";
CM_ SG_ 753 VCFRONT_eFuseDebugStatusIndex "Front body controller: e fuse debug status index";
CM_ SG_ 753 VCFRONT_leftControllerState "Front body controller: left controller state";
CM_ SG_ 753 VCFRONT_leftControllerFault "Front body controller: left controller fault";
CM_ SG_ 753 VCFRONT_vcleftSelfTestResult "Reports the result of the most recent self-test of the Vehicle Controller Left (VCLEFT) eFuse.";
CM_ SG_ 753 VCFRONT_leftControllerTemp "Front body controller: left controller temp";
CM_ SG_ 753 VCFRONT_leftControllerEFuseVNFSt "State of the leftController eFuse";
CM_ SG_ 753 VCFRONT_leftControllerEFuseOutpu "Output state of the leftController efuse";
CM_ SG_ 753 VCFRONT_leftControllerEFuse_0002 "Output of the leftController efuse";
CM_ SG_ 753 VCFRONT_leftControllerVoltage "Front body controller: left controller voltage";
CM_ SG_ 753 VCFRONT_leftControllerEFuseBypas "Bypass output state of the leftController efuse";
CM_ SG_ 753 VCFRONT_leftControllerEFuse_0001 "Bypass output of the leftController efuse";
CM_ SG_ 753 VCFRONT_leftControllerCurrent "Front body controller: left controller current";
CM_ SG_ 753 VCFRONT_leftControllerEFuseVNFSe "Front body controller: left controller e fuse VNF self test status";
CM_ SG_ 753 VCFRONT_PCSState "Front body controller: PCS state";
CM_ SG_ 753 VCFRONT_PCSFault "Front body controller: PCS fault";
CM_ SG_ 753 VCFRONT_pcsSelfTestResult "Reports the result of the most recent self-test of the Power Conversion System (PCS) eFuse.";
CM_ SG_ 753 VCFRONT_PCSTemp "Front body controller: PCS temp";
CM_ SG_ 753 VCFRONT_PCSEFuseVNFState "State of the PCS eFuse";
CM_ SG_ 753 VCFRONT_PCSEFuseOutput "Output state of the PCS efuse";
CM_ SG_ 753 VCFRONT_PCSEFuseOutputDesired "Output of the PCS efuse";
CM_ SG_ 753 VCFRONT_PCSVoltage "Voltage of the power conversion system circuit";
CM_ SG_ 753 VCFRONT_PCSEFuseBypass "Bypass output state of the PCS efuse";
CM_ SG_ 753 VCFRONT_PCSEFuseBypassDesired "Bypass output of the PCS efuse";
CM_ SG_ 753 VCFRONT_PCSEFuseVNFSelfTestStatu "Front body controller: PCSE fuse VNF self test status";
CM_ SG_ 753 VCFRONT_iBoosterState "Front body controller: i booster state";
CM_ SG_ 753 VCFRONT_iBoosterFault "Front body controller: i booster fault";
CM_ SG_ 753 VCFRONT_iBoosterSelfTestResult "Reports the result of the most recent self-test of the iBooster eFuse.";
CM_ SG_ 753 VCFRONT_iBoosterTemp "Front body controller: i booster temp";
CM_ SG_ 753 VCFRONT_IBoosterEFuseVNFState "Front body controller: i booster e fuse VNF state";
CM_ SG_ 753 VCFRONT_IBoosterEFuseOutput "Front body controller: i booster e fuse output";
CM_ SG_ 753 VCFRONT_IBoosterEFuseOutputDesir "Front body controller: i booster e fuse output desired";
CM_ SG_ 753 VCFRONT_iBoosterVoltage "Front body controller: i booster voltage";
CM_ SG_ 753 VCFRONT_IBoosterEFuseBypass "Front body controller: i booster e fuse bypass";
CM_ SG_ 753 VCFRONT_IBoosterEFuseBypassDesir "Front body controller: i booster e fuse bypass desired";
CM_ SG_ 753 VCFRONT_iBoosterCurrent "Front body controller: i booster current";
CM_ SG_ 753 VCFRONT_IBoosterEFuseVNFSelfTest "Front body controller: i booster e fuse VNF self test status";
CM_ SG_ 753 VCFRONT_EPAS3PState "State of the primary power steering circuit";
CM_ SG_ 753 VCFRONT_EPAS3PFault "Front body controller: EPAS3 p fault";
CM_ SG_ 753 VCFRONT_EPAS3PSelfTestResult "Reports the result of the most recent self-test of the Electric Power Assisted Steering Primary (EPAS3P) eFuse.";
CM_ SG_ 753 VCFRONT_EPAS3PTemp "Front body controller: EPAS3 p temp";
CM_ SG_ 753 VCFRONT_EPAS3PEFuseVNFState "State of the EPAS3P eFuse";
CM_ SG_ 753 VCFRONT_EPAS3PEFuseOutput "Output state of the EPAS3P efuse";
CM_ SG_ 753 VCFRONT_EPAS3PEFuseOutputDesired "Output of the EPAS3P efuse";
CM_ SG_ 753 VCFRONT_EPAS3PVoltage "Voltage of the primary power steering circuit";
CM_ SG_ 753 VCFRONT_EPAS3PEFuseHardshortThre "Front body controller: EPAS3 PE fuse hardshort threshold dbg";
CM_ SG_ 753 VCFRONT_EPAS3PEFuseBypass "Bypass output state of the EPAS3P efuse";
CM_ SG_ 753 VCFRONT_EPAS3PEFuseBypassDesired "Bypass output of the EPAS3P efuse";
CM_ SG_ 753 VCFRONT_EPAS3PCurrent "Electrical current of the primary power steering circuit";
CM_ SG_ 753 VCFRONT_EPAS3PEFuseVNFSelfTestSt "Front body controller: EPAS3 PE fuse VNF self test status";
CM_ SG_ 753 VCFRONT_EPAS3SState "State of the secondary power steering circuit";
CM_ SG_ 753 VCFRONT_EPAS3SFault "Front body controller: EPAS3 s fault";
CM_ SG_ 753 VCFRONT_EPAS3SSelfTestResult "Reports the result of the most recent self-test of the Electric Power Assisted Steering Secondary (EPAS3S) eFuse.";
CM_ SG_ 753 VCFRONT_EPAS3STemp "Front body controller: EPAS3 s temp";
CM_ SG_ 753 VCFRONT_EPAS3SEFuseVNFState "State of the EPAS3S eFuse";
CM_ SG_ 753 VCFRONT_EPAS3SEFuseOutput "Output state of the EPAS3S efuse";
CM_ SG_ 753 VCFRONT_EPAS3SEFuseOutputDesired "Output of the EPAS3S efuse";
CM_ SG_ 753 VCFRONT_EPAS3SVoltage "Voltage of the secondary power steering circuit";
CM_ SG_ 753 VCFRONT_EPAS3SEFuseBypass "Bypass output state of the EPAS3S efuse";
CM_ SG_ 753 VCFRONT_EPAS3SEFuseBypassDesired "Bypass output of the EPAS3S efuse";
CM_ SG_ 753 VCFRONT_EPAS3SCurrent "Electrical current of the secondary power steering circuit";
CM_ SG_ 753 VCFRONT_EPAS3SEFuseVNFSelfTestSt "Front body controller: EPAS3 SE fuse VNF self test status";
CM_ SG_ 753 VCFRONT_ESPMotorState "Front body controller: ESP motor state";
CM_ SG_ 753 VCFRONT_ESPMotorFault "Front body controller: ESP motor fault";
CM_ SG_ 753 VCFRONT_ESPMotorSelfTestResult "Reports the result of the most recent self-test of the Electronic Stability Program Motor (ESP Motor) eFuse.";
CM_ SG_ 753 VCFRONT_ESPMotorTemp "Front body controller: ESP motor temp";
CM_ SG_ 753 VCFRONT_ESPMotorEFuseVNFState "State of the ESPMotor eFuse";
CM_ SG_ 753 VCFRONT_ESPMotorEFuseOutput "Output state of the ESPMotor efuse";
CM_ SG_ 753 VCFRONT_ESPMotorEFuseOutputDesir "Output of the ESPMotor efuse";
CM_ SG_ 753 VCFRONT_ESPMotorVoltage "Front body controller: ESP motor voltage";
CM_ SG_ 753 VCFRONT_ESPMotorEFuseBypass "Bypass output state of the ESPMotor efuse";
CM_ SG_ 753 VCFRONT_ESPMotorEFuseBypassDesir "Bypass output of the ESPMotor efuse";
CM_ SG_ 753 VCFRONT_ESPMotorCurrent "Front body controller: ESP motor current";
CM_ SG_ 753 VCFRONT_ESPMotorEFuseVNFSelfTest "Front body controller: ESP motor e fuse VNF self test status";
CM_ SG_ 753 VCFRONT_ESPValveState "State of the stability controller motor circuit";
CM_ SG_ 753 VCFRONT_ESPValveFault "Front body controller: ESP valve fault";
CM_ SG_ 753 VCFRONT_ESPValveTemp "Front body controller: ESP valve temp";
CM_ SG_ 753 VCFRONT_ESPValveVoltage "Front body controller: ESP valve voltage";
CM_ SG_ 753 VCFRONT_ESPValveCurrent "Electrical current of the stability controller motor circuit";
CM_ SG_ 753 VCFRONT_autopilot2State "Front body controller: autopilot2 state";
CM_ SG_ 753 VCFRONT_autopilot2Fault "Front body controller: autopilot2 fault";
CM_ SG_ 753 VCFRONT_autopilot2Temp "Front body controller: autopilot2 temp";
CM_ SG_ 753 VCFRONT_autopilot2Voltage "Front body controller: autopilot2 voltage";
CM_ SG_ 753 VCFRONT_autopilot2Current "Front body controller: autopilot2 current";
CM_ SG_ 753 VCFRONT_sleepBypassState "State of the sleep bypass circuit";
CM_ SG_ 753 VCFRONT_sleepBypassFault "Front body controller: sleep bypass fault";
CM_ SG_ 753 VCFRONT_sleepBypassVoltage "Front body controller: sleep bypass voltage";
CM_ SG_ 753 VCFRONT_sleepBypassCurrent "Front body controller: sleep bypass current";
CM_ SG_ 753 VCFRONT_vbatFusedHighState "Front body controller: vbat fused high state";
CM_ SG_ 753 VCFRONT_vbatFusedHighFault "Front body controller: vbat fused high fault";
CM_ SG_ 753 VCFRONT_vbatFusedSelfTestResult "Front body controller: vbat fused self test result";
CM_ SG_ 753 VCFRONT_vbatFusedHighTemp "Front body controller: vbat fused high temp";
CM_ SG_ 753 VCFRONT_vbatFusedHighVoltage "Front body controller: vbat fused high voltage";
CM_ SG_ 753 VCFRONT_vbatFusedHighCurrent "Front body controller: vbat fused high current";
CM_ SG_ 753 VCFRONT_chargedIBSAmpHours "Front body controller: charged IBS amp hours";
CM_ SG_ 753 VCFRONT_dischargedIBSAmpHours "Front body controller: discharged IBS amp hours";
CM_ SG_ 753 VCFRONT_IBSUnfilteredTemperature "Front body controller: IBS unfiltered temperature";
CM_ BO_ 769 "Front body controller message: info";
CM_ SG_ 769 VCFRONT_infoIndex "Front body controller: info index";
CM_ SG_ 769 VCFRONT_infoBuildType "Front body controller: info build type";
CM_ SG_ 769 VCFRONT_infoBuildConfigId "Front body controller: info build config id";
CM_ SG_ 769 VCFRONT_infoHardwareId "Front body controller: info hardware id";
CM_ SG_ 769 VCFRONT_infoComponentId "Front body controller: info component id";
CM_ SG_ 769 VCFRONT_infoPcbaId "Front body controller: info pcba id";
CM_ SG_ 769 VCFRONT_infoAssemblyId "Front body controller: info assembly id";
CM_ SG_ 769 VCFRONT_infoUsageId "Front body controller: info usage id";
CM_ SG_ 769 VCFRONT_infoSubUsageId "Front body controller: info sub usage id";
CM_ SG_ 769 VCFRONT_infoAppCrc "Front body controller: info app crc";
CM_ SG_ 769 VC_infoHCMLAppCRC "Front body controller: info HCML app CRC";
CM_ SG_ 769 VCFRONT_infoAppGitHash "Front body controller: info app git hash";
CM_ SG_ 769 VCFRONT_infoBootGitHash "Front body controller: info boot git hash";
CM_ SG_ 769 VCFRONT_infoPlatformType "Front body controller: info platform type";
CM_ SG_ 769 VCFRONT_infoBootUdsProtoVersion "Front body controller: info boot uds proto version";
CM_ SG_ 769 VCFRONT_infoBootCrc "Front body controller: info boot crc";
CM_ SG_ 769 VC_infoHCMRAppCRC "Front body controller: info HCMR app CRC";
CM_ BO_ 1014 "Front body controller message: light status";
CM_ SG_ 1014 VCFRONT_lowBeamLeftStatus "State of the left headlamp low beam light source";
CM_ SG_ 1014 VCFRONT_lowBeamRightStatus "State of the right headlamp low beam light source";
CM_ SG_ 1014 VCFRONT_highBeamLeftStatus "State of the left headlamp high beam light source";
CM_ SG_ 1014 VCFRONT_highBeamRightStatus "State of the right headlamp high beam light source";
CM_ SG_ 1014 VCFRONT_DRLLeftStatus "Status of the left daytime running light source";
CM_ SG_ 1014 VCFRONT_DRLRightStatus "Status of the right daytime running light source";
CM_ SG_ 1014 VCFRONT_fogLeftStatus "State of the left front fog light source";
CM_ SG_ 1014 VCFRONT_fogRightStatus "State of the right front fog light source";
CM_ SG_ 1014 VCFRONT_sideMarkersStatus "State of the side marker / auxiliary park light sources (left and right are on a shared HSD)";
CM_ SG_ 1014 VCFRONT_sideRepeaterLeftStatus "State of the left side repeater light source";
CM_ SG_ 1014 VCFRONT_sideRepeaterRightStatus "State of the right side repeater light source";
CM_ SG_ 1014 VCFRONT_turnSignalLeftStatus "State of the left front turn signal light source";
CM_ SG_ 1014 VCFRONT_turnSignalRightStatus "State of the right front turn signal light source";
CM_ SG_ 1014 VCFRONT_parkLeftStatus "State of the left position/park light source";
CM_ SG_ 1014 VCFRONT_parkRightStatus "State of the right position/park light source";
CM_ SG_ 1014 VCFRONT_lowBeamLeftReadyForAimin "Front body controller: low beam left ready for aiming";
CM_ SG_ 1014 VCFRONT_lowBeamRightReadyForAimi "Front body controller: low beam right ready for aiming";
CM_ SG_ 1014 VCFRONT_lowBeamsOnForDRL "Shows if the low beam light source is being used to fulfil the daytime running light function (for Canada)";
CM_ SG_ 1014 VC_rightHeadlampHealth "Signal to report whether the right headlamp is powered and communicating";
CM_ SG_ 1014 VC_leftHeadlampHealth "Signal to report whether the left headlamp is powered and communicating";
CM_ SG_ 1014 VCFRONT_lightStatusMuxIndex "Front body controller: light status mux index";
CM_ SG_ 1014 VCFRONT_isAdaptiveHighBeamAvaila "Indication that the conditions (country code, hardware config, etc.) are acceptable to use the advanced driving beam feature.";
CM_ SG_ 1014 VCFRONT_isAdaptiveHighBeamFaulte "Detects if adaptive high beam functionality is unavailable or not operating as expected due to other dependencies.";
CM_ SG_ 1014 VCFRONT_isBendLightingAvailable "Detects if region and hardware conditions currently allow operation of the bend lighting feature.";
CM_ SG_ 1014 VCFRONT_advancedDrivingBeamStatu "Reports the current advanced driving beam system state.";
CM_ SG_ 1014 VCFRONT_headlampBendAngle "Measures the adaptive headlight bend angle.";
CM_ SG_ 1014 VCFRONT_headlampRoadClass "Reports the road class informing the use of dynamic low beams.";
CM_ BO_ 1013 "Front body controller message: lighting";
CM_ SG_ 1013 VCFRONT_indicatorLeftRequest "Front body controller: indicator left request";
CM_ SG_ 1013 VCFRONT_indicatorRightRequest "Front body controller: indicator right request";
CM_ SG_ 1013 VCFRONT_hazardLightRequest "Front body controller: hazard light request";
CM_ SG_ 1013 VCFRONT_ambientLightingBrightnes "Front body controller: ambient lighting brightnes";
CM_ SG_ 1013 VCFRONT_switchLightingBrightness "Front body controller: switch lighting brightness";
CM_ SG_ 1013 VCFRONT_courtesyLightingRequest "Flag to request courtesy lighting";
CM_ SG_ 1013 VCFRONT_hazardSwitchBacklight "Front body controller: hazard switch backlight";
CM_ SG_ 1013 VCFRONT_highBeamControlState "State of the virtual high beam stalk";
CM_ SG_ 1013 VCFRONT_dynamicBrakeLightState "Front body controller: dynamic brake light state";
CM_ SG_ 1013 VCFRONT_lightingCoreState "Core lighting state";
CM_ SG_ 1013 VCFRONT_intHighBeamsFunctionStat "State of the intermittent high beams lighting function";
CM_ SG_ 1013 VCFRONT_latchedHighBeamsFunction "State of the latched high beams lighting function";
CM_ SG_ 1013 VCFRONT_frontFogFunctionState "State of the front fog lighting function";
CM_ SG_ 1013 VCFRONT_headlightsReadyOrTimedOu "Front body controller: headlights ready or timed out";
CM_ SG_ 1013 VCFRONT_turnIndicatorStalk "Front body controller: turn indicator stalk";
CM_ SG_ 1013 VCFRONT_highBeamLatchingState "State of high beam latching";
CM_ SG_ 1013 VCFRONT_lightingCustomState "Custom lighting mode substate";
CM_ SG_ 1013 VC_fastFlashHazardsActive "Front body controller: fast flash hazards active";
CM_ SG_ 1013 VCFRONT_indicatorLeftInternal "Front body controller: indicator left internal";
CM_ SG_ 1013 VCFRONT_indicatorRightInternal "Front body controller: indicator right internal";
CM_ BO_ 1801 "Front body controller message: logging0point1 hz";
CM_ SG_ 1801 VCFRONT_logging0point1HzIndex "Front body controller: logging0point1 hz index";
CM_ SG_ 1801 VC_hcmlFactoryOfOrigin "Tier 1 supplier (Hella) factory of origin of the left headlamp";
CM_ SG_ 1801 VC_hcmlHellaPartNumberStatus "Front body controller: hcml hella part number status";
CM_ SG_ 1801 VC_hcmlHellaPartNumber "Value of the Hella Part Number written into EEPROM in the left headlamp";
CM_ SG_ 1801 VC_hcmlCurrentBinMappingType "Front body controller: hcml current bin mapping type";
CM_ SG_ 1801 VC_hcmlCurrentBin0Value "Front body controller: hcml current bin0 value";
CM_ SG_ 1801 VC_hcmlCurrentBin1Value "Front body controller: hcml current bin1 value";
CM_ SG_ 1801 VC_hcmlCurrentBin2Value "Front body controller: hcml current bin2 value";
CM_ SG_ 1801 VC_hcmlCurrentBin3Value "Front body controller: hcml current bin3 value";
CM_ SG_ 1801 VC_hcmlCurrentBin4Value "Front body controller: hcml current bin4 value";
CM_ SG_ 1801 VC_hcmlCurrentBin5Value "Front body controller: hcml current bin5 value";
CM_ SG_ 1801 VC_hcmlRegionAndSide "Left headlamp EEPROM region and side";
CM_ SG_ 1801 VC_hcmrFactoryOfOrigin "Tier 1 supplier (Hella) factory of origin of the right headlamp";
CM_ SG_ 1801 VC_hcmrHellaPartNumberStatus "Front body controller: hcmr hella part number status";
CM_ SG_ 1801 VC_hcmrHellaPartNumber "Value of the Hella Part Number written into EEPROM in the right headlamp";
CM_ SG_ 1801 VC_hcmrCurrentBinMappingType "Front body controller: hcmr current bin mapping type";
CM_ SG_ 1801 VC_hcmrCurrentBin0Value "Front body controller: hcmr current bin0 value";
CM_ SG_ 1801 VC_hcmrCurrentBin1Value "Front body controller: hcmr current bin1 value";
CM_ SG_ 1801 VC_hcmrCurrentBin2Value "Front body controller: hcmr current bin2 value";
CM_ SG_ 1801 VC_hcmrCurrentBin3Value "Front body controller: hcmr current bin3 value";
CM_ SG_ 1801 VC_hcmrCurrentBin4Value "Front body controller: hcmr current bin4 value";
CM_ SG_ 1801 VC_hcmrCurrentBin5Value "Front body controller: hcmr current bin5 value";
CM_ SG_ 1801 VC_hcmrRegionAndSide "Right headlamp EEPROM region and side";
CM_ BO_ 705 "Front body controller message: logging10 hz";
CM_ SG_ 705 VCFRONT_logging10HzIndex "Front body controller: logging10 hz index";
CM_ SG_ 705 VCFRONT_pumpBatteryOutVoltage "Front body controller: pump battery out voltage";
CM_ SG_ 705 VCFRONT_pumpPowertrainOutVoltage "Front body controller: pump powertrain out voltage";
CM_ SG_ 705 VCFRONT_pumpBatteryInitd "Front body controller: pump battery initd";
CM_ SG_ 705 VCFRONT_pumpPowertrainInitd "Front body controller: pump powertrain initd";
CM_ SG_ 705 VCFRONT_pumpBatteryEnabled "Front body controller: pump battery enabled";
CM_ SG_ 705 VCFRONT_pumpPowertrainEnabled "Front body controller: pump powertrain enabled";
CM_ SG_ 705 VCFRONT_pumpBatteryPowerOn "Front body controller: pump battery power on";
CM_ SG_ 705 VCFRONT_pumpPowertrainPowerOn "Front body controller: pump powertrain power on";
CM_ SG_ 705 VCFRONT_pumpsWake "Front body controller: pumps wake";
CM_ SG_ 705 VCFRONT_pumpBatSpiError "Front body controller: pump bat spi error";
CM_ SG_ 705 VCFRONT_pumpPtSpiError "Front body controller: pump pt spi error";
CM_ SG_ 705 VCFRONT_coolantFlowChillerActual "Front body controller: coolant flow chiller actual";
CM_ SG_ 705 VCFRONT_radiatorFanOutVoltage "Front body controller: radiator fan out voltage";
CM_ SG_ 705 VCFRONT_radiatorFanInitd "Front body controller: radiator fan initd";
CM_ SG_ 705 VCFRONT_radiatorFanEnabled "Indication that the cooling fan is enabled";
CM_ SG_ 705 VCFRONT_radiatorFanPowerOn "Indication that the cooling fan is powered on";
CM_ SG_ 705 VCFRONT_radiatorFanPhaseCurrent "Front body controller: radiator fan phase current";
CM_ SG_ 705 VCFRONT_radiatorFanPhaseIMax "Front body controller: radiator fan phase i max";
CM_ SG_ 705 VCFRONT_thmlFanSpiError "Front body controller: thml fan spi error";
CM_ SG_ 705 VCFRONT_chargeTrapNominalCOP1Bat "Front body controller: charge trap nominal COP1 batt heat";
CM_ SG_ 705 VCFRONT_chargeTrapNominalCOP1Chi "Front body controller: charge trap nominal COP1 chiller batt heat";
CM_ BO_ 897 "Front body controller message: logging1 hz";
CM_ SG_ 897 VCFRONT_logging1HzIndex "Front body controller: logging1 hz index";
CM_ SG_ 897 VCFRONT_modeTransitionID "Front body controller: mode transition ID";
CM_ SG_ 897 VCFRONT_modeDesired "Front body controller: mode desired";
CM_ SG_ 897 VCFRONT_targetPTActiveCool "Front body controller: target PT active cool";
CM_ SG_ 897 VCFRONT_targetPtOptionalActiveCo "Front body controller: target pt optional active cool";
CM_ SG_ 897 VCFRONT_targetPTPassive "Front body controller: target PT passive";
CM_ SG_ 897 VCFRONT_targetBatActiveCool "Front body controller: target bat active cool";
CM_ SG_ 897 VCFRONT_targetBatOptionalActiveC "Front body controller: target bat optional active cool";
CM_ SG_ 897 VCFRONT_targetBatPassive "Front body controller: target bat passive";
CM_ SG_ 897 VCFRONT_targetBatActiveHeat "Active heating temperature target for the battery coolant loop";
CM_ SG_ 897 VCFRONT_condenserPressureLimit "Front body controller: condenser pressure limit";
CM_ SG_ 897 VCFRONT_fanDemandCondenser "Front body controller: fan demand condenser";
CM_ SG_ 897 VCFRONT_fanDemandRadiator "Front body controller: fan demand radiator";
CM_ SG_ 897 VCFRONT_tempRefrigSuction "Refrigerant system suction temperature";
CM_ SG_ 897 VCFRONT_pumpBatteryFETTemp "Front body controller: pump battery FET temp";
CM_ SG_ 897 VCFRONT_pumpPowertrainFETTemp "Front body controller: pump powertrain FET temp";
CM_ SG_ 897 VCFRONT_radiatorFanFETTemp "Front body controller: radiator fan FET temp";
CM_ SG_ 897 VCFRONT_radiatorFanRunReason "Current radiator fan run readon";
CM_ SG_ 897 VCFRONT_coolantValveModeWrong "Front body controller: coolant valve mode wrong";
CM_ SG_ 897 VCFRONT_coolantTempBasedMode "Front body controller: coolant temp based mode";
CM_ SG_ 897 VCFRONT_coolantValveRecalReason "coolant Valve Reason for Recalibration";
CM_ SG_ 897 VCFRONT_coolantValveCountRange "Range of tick counts of the coolant valve actuator";
CM_ SG_ 897 VCFRONT_coolantValveAngleDrift "Estimated angular drift of the coolant valve";
CM_ SG_ 897 VCFRONT_coolantValveRecalCount "coolant Valve Calibration Count";
CM_ SG_ 897 VCFRONT_coolantValveWindupEst "Front body controller: coolant valve windup est";
CM_ SG_ 897 VCFRONT_coolantValveRadBypass "Percent of coolant bypassing the powertrain radiator";
CM_ SG_ 897 VCFRONT_usingModeledPs "Front body controller: using modeled ps";
CM_ SG_ 897 VCFRONT_usingModeledPd "Front body controller: using modeled pd";
CM_ SG_ 897 VCFRONT_usingModeledPl "Front body controller: using modeled pl";
CM_ SG_ 897 VCFRONT_usingModeledTs "Front body controller: using modeled ts";
CM_ SG_ 897 VCFRONT_usingModeledTd "Front body controller: using modeled td";
CM_ SG_ 897 VCFRONT_usingModeledTl "Front body controller: using modeled tl";
CM_ SG_ 897 VCFRONT_hpChargeCableType "Front body controller: hp charge cable type";
CM_ SG_ 897 VCFRONT_subcoolActual "Front body controller: subcool actual";
CM_ SG_ 897 VCFRONT_hpSubcoolTarget "Front body controller: hp subcool target";
CM_ SG_ 897 VCFRONT_CMPDischargeSuperheat "Front body controller: CMP discharge superheat";
CM_ SG_ 897 VCFRONT_hpCOP "Front body controller: hp COP";
CM_ SG_ 897 VCFRONT_lowSideWattsLift "Front body controller: low side watts lift";
CM_ SG_ 897 VCFRONT_tempSuperheatActual "Front body controller: temp superheat actual";
CM_ SG_ 897 VCFRONT_tempSuperheatTarget "Front body controller: temp superheat target";
CM_ SG_ 897 VCFRONT_refrigerantHasBeenFilled "Front body controller: refrigerant has been filled";
CM_ SG_ 897 VCFRONT_refCommissionStatus "Front body controller: ref commission status";
CM_ SG_ 897 VCFRONT_LCCPurgeActive "Reports if Liquid Cooled Condenser (LCC) refrigerant purge is active on the heat pump.";
CM_ SG_ 897 VCFRONT_exteriorQuietModeEnabled "Front body controller: exterior quiet mode enabled";
CM_ SG_ 897 VCFRONT_exteriorQuietModeAllowed "Front body controller: exterior quiet mode allowed";
CM_ SG_ 897 VCFRONT_CCQdotFdFrwrdTarget "Front body controller: CC qdot fd frwrd target";
CM_ SG_ 897 VCFRONT_CCQdotFdbk "Front body controller: CC qdot fdbk";
CM_ SG_ 897 VCFRONT_CCQdotActual "Front body controller: CC qdot actual";
CM_ SG_ 897 VCFRONT_evapFdFrwrdTarget "Front body controller: evap fd frwrd target";
CM_ SG_ 897 VCFRONT_evapFdbk "Front body controller: evap fdbk";
CM_ SG_ 897 VCFRONT_DIQdotA "Front body controller: DI qdot a";
CM_ SG_ 897 VCFRONT_evapFdFrwrdTargetMinimum "Front body controller: evap fd frwrd target minimum";
CM_ SG_ 897 VCFRONT_passiveCoolingState "Front body controller: passive cooling state";
CM_ SG_ 897 VCFRONT_totalLoadCoolingDominant "Front body controller: total load cooling dominant";
CM_ SG_ 897 VCFRONT_feedfwdLoadCoolingDomina "Front body controller: feedfwd load cooling dominant";
CM_ SG_ 897 VCFRONT_modelLoadCoolingDominant "Front body controller: model load cooling dominant";
CM_ SG_ 897 VCFRONT_hpPotentialLowRefrig "Front body controller: hp potential low refrig";
CM_ SG_ 897 VCFRONT_hpRefrigerantPurgeState "Front body controller: hp refrigerant purge state";
CM_ SG_ 897 VCFRONT_estPressureLiq "Front body controller: est pressure liq";
CM_ SG_ 897 VCFRONT_estPressureSuct "Front body controller: est pressure suct";
CM_ SG_ 897 VCFRONT_estPressureDisch "Front body controller: est pressure disch";
CM_ SG_ 897 VCFRONT_estTempLiq "Front body controller: est temp liq";
CM_ SG_ 897 VCFRONT_estTempSuct "Front body controller: est temp suct";
CM_ SG_ 897 VCFRONT_estTempDisch "Front body controller: est temp disch";
CM_ SG_ 897 VCFRONT_estCompressorRpm "Front body controller: est compressor rpm";
CM_ SG_ 897 VCFRONT_estQLift "Front body controller: est q lift";
CM_ SG_ 897 VCFRONT_cycleModelConverged "Front body controller: cycle model converged";
CM_ SG_ 897 VCFRONT_compStandbyCoastDownMode "Front body controller: comp standby coast down mode";
CM_ SG_ 897 VCFRONT_compStandbyShowroomMode "Front body controller: comp standby showroom mode";
CM_ SG_ 897 VCFRONT_chillerExvCalibOffset "Last calibration offset calculated for the Chiller EXV";
CM_ SG_ 897 VCFRONT_evapExvCalibOffset "Last calibration offset calculated for the Evaporator EXV";
CM_ SG_ 897 VCFRONT_recircExvCalibOffset "Last calibration offset calculated for the Recirc EXV";
CM_ SG_ 897 VCFRONT_lccExvCalibOffset "Last calibration offset calculated for the Liquid Cooled Condenser EXV";
CM_ SG_ 897 VCFRONT_ccLeftExvCalibOffset "Last calibration offset calculated for the Left Cabin Condenser EXV";
CM_ SG_ 897 VCFRONT_ccRightExvCalibOffset "Last calibration offset calculated for the Right Cabin Condenser EXV";
CM_ SG_ 897 VCFRONT_chillerEXVControlState "Control State of the chiller electronic expansion valve";
CM_ SG_ 897 VCFRONT_evapEXVControlState "Control State of the evaporator electronic expansion valve";
CM_ SG_ 897 VCFRONT_recircEXVControlState "Control State of the recirc electronic expansion valve";
CM_ SG_ 897 VCFRONT_lccEXVControlState "Control State of the liquid cooled condenser electronic expansion valve";
CM_ SG_ 897 VCFRONT_cclEXVControlState "Control State of the chiller electronic expansion valve";
CM_ SG_ 897 VCFRONT_ccrEXVControlState "Control State of the right cabin condenser electronic expansion valve";
CM_ SG_ 897 VCFRONT_chillerExvCalibFailed "State of the last calibration for the Chiller EXV";
CM_ SG_ 897 VCFRONT_evapExvCalibFailed "State of the last calibration for the Evaporator EXV";
CM_ SG_ 897 VCFRONT_recircExvCalibFailed "State of the last calibration for the Recirc EXV";
CM_ SG_ 897 VCFRONT_lccExvCalibFailed "State of the last calibration for the Liquid Cooled Condenser EXV";
CM_ SG_ 897 VCFRONT_ccLeftExvCalibFailed "State of the last calibration for the Left Cabin Condenser EXV";
CM_ SG_ 897 VCFRONT_ccRightExvCalibFailed "State of the last calibration for the Right Cabin Condenser EXV";
CM_ SG_ 897 VCFRONT_ambientTempSniffActive "Front body controller: ambient temp sniff active";
CM_ SG_ 897 VCFRONT_ambientTempPassiveSniffi "Front body controller: ambient temp passive sniffing";
CM_ SG_ 897 VCFRONT_ambientTempRadSampling "Front body controller: ambient temp rad sampling";
CM_ SG_ 897 VCFRONT_ambientTempSpeedSampling "Front body controller: ambient temp speed sampling";
CM_ SG_ 897 VCFRONT_feedFwdMDotEvaporator "Front body controller: feed fwd m dot evaporator";
CM_ SG_ 897 VCFRONT_hpCabinHeatBatteryHeatAm "Front body controller: hp cabin heat battery heat amb src";
CM_ SG_ 897 VCFRONT_hpCabinHeatBatteryHeatCO "Front body controller: hp cabin heat battery heat COP1";
CM_ SG_ 897 VCFRONT_feedFwdMDotCabinCondense "Feed forward MDOT for the cabin condenser controller.";
CM_ SG_ 897 VCFRONT_feedBackEvapTempControll "Evap temperature controller feedback.";
CM_ SG_ 897 VCFRONT_feedBackDuctTempControll "Feedback for the duct temp controller.";
CM_ SG_ 897 VCFRONT_isSolenoidAllowed "Front body controller: is solenoid allowed";
CM_ SG_ 897 VCFRONT_maxChillerCoolingPower "Front body controller: max chiller cooling power";
CM_ SG_ 897 VCFRONT_fanControlRadCanCool "Front body controller: fan control rad can cool";
CM_ SG_ 897 VCFRONT_fanControlFeedfwdActive "Front body controller: fan control feedfwd active";
CM_ SG_ 897 VCFRONT_fanControlRadiatorUa "Front body controller: fan control radiator ua";
CM_ SG_ 897 VCFRONT_fanControlRadiatorInletT "Front body controller: fan control radiator inlet temp";
CM_ SG_ 897 VCFRONT_hpASBatteryHeatingAllowe "Front body controller: hp AS battery heating allowed";
CM_ SG_ 897 VCFRONT_hpCOP1BatteryHeatingAllo "Front body controller: hp COP1 battery heating allowed";
CM_ SG_ 897 VCFRONT_hpCabinHeatScavengeOnly "Front body controller: hp cabin heat scavenge only";
CM_ SG_ 897 VCFRONT_hpCabinHeatAmbientSource "Front body controller: hp cabin heat ambient source";
CM_ SG_ 897 VCFRONT_hpCabinHeatReheatScaveng "Front body controller: hp cabin heat reheat scavenge";
CM_ SG_ 897 VCFRONT_hpCabinHeatReheatAmbient "Front body controller: hp cabin heat reheat ambient source";
CM_ SG_ 897 VCFRONT_hpCabinHeatBlend "Front body controller: hp cabin heat blend";
CM_ SG_ 897 VCFRONT_hpCabinHeatCOP1 "Front body controller: hp cabin heat COP1";
CM_ SG_ 897 VCFRONT_hpCabinHeatBatteryHeatRe "Front body controller: hp cabin heat battery heat reheat amb src";
CM_ SG_ 897 VCFRONT_hpCabinHeatBatteryCoolRe "Front body controller: hp cabin heat battery cool reheat";
CM_ SG_ 897 VCFRONT_hpCabinCoolEvaporator "Front body controller: hp cabin cool evaporator";
CM_ SG_ 897 VCFRONT_hpCabinCoolEvaporatorReh "Front body controller: hp cabin cool evaporator reheat";
CM_ SG_ 897 VCFRONT_hpBatteryHeatAmbientSour "Front body controller: hp battery heat ambient source";
CM_ SG_ 897 VCFRONT_hpBatteryHeatCOP1 "Front body controller: hp battery heat COP1";
CM_ SG_ 897 VCFRONT_hpBatteryCool "Front body controller: hp battery cool";
CM_ SG_ 897 VCFRONT_hpBatteryCoolCabinConden "Front body controller: hp battery cool cabin condenser CD";
CM_ SG_ 897 VCFRONT_hpBatteryCoolCabinC_0001 "Front body controller: hp battery cool cabin condenser HD";
CM_ SG_ 897 VCFRONT_hpBatteryCoolCabinReheat "Front body controller: hp battery cool cabin reheat";
CM_ SG_ 897 VCFRONT_hpBatteryCoolEvaporator "Front body controller: hp battery cool evaporator";
CM_ SG_ 897 VCFRONT_suctionSuperheatEstTsSNA "Front body controller: suction superheat est ts SNA";
CM_ SG_ 897 VCFRONT_tempRefrigSuctionEst "Front body controller: temp refrig suction est";
CM_ SG_ 897 VCFRONT_hpBattOverTempHvacDisabl "Front body controller: hp batt over temp hvac disable";
CM_ SG_ 897 VCFRONT_hpDiagLouverCalib "Diagnostics requested a louver calibration.";
CM_ SG_ 897 VCFRONT_hpDiagHighSideNotNominal "Front body controller: hp diag high side not nominal";
CM_ SG_ 897 VCFRONT_hpForceModeRadClear "Front body controller: hp force mode rad clear";
CM_ SG_ 897 VCFRONT_estPressureDischargeSat "Front body controller: est pressure discharge sat";
CM_ SG_ 897 VCFRONT_tempRefrigLiquid "Refrigerant system liquid line temperature";
CM_ SG_ 897 VCFRONT_totalBattHeatingPower "Total battery heating power requested";
CM_ SG_ 897 VCFRONT_hpPotentialFrozenRadiato "Front body controller: hp potential frozen radiator";
CM_ SG_ 897 VCFRONT_passiveSeriesRegOn "Front body controller: passive series reg on";
CM_ SG_ 897 VCFRONT_passiveDemandRadBypass "Front body controller: passive demand rad bypass";
CM_ SG_ 897 VCFRONT_targetLccActiveCoolCap "Front body controller: target lcc active cool cap";
CM_ SG_ 897 VCFRONT_targetLccActiveCoolEff "Front body controller: target lcc active cool eff";
CM_ SG_ 897 VCFRONT_coolantValveDailyAngleTr "Running 10-day average of daily angular travel";
CM_ SG_ 897 VCFRONT_dischargePressureLimit "Front body controller: discharge pressure limit";
CM_ SG_ 897 VCFRONT_radMovementBlockActive "Front body controller: rad movement block active";
CM_ SG_ 897 VCFRONT_radBypassMoveReason "Front body controller: rad bypass move reason";
CM_ SG_ 897 VCFRONT_hpBattHeatingPower "Front body controller: hp batt heating power";
CM_ SG_ 897 VCFRONT_tempCoolantPTInletEstSta "Front body controller: temp coolant PT inlet est status";
CM_ SG_ 897 VCFRONT_hpColdStagnationLimit "Front body controller: hp cold stagnation limit";
CM_ SG_ 897 VCFRONT_hpHotStagnationLimit "Front body controller: hp hot stagnation limit";
CM_ SG_ 897 VCFRONT_hpCompFlowIndex "Front body controller: hp comp flow index";
CM_ SG_ 897 VCFRONT_hpCompFlowIndexFiltered "Front body controller: hp comp flow index filtered";
CM_ SG_ 897 VCFRONT_subcoolEstTlSNA "Front body controller: subcool est tl SNA";
CM_ SG_ 897 VCFRONT_subcoolEstPlSNA "Front body controller: subcool est pl SNA";
CM_ SG_ 897 VCFRONT_tempRefrigLiquidEst "Front body controller: temp refrig liquid est";
CM_ SG_ 897 VCFRONT_pressureRefrigLiquidEst "Front body controller: pressure refrig liquid est";
CM_ SG_ 897 VCFRONT_cmpIsentropicCheckPassed "Front body controller: cmp isentropic check passed";
CM_ SG_ 897 VCFRONT_louverPosReason "Front body controller: louver pos reason";
CM_ SG_ 897 VCFRONT_hpEnergyFlowIndex "Front body controller: hp energy flow index";
CM_ SG_ 897 VCFRONT_hpEnergyFlowIndexFiltere "Refrigerant system modeled energy flow index filtered";
CM_ SG_ 897 VCFRONT_ductLeftAtSS "Front body controller: duct left at SS";
CM_ SG_ 897 VCFRONT_ductRightAtSS "Front body controller: duct right at SS";
CM_ SG_ 897 VCFRONT_minCompressorRPMAllowed "Front body controller: min compressor RPM allowed";
CM_ SG_ 897 VCFRONT_ccRefrigerantMassFlow "Front body controller: cc refrigerant mass flow";
CM_ SG_ 897 VCFRONT_highSideDpResidual "Front body controller: high side dp residual";
CM_ SG_ 897 VCFRONT_abnormalHighSuctionSuper "Front body controller: abnormal high suction superheat";
CM_ SG_ 897 VCFRONT_coolantValveAngleTravel "Total angular travel since last (re)calibration";
CM_ SG_ 897 VCFRONT_chargeShuttleType "Front body controller: charge shuttle type";
CM_ SG_ 897 VCFRONT_hpRefrigTempSensorCheckC "Front body controller: hp refrig temp sensor check can fire";
CM_ SG_ 897 VCFRONT_hpRefrigPressureSensorCh "Front body controller: hp refrig pressure sensor check can fire";
CM_ SG_ 897 VCFRONT_tempSuperheatActFiltered "Front body controller: temp superheat act filtered";
CM_ SG_ 897 VCFRONT_tempRefrigDischarge "Refrigerant system discharge temperature";
CM_ SG_ 897 VCFRONT_pumpBatteryRPMTarget "Front body controller: pump battery RPM target";
CM_ SG_ 897 VCFRONT_pumpPowertrainRPMTarget "Front body controller: pump powertrain RPM target";
CM_ SG_ 897 VCFRONT_coolantFlowChillerTarget "Front body controller: coolant flow chiller target";
CM_ SG_ 897 VCFRONT_radiatorFanRPMTarget "Front body controller: radiator fan RPM target";
CM_ SG_ 897 VCFRONT_batteryDischArbState "Front body controller: battery disch arb state";
CM_ SG_ 897 VCFRONT_preventReEntryTillNexthp "Front body controller: prevent re entry till nexthp reset COP1";
CM_ SG_ 897 VCFRONT_chillerBattHeatingPowerA "Front body controller: chiller batt heating power available";
CM_ SG_ 897 VCFRONT_isExpectedQChillerVeryHi "Front body controller: is expected q chiller very high COP1";
CM_ SG_ 897 VCFRONT_superheatProtectionLimit "Front body controller: superheat protection limit";
CM_ SG_ 897 VCFRONT_chillerDemandWatts "Front body controller: chiller demand watts";
CM_ SG_ 897 VCFRONT_nominalTevapHWLimit "Front body controller: nominal tevap HW limit";
CM_ SG_ 897 VCFRONT_solverIterTotalLoad "Front body controller: solver iter total load";
CM_ SG_ 897 VCFRONT_battCoolEvapEnableDelay "Front body controller: batt cool evap enable delay";
CM_ SG_ 897 VCFRONT_solverIterFeedforward "Front body controller: solver iter feedforward";
CM_ SG_ 897 VCFRONT_ambientTempState "Front body controller: ambient temp state";
CM_ SG_ 897 VCFRONT_ambientTempUnlatchReason "Front body controller: ambient temp unlatch reason";
CM_ SG_ 897 VCFRONT_compressorSuctionVaporQu "Front body controller: compressor suction vapor quality";
CM_ SG_ 897 VCFRONT_cabinHeatingCOP1MinActiv "Estimation of minimal active refrigerant charge during cabin heating COP1 mode";
CM_ BO_ 513 "Front body controller message: logging and vitals10 hz";
CM_ SG_ 513 VCFRONT_loggingAndVitals10HzInde "Front body controller: logging and vitals10 hz index";
CM_ SG_ 513 VCFRONT_pumpBatteryRPMActual "Front body controller: pump battery RPM actual";
CM_ SG_ 513 VCFRONT_pumpPowertrainRPMActual "Front body controller: pump powertrain RPM actual";
CM_ SG_ 513 VCFRONT_radiatorFanRPMActual "Front body controller: radiator fan RPM actual";
CM_ SG_ 513 VCFRONT_exvFlowTarget "Front body controller: exv flow target";
CM_ SG_ 513 VCFRONT_activeLouverOpenPosTarg "The target position for the active louver";
CM_ SG_ 513 VCFRONT_pressureRefrigLiquid "Refrigerant system Liquid line pressure";
CM_ SG_ 513 VCFRONT_compSleepRequest "Front body controller: comp sleep request";
CM_ SG_ 513 VCFRONT_fanDemand "Front body controller: fan demand";
CM_ SG_ 513 VCFRONT_compressorState "State of the refrigerant compressor.";
CM_ SG_ 513 VCFRONT_compDemandEvap "Front body controller: comp demand evap";
CM_ SG_ 513 VCFRONT_exvState "Front body controller: exv state";
CM_ SG_ 513 VCFRONT_solenoidEvapState "Front body controller: solenoid evap state";
CM_ SG_ 513 VCFRONT_compDemandChiller "Front body controller: comp demand chiller";
CM_ SG_ 513 VCFRONT_coolantValveMode "Coolant mode of the powertrain cooling circuit";
CM_ SG_ 513 VCFRONT_compFaultSeverity "Front body controller: comp fault severity";
CM_ SG_ 513 VCFRONT_solenoidEngaged "Front body controller: solenoid engaged";
CM_ SG_ 513 VCFRONT_hpHighSideHX "Front body controller: hp high side HX";
CM_ SG_ 513 VCFRONT_hpLowSideHX "Front body controller: hp low side HX";
CM_ SG_ 513 VCFRONT_hpDominantLoad "Dominant load type for the refrigerant system";
CM_ SG_ 513 VCFRONT_hpBlendType "Front body controller: hp blend type";
CM_ SG_ 513 VCFRONT_hpQuietModeEnabled "Front body controller: hp quiet mode enabled";
CM_ SG_ 513 VCFRONT_hpCabinLoadType "Front body controller: hp cabin load type";
CM_ SG_ 513 VCFRONT_hpBatteryLoadType "Front body controller: hp battery load type";
CM_ SG_ 513 VCFRONT_hpReqCoolantMode "Front body controller: hp req coolant mode";
CM_ SG_ 513 VCFRONT_hpReqTransScavenge "Front body controller: hp req trans scavenge";
CM_ SG_ 513 VCFRONT_compLiqPumpOutState "Front body controller: comp liq pump out state";
CM_ SG_ 513 VCFRONT_frunkStateDBG "The verbose debug state of the frunk latch";
CM_ SG_ 513 VCFRONT_frunkSwitchGroupState "Front body controller: frunk switch group state";
CM_ SG_ 513 VCFRONT_chillerExvFlow "Percent of full range that the Chiller EXV has opened";
CM_ SG_ 513 VCFRONT_evapExvFlow "Percent of full range that the evap EXV has opened";
CM_ SG_ 513 VCFRONT_recircExvFlow "Percent of full range that the recirc EXV has opened";
CM_ SG_ 513 VCFRONT_lccExvFlow "Percent of full range that the Liquid cooled condenser EXV has opened";
CM_ SG_ 513 VCFRONT_cclExvFlow "Percent of full range that the left cabin condenser EXV has opened";
CM_ SG_ 513 VCFRONT_ccrExvFlow "Percent of full range that the right cabin condenser EXV has opened";
CM_ SG_ 513 VCFRONT_chillerExvState "State of the chiller electronic expansion valve";
CM_ SG_ 513 VCFRONT_evapExvState "State of the evaporator electronic expansion valve";
CM_ SG_ 513 VCFRONT_recircExvState "State of the recirc electronic expansion valve";
CM_ SG_ 513 VCFRONT_chillerExvFlowTarget "Target percentage of full range that the chiler electronic expansion valve is commanded to open";
CM_ SG_ 513 VCFRONT_evapExvFlowTarget "Target percentage of full range that the evap electronic expansion valve is commanded to open";
CM_ SG_ 513 VCFRONT_recircExvFlowTarget "Target percentage of full range that the recirc electronic expansion valve is commanded to open";
CM_ SG_ 513 VCFRONT_lccExvFlowTarget "Target percentage of full range that the liquid cooled condenser electronic expansion valve is commanded to open";
CM_ SG_ 513 VCFRONT_cclExvFlowTarget "Target percentage of full range that the cabin condenser left electronic expansion valve is commanded to open";
CM_ SG_ 513 VCFRONT_ccrExvFlowTarget "Target percentage of full range that the cabin condenser right electronic expansion valve is commanded to open";
CM_ SG_ 513 VCFRONT_lccExvState "State of the liquid cooled condenser electronic expansion valve";
CM_ SG_ 513 VCFRONT_cclExvState "State of the cabin condenser left electronic expansion valve";
CM_ SG_ 513 VCFRONT_ccrExvState "State of the cabin conddenser left electronic expansion valve";
CM_ BO_ 721 "Front body controller message: ok to use high power";
CM_ SG_ 721 VCFRONT_vcleftOkToUseHighPower "Front body controller: vcleft ok to use high power";
CM_ SG_ 721 VCFRONT_vcrightOkToUseHighPower "Front body controller: vcright ok to use high power";
CM_ SG_ 721 VCFRONT_das1OkToUseHighPower "Front body controller: das1 ok to use high power";
CM_ SG_ 721 VCFRONT_das2OkToUseHighPower "Front body controller: das2 ok to use high power";
CM_ SG_ 721 VCFRONT_MCULogicOkToUseHighPower "Front body controller: MCU logic ok to use high power";
CM_ SG_ 721 VCFRONT_MCUAudioOkToUseHighPower "Front body controller: MCU audio ok to use high power";
CM_ SG_ 721 VCFRONT_cpOkToUseHighPower "Front body controller: cp ok to use high power";
CM_ SG_ 721 VCFRONT_premAudioOkToUseHiPower "Front body controller: prem audio ok to use hi power";
CM_ SG_ 721 VCFRONT_tasOkToUseHighPower "Front body controller: tas ok to use high power";
CM_ BO_ 957 "Front body controller message: parked energy loss";
CM_ SG_ 957 VCFRONT_energyLossIndex "Front body controller: energy loss index";
CM_ SG_ 957 VCFRONT_userEnergyLossSinceDrive "Energy loss due to user interaction since last drive";
CM_ SG_ 957 VCFRONT_preconditioningEner_0001 "Energy loss due to preconditioning since last drive";
CM_ SG_ 957 VCFRONT_cabinOverheatEnergy_0001 "Energy loss due to cabin overheat protection since last drive";
CM_ SG_ 957 VCFRONT_mobileAppEnergyLoss_0001 "Energy loss due to mobile app interaction since last drive";
CM_ SG_ 957 VCFRONT_summonStandbyEnergy_0001 "Energy loss due to summon standby since last drive";
CM_ SG_ 957 VCFRONT_sentryModeEnergyLos_0001 "Energy loss due to sentry mode since last drive";
CM_ SG_ 957 VCFRONT_backgroundEnergyLos_0001 "Energy loss due to background vehicle op since last drive";
CM_ SG_ 957 VCFRONT_evapDryingEnergyLos_0001 "Energy loss due to evap drying since last drive";
CM_ SG_ 957 VCFRONT_userEnergyLossSinceCharg "Energy loss due to user interaction since last charge";
CM_ SG_ 957 VCFRONT_preconditioningEnergyLos "Energy loss due to preconditioning since last charge";
CM_ SG_ 957 VCFRONT_cabinOverheatEnergyLossS "Energy loss due to cabin overheat protection since last charge";
CM_ SG_ 957 VCFRONT_mobileAppEnergyLossSince "Energy loss due to mobile app interaction since last charge";
CM_ SG_ 957 VCFRONT_summonStandbyEnergyLossS "Energy loss due to summon standby since last charge";
CM_ SG_ 957 VCFRONT_sentryModeEnergyLossSinc "Energy loss due to sentry mode since last charge";
CM_ SG_ 957 VCFRONT_backgroundEnergyLossSinc "Energy loss due to background vehicle op since last charge";
CM_ SG_ 957 VCFRONT_evapDryingEnergyLossSinc "Energy loss due to evap drying since last charge";
CM_ BO_ 260 "Front body controller message: party debug";
CM_ SG_ 260 VCFRONT_vcleftHighPower "Front body controller: vcleft high power";
CM_ SG_ 260 VCFRONT_vcrightHighPower "Front body controller: vcright high power";
CM_ SG_ 260 VCFRONT_uiHighPower "Front body controller: ui high power";
CM_ SG_ 260 VCFRONT_5VAStable "Front body controller: 5 VA stable";
CM_ SG_ 260 VCFRONT_5VBStable "Front body controller: 5 VB stable";
CM_ SG_ 260 VCFRONT_12VAStable "Front body controller: 12 VA stable";
CM_ SG_ 260 VCFRONT_12VBStable "Front body controller: 12 VB stable";
CM_ SG_ 260 VCFRONT_railA "Front body controller: rail a";
CM_ SG_ 260 VCFRONT_railB "Front body controller: rail b";
CM_ SG_ 260 VCFRONT_chargePumpStable "Front body controller: charge pump stable";
CM_ SG_ 260 VCFRONT_vehicleSM "Vehicle state machine state";
CM_ SG_ 260 VCFRONT_revBattFault "Front body controller: rev batt fault";
CM_ SG_ 260 VCFRONT_battSM "Front body controller: batt SM";
CM_ SG_ 260 VCFRONT_U13Init "Front body controller: U13 init";
CM_ SG_ 260 VCFRONT_U16Init "Front body controller: U16 init";
CM_ SG_ 260 VCFRONT_anyVehLoadShedActiveDBG "Front body controller: any veh load shed active DBG";
CM_ SG_ 260 VCFRONT_battVoltage "Front body controller: batt voltage";
CM_ SG_ 260 VCFRONT_battCurrent "Front body controller: batt current";
CM_ BO_ 801 "Front body controller message: sensors";
CM_ SG_ 801 VCFRONT_tempCoolantBatInlet "Battery measured inlet coolant temperature";
CM_ SG_ 801 VCFRONT_tempCoolantPTInlet "Powertrain measured inlet coolant temperature";
CM_ SG_ 801 VCFRONT_coolantLevel "Front body controller: coolant level";
CM_ SG_ 801 VCFRONT_brakeFluidLevel "Reports detected brake fluid level at the fluid reservoir.";
CM_ SG_ 801 VCFRONT_tempAmbient "Front body controller: temp ambient";
CM_ SG_ 801 VCFRONT_washerFluidLevel "Indicates that the sensor has detected low windshield washer fluid.";
CM_ SG_ 801 VCFRONT_tempAmbientFiltered "Filtered ambient temperature based on vehicle speed";
CM_ SG_ 801 VCFRONT_battSensorIrrational "Front body controller: batt sensor irrational";
CM_ SG_ 801 VCFRONT_ptSensorIrrational "Front body controller: pt sensor irrational";
CM_ SG_ 801 VCFRONT_sensorsCounter "Front body controller: sensors counter";
CM_ SG_ 801 VCFRONT_sensorsChecksum "Front body controller: sensors checksum";
CM_ BO_ 737 "Front body controller message: status";
CM_ SG_ 737 VCFRONT_statusIndex "Front body controller: status index";
CM_ SG_ 737 VCFRONT_frunkLatchStatus "Front body controller: frunk latch status";
CM_ SG_ 737 VCFRONT_wiperSpeed "Front body controller: wiper speed";
CM_ SG_ 737 VCFRONT_wiperPosition "Wiper position";
CM_ SG_ 737 VCFRONT_wiperBlocked "Wiper ECU is reporting a block";
CM_ SG_ 737 VCFRONT_wiperState "Front body controller: wiper state";
CM_ SG_ 737 VCFRONT_crashDetectedType "Front body controller: crash detected type";
CM_ SG_ 737 VCFRONT_crashState "Front body controller: crash state";
CM_ SG_ 737 VCFRONT_crashUnlockOverrideSet "Indication that vehicle lock state has been overridden due to a collision.";
CM_ SG_ 737 VCFRONT_washPumpState "Front body controller: wash pump state";
CM_ SG_ 737 VCFRONT_turnIndicatorControlType "Turn indicator control hardware variant";
CM_ SG_ 737 VCFRONT_wiperHealth "Health metric to track the power and communication state of the wiper module";
CM_ SG_ 737 VCFRONT_frunkLatchCurrent "Reports the current used by the frunk latch.";
CM_ SG_ 737 VCFRONT_frunkInteriorRelSwitch "State of the frunk interior release switch";
CM_ SG_ 737 VCFRONT_anyClosureOpen "Front body controller: any closure open";
CM_ SG_ 737 VCFRONT_anyDoorOpen "Front body controller: any door open";
CM_ SG_ 737 VCFRONT_hornOn "Indication that the horn is on";
CM_ SG_ 737 VCFRONT_radarHeaterState "Front body controller: radar heater state";
CM_ SG_ 737 VCFRONT_trunkExteriorWakeSwitch "State of the trunk exterior switch, used for wake only";
CM_ SG_ 737 VCFRONT_passengerBuckleStatus "State of the passenger's seat belt buckle";
CM_ SG_ 737 VCFRONT_frunkLatchType "Front body controller: frunk latch type";
CM_ SG_ 737 VCFRONT_headlampLeftFanStatus "Front body controller: headlamp left fan status";
CM_ SG_ 737 VCFRONT_headlampRightFanStatus "Front body controller: headlamp right fan status";
CM_ SG_ 737 VCFRONT_frunkAccessPost "Front body controller: frunk access post";
CM_ SG_ 737 VCFRONT_isActiveHeatingBattery "Front body controller: is active heating battery";
CM_ SG_ 737 VCFRONT_iBoosterWakeLine "Front body controller: i booster wake line";
CM_ SG_ 737 VCFRONT_epasWakeLine "Front body controller: epas wake line";
CM_ SG_ 737 VCFRONT_iBoosterStateDBG "Front body controller: i booster state DBG";
CM_ SG_ 737 VCFRONT_vehicleStatusDBG "Vehicle state machine state debug";
CM_ SG_ 737 VCFRONT_timeSpentSleeping "Measures time elapsed while the vehicle has been sleeping.";
CM_ SG_ 737 VCFRONT_sleepCurrent "Calculated electrical current into the 12V battery during VCFRONT sleep";
CM_ SG_ 737 VCFRONT_hibernationState "Front body controller: hibernation state";
CM_ SG_ 737 VCFRONT_wiperECUType "Wiper ECU type detected";
CM_ SG_ 737 VCFRONT_wiperHeaterState "Indicates the state of the wiper heater";
CM_ SG_ 737 VCFRONT_occupantCount "Front body controller: occupant count";
CM_ SG_ 737 VCFRONT_closureEasterEggState "Front body controller: closure easter egg state";
CM_ SG_ 737 VCFRONT_espWakeLine "Front body controller: esp wake line";
CM_ SG_ 737 VCFRONT_allowEvapInLowAmbient "Front body controller: allow evap in low ambient";
CM_ SG_ 737 VCFRONT_potentialRadiatorSteam "Front body controller: potential radiator steam";
CM_ SG_ 737 VCFRONT_potentialRadiatorSteamUI "Front body controller: potential radiator steam UI";
CM_ SG_ 737 VCFRONT_hvacReqOffForFasterCharg "Reports if turning Heating, Ventilation, and Air Conditioning (HVAC) off may improve supercharging power.";
CM_ SG_ 737 VCFRONT_homelinkV2Response0 "Front body controller: homelink V2 response0";
CM_ SG_ 737 VCFRONT_homelinkV2Response1 "Front body controller: homelink V2 response1";
CM_ SG_ 737 VCFRONT_homelinkV2Response2 "Front body controller: homelink V2 response2";
CM_ SG_ 737 VCFRONT_homelinkV2Response3 "Front body controller: homelink V2 response3";
CM_ SG_ 737 VCFRONT_homelinkV2Response4 "Front body controller: homelink V2 response4";
CM_ SG_ 737 VCFRONT_homelinkCommStatus "Homelink communication status";
CM_ SG_ 737 VCFRONT_maxEvapHeatRejection "Front body controller: max evap heat rejection";
CM_ SG_ 737 VCFRONT_minEvapHeatRejection "Front body controller: min evap heat rejection";
CM_ SG_ 737 VCFRONT_freezeEvapITerm "Front body controller: freeze evap i term";
CM_ SG_ 737 VCFRONT_isEvapOperationAllowed "Front body controller: is evap operation allowed";
CM_ SG_ 737 VCFRONT_chillerDemandActive "Front body controller: chiller demand active";
CM_ SG_ 737 VCFRONT_compPerfRecoveryLimited "Front body controller: comp perf recovery limited";
CM_ SG_ 737 VCFRONT_hvacModeNotAttainable "Front body controller: hvac mode not attainable";
CM_ SG_ 737 VCFRONT_hasLowRefrigerant "Front body controller: has low refrigerant";
CM_ SG_ 737 VCFRONT_isColdStartRunning "Front body controller: is cold start running";
CM_ SG_ 737 VCFRONT_isHeatPumpOilPurgeActive "Front body controller: is heat pump oil purge active";
CM_ SG_ 737 VCFRONT_pressureRefrigSuction "Refrigerant system suction pressure";
CM_ SG_ 737 VCFRONT_pressureRefrigDischarge "Refrigerant system discharge pressure";
CM_ SG_ 737 VCFRONT_hvacPerfTestCommand "Front body controller: hvac perf test command";
CM_ SG_ 737 VCFRONT_coolantFillRoutineStatus "Front body controller: coolant fill routine status";
CM_ SG_ 737 VCFRONT_refrigFillRoutineStatus "Front body controller: refrig fill routine status";
CM_ SG_ 737 VCFRONT_isCOP1Running "Front body controller: is COP1 running";
CM_ SG_ 737 VCFRONT_closeValvesRoutineStatus "Front body controller: close valves routine status";
CM_ SG_ 737 VCFRONT_thermalPerfTestRunning "Front body controller: thermal perf test running";
CM_ SG_ 737 VCFRONT_5VARailStable "Front body controller: 5 VA rail stable";
CM_ SG_ 737 VCFRONT_5VBRailStable "Front body controller: 5 VB rail stable";
CM_ SG_ 737 VCFRONT_12VARailStable "Front body controller: 12 VA rail stable";
CM_ SG_ 737 VCFRONT_12VBRailStable "Front body controller: 12 VB rail stable";
CM_ SG_ 737 VCFRONT_railAState "Front body controller: rail a state";
CM_ SG_ 737 VCFRONT_railBState "Front body controller: rail b state";
CM_ SG_ 737 VCFRONT_ChargePumpVoltageStable "Front body controller: charge pump voltage stable";
CM_ SG_ 737 VCFRONT_PEResetLineState "Front body controller: PE reset line state";
CM_ SG_ 737 VCFRONT_HSDInitCompleteU13 "Front body controller: HSD init complete U13";
CM_ SG_ 737 VCFRONT_HSDInitCompleteU16 "Front body controller: HSD init complete U16";
CM_ SG_ 737 VCFRONT_vbatMonitorVoltage "Front body controller: vbat monitor voltage";
CM_ SG_ 737 VCFRONT_AS8510Voltage "Front body controller: AS8510 voltage";
CM_ SG_ 737 VCFRONT_vbatProt "Front body controller: vbat prot";
CM_ SG_ 737 VCFRONT_logVerbosity "Front body controller: log verbosity";
CM_ SG_ 737 VCFRONT_cabinCoolingCapacityLimi "Front body controller: cabin cooling capacity limited";
CM_ SG_ 737 VCFRONT_cabinHeatingCapacityLimi "Front body controller: cabin heating capacity limited";
CM_ SG_ 737 VCFRONT_compPowerSupportingHvac "Front body controller: comp power supporting hvac";
CM_ SG_ 737 VCFRONT_compPowerSupportingPT "Front body controller: comp power supporting PT";
CM_ SG_ 737 VCFRONT_maxHeatingPowerLeftCC "Front body controller: max heating power left CC";
CM_ SG_ 737 VCFRONT_maxHeatingPowerRightCC "Front body controller: max heating power right CC";
CM_ SG_ 737 VCFRONT_activeLouverOpenPos "The actual position for the active louver";
CM_ SG_ 737 VCFRONT_activeLouverState "State of the active louver circuit";
CM_ SG_ 737 VCFRONT_windshieldCameraHeaterPo "Front body controller: windshield camera heater power";
CM_ BO_ 1349 "Front body controller message: system status";
CM_ SG_ 1349 VCFRONT_systemStatusMuxIndex "Front body controller: system status mux index";
CM_ SG_ 1349 VCFRONT_systemStatusCounter "Front body controller: system status counter";
CM_ SG_ 1349 VCFRONT_systemStatusChecksum "Front body controller: system status checksum";
CM_ SG_ 1349 VCFRONT_loadShedReason "Front body controller: load shed reason";
CM_ SG_ 1349 VCFRONT_VCRightEFuseLoadShedStag "Front body controller: VC right e fuse load shed stage";
CM_ SG_ 1349 VCFRONT_VCLeftEFuseLoadShedStage "Front body controller: VC left e fuse load shed stage";
CM_ SG_ 1349 VCFRONT_DCDCSaturationLoadShedSt "Front body controller: DCDC saturation load shed stage";
CM_ SG_ 1349 VCFRONT_vehicleLoadShedStage "Front body controller: vehicle load shed stage";
CM_ SG_ 1349 VCFRONT_HVFaultVehicleLoadShedRe "Front body controller: HV fault vehicle load shed request";
CM_ SG_ 1349 VCFRONT_postCrashVehicleLoadShed "Front body controller: post crash vehicle load shed active";
CM_ SG_ 1349 VCFRONT_HVFaultVehicleLoadShedAc "Front body controller: HV fault vehicle load shed active";
CM_ SG_ 1349 VCFRONT_factoryVehicleLoadShedAc "Indicates that vehicle is factory load shedding";
CM_ SG_ 1349 VCFRONT_anyVehicleLoadShedActive "Front body controller: any vehicle load shed active";
CM_ SG_ 1349 VCFRONT_DIVehLoadShedActive "Front body controller: DI veh load shed active";
CM_ SG_ 1349 VCFRONT_HVFaultLoadShedStateDBG "Front body controller: HV fault load shed state DBG";
CM_ SG_ 1349 VCFRONT_LVUnhealthyVehicleLoadSh "Front body controller: LV unhealthy vehicle load shed active";
CM_ SG_ 1349 VCFRONT_loadShedStsCondenserFan "Front body controller: load shed sts condenser fan";
CM_ SG_ 1349 VCFRONT_loadShedStsPTPump "Front body controller: load shed sts PT pump";
CM_ SG_ 1349 VCFRONT_loadShedMCUAudio "Front body controller: load shed MCU audio";
CM_ SG_ 1349 VCFRONT_loadShedHVDownTriggerDBG "Front body controller: load shed HV down trigger DBG";
CM_ SG_ 1349 VCFRONT_loadShedPCSSatTriggerDBG "Front body controller: load shed PCS sat trigger DBG";
CM_ SG_ 1349 VCFRONT_loadShedStsBatteryPump "Front body controller: load shed sts battery pump";
CM_ SG_ 1349 VCFRONT_loadShedStsAPGlassHeater "Front body controller: load shed sts AP glass heater";
CM_ SG_ 1349 VCFRONT_loadShedStsMCUGraphics "Front body controller: load shed sts MCU graphics";
CM_ SG_ 1349 VCFRONT_IBSCurrentRMS_loadShed "Front body controller: IBS current RMS load shed";
CM_ SG_ 1349 VCFRONT_loadShedAhLeakyBktCntDBG "Front body controller: load shed ah leaky bkt cnt DBG";
CM_ SG_ 1349 VCFRONT_loadShedPcs "Front body controller: load shed pcs";
CM_ SG_ 1349 VCFRONT_loadShedGTWDownstrmRails "Front body controller: load shed GTW downstrm rails";
CM_ SG_ 1349 VCFRONT_loadShedPCSMIATriggerDBG "Front body controller: load shed PCSMIA trigger DBG";
CM_ SG_ 1349 VCFRONT_loadShedTAS "Front body controller: load shed TAS";
CM_ SG_ 1349 VCFRONT_loadShedBackStopBktCntDB "Front body controller: load shed back stop bkt cnt DBG";
CM_ SG_ 1349 VCFRONT_loadShedPCSLeakyBktCtDBG "Front body controller: load shed PCS leaky bkt ct DBG";
CM_ SG_ 1349 VCFRONT_loadShedUI "Front body controller: load shed UI";
CM_ SG_ 1349 VCFRONT_loadShedAutoPilot "Front body controller: load shed auto pilot";
CM_ BO_ 929 "Front body controller message: vehicle status";
CM_ SG_ 929 VCFRONT_vehicleStatusMuxIndex "Front body controller: vehicle status mux index";
CM_ SG_ 929 VCFRONT_vehicleStatusCounter "Front body controller: vehicle status counter";
CM_ SG_ 929 VCFRONT_vehicleStatusChecksum "Front body controller: vehicle status checksum";
CM_ SG_ 929 VCFRONT_preconditionRequest "Front body controller: precondition request";
CM_ SG_ 929 VCFRONT_APGlassHeaterState "Front body controller: AP glass heater state";
CM_ SG_ 929 VCFRONT_thermalSystemType "Front body controller: thermal system type";
CM_ SG_ 929 VCFRONT_standbySupplySupported "Front body controller: standby supply supported";
CM_ SG_ 929 VCFRONT_driverPresent "Front body controller: driver present";
CM_ SG_ 929 VCFRONT_passengerPresent "Front body controller: passenger present";
CM_ SG_ 929 VCFRONT_accPlusAvailable "Front body controller: acc plus available";
CM_ SG_ 929 VCFRONT_diPowerOnState "Front body controller: di power on state";
CM_ SG_ 929 VCFRONT_12vStatusForDrive "Front body controller: 12v status for drive";
CM_ SG_ 929 VCFRONT_dcr12VMilliOhms "Front body controller: dcr12 v milli ohms";
CM_ SG_ 929 VC_userPresenceState "User presence state";
CM_ SG_ 929 VCFRONT_factoryLimitsOverrideOk "Front body controller: factory limits override ok";
CM_ SG_ 929 VCFRONT_ota12VSupportRequest "Front body controller: ota12 v support request";
CM_ SG_ 929 VCFRONT_driverBuckleStatus "Front body controller: driver buckle status";
CM_ SG_ 929 VCFRONT_driverDoorStatus "Front body controller: driver door status";
CM_ SG_ 929 VCFRONT_driverUnbuckled "Front body controller: driver unbuckled";
CM_ SG_ 929 VCFRONT_passengerUnbuckled "Front body controller: passenger unbuckled";
CM_ SG_ 929 VCFRONT_2RowLeftUnbuckled "Front body controller: 2 row left unbuckled";
CM_ SG_ 929 VCFRONT_2RowCenterUnbuckled "Front body controller: 2 row center unbuckled";
CM_ SG_ 929 VCFRONT_2RowRightUnbuckled "Front body controller: 2 row right unbuckled";
CM_ SG_ 929 VCFRONT_pcsEFuseVoltage "Front body controller: pcs e fuse voltage";
CM_ SG_ 929 VCFRONT_bmsHvChargeEnable "Front body controller: bms hv charge enable";
CM_ SG_ 929 VCFRONT_3RowLeftUnbuckled "Indication that the third row left passenger has unbuckled their seat belt";
CM_ SG_ 929 VCFRONT_3RowRightUnbuckled "Indication that the third row right passenger has unbuckled their seat belt";
CM_ SG_ 929 VCFRONT_maxBattHeatRejection "Radiator max heat rejection estimated at zero vehicle speed.";
CM_ SG_ 929 VCFRONT_hvacReqBattCoolOutTemp "Battery outlet coolant temp target to allow HVAC min comfort";
CM_ SG_ 929 VCFRONT_PCSCurrent "Front body controller: PCS current";
CM_ SG_ 929 VCFRONT_refSystemNominal "Front body controller: ref system nominal";
CM_ SG_ 929 VCFRONT_driverEnteredCabinEstima "Front body controller: driver entered cabin estimate DBG";
CM_ SG_ 929 VCFRONT_anySWEFuseActive "Front body controller: any SWE fuse active";
CM_ SG_ 929 VCFRONT_hpBattHeatingPowerTrgt "Reports the heat pump battery heating power target.";
CM_ BO_ 507 "Left body controller message: TLC status";
CM_ SG_ 507 VCLEFT_TLCStatusIndex "Left body controller: TLC status index";
CM_ SG_ 507 VCLEFT_TLCTemperature "Monitors board temperatures for electrical validation.";
CM_ SG_ 507 VCLEFT_TLCLeftTurnVoltage "Reports voltage for analysis of in field issues.";
CM_ SG_ 507 VCLEFT_TLCRightTurnVoltage "Reports voltage for analysis of in field issues.";
CM_ SG_ 507 VCLEFT_TLCState_LeftTurn "Reports trailer light status.";
CM_ SG_ 507 VCLEFT_TLCState_RightTurn "Reports trailer light status.";
CM_ SG_ 507 VCLEFT_TLCState_Tail "Reports trailer light status.";
CM_ SG_ 507 VCLEFT_TLCState_Stop "Reports trailer light status.";
CM_ SG_ 507 VCLEFT_TLCState_Fog "Reports trailer light status.";
CM_ SG_ 507 VCLEFT_TLCState_Reverse "Reports trailer light status.";
CM_ BO_ 2013 "Left body controller message: alert log";
CM_ SG_ 2013 VCLEFT_alertID "Left body controller: alert ID";
CM_ SG_ 2013 VCLEFT_alertState "Left body controller: alert state";
CM_ SG_ 2013 VCLEFT_a001_InternalWatchdog "Left body controller: a001 internal watchdog";
CM_ SG_ 2013 VCLEFT_a002_CPUUndervoltage "Left body controller: a002 CPU undervoltage";
CM_ SG_ 2013 VCLEFT_a002_PowerOnReset "Left body controller: a002 power on reset";
CM_ SG_ 2013 VCLEFT_a010_UnderVoltageDetected "Left body controller: a010 under voltage detected";
CM_ SG_ 2013 VCLEFT_a010_UnderVoltageTimeout "Left body controller: a010 under voltage timeout";
CM_ SG_ 2013 VCLEFT_a015_NVMMMemOverflow "Left body controller: a015 NVMM mem overflow";
CM_ SG_ 2013 VCLEFT_a015_NVMMFilesystemError "Left body controller: a015 NVMM filesystem error";
CM_ SG_ 2013 VCLEFT_a015_NVMMRecordIDError "Left body controller: a015 NVMM record ID error";
CM_ SG_ 2013 VCLEFT_a057_VEH_cpControl "Left body controller: a057 VEH cp control";
CM_ SG_ 2013 VCLEFT_a059_voltageDrop "Left body controller: a059 voltage drop";
CM_ SG_ 2013 VCLEFT_a059_resistanceEstimate "Left body controller: a059 resistance estimate";
CM_ SG_ 2013 VCLEFT_a059_current "Left body controller: a059 current";
CM_ SG_ 2013 VCLEFT_a063_switchChannel "Left body controller: a063 switch channel";
CM_ SG_ 2013 VCLEFT_a063_switchType "Left body controller: a063 switch type";
CM_ SG_ 2013 VCLEFT_a063_ADCVoltage "Left body controller: a063 ADC voltage";
CM_ SG_ 2013 VCLEFT_a063_disconnected "Left body controller: a063 disconnected";
CM_ SG_ 2013 VCLEFT_a063_indeterminate "Left body controller: a063 indeterminate";
CM_ SG_ 2013 VCLEFT_a063_stuckActive "Left body controller: a063 stuck active";
CM_ SG_ 2013 VCLEFT_a063_faulted "Left body controller: a063 faulted";
CM_ SG_ 2013 VCLEFT_a082_RIPC_epbPrivateState "Left body controller: a082 RIPC epb private state";
CM_ SG_ 2013 VCLEFT_a082_RIPC_remoteHSD "Left body controller: a082 RIPC remote HSD";
CM_ SG_ 2013 VCLEFT_a082_RIPC_railStatus "Left body controller: a082 RIPC rail status";
CM_ SG_ 2013 VCLEFT_a082_RIPC_remoteMux "Left body controller: a082 RIPC remote mux";
CM_ SG_ 2013 VCLEFT_a083_LIPC_epbPrivateState "Left body controller: a083 LIPC epb private state";
CM_ SG_ 2013 VCLEFT_a083_LIPC_remoteHSD "Left body controller: a083 LIPC remote HSD";
CM_ SG_ 2013 VCLEFT_a083_LIPC_railStatus "Left body controller: a083 LIPC rail status";
CM_ SG_ 2013 VCLEFT_a083_LIPC_HSDFaults "Left body controller: a083 LIPC HSD faults";
CM_ SG_ 2013 VCLEFT_a084_CH_StatusC "Left body controller: a084 CH status c";
CM_ SG_ 2013 VCLEFT_a085_PARTY_buttonStatus "Left body controller: a085 PARTY button status";
CM_ SG_ 2013 VCLEFT_a086_VEH_LVBMS_statusHigh "Left body controller: a086 VEH LVBMS status high";
CM_ SG_ 2013 VCLEFT_a086_VEH_LVBMS_statusLow "Left body controller: a086 VEH LVBMS status low";
CM_ SG_ 2013 VCLEFT_a086_VEH_status "Left body controller: a086 VEH status";
CM_ SG_ 2013 VCLEFT_a086_VEH_12VBatteryStatus "Left body controller: a086 VEH 12 v battery status";
CM_ SG_ 2013 VCLEFT_a086_VEH_LVPowerState "Left body controller: a086 VEH LV power state";
CM_ SG_ 2013 VCLEFT_a086_VEH_lightStatus "Left body controller: a086 VEH light status";
CM_ SG_ 2013 VCLEFT_a086_VEH_systemStatus "Left body controller: a086 VEH system status";
CM_ SG_ 2013 VCLEFT_a086_VEH_thermalStatus "Left body controller: a086 VEH thermal status";
CM_ SG_ 2013 VCLEFT_a086_VEH_vehNm "Left body controller: a086 VEH veh nm";
CM_ SG_ 2013 VCLEFT_a086_BDY_12VBatteryStatus "Left body controller: a086 BDY 12 v battery status";
CM_ SG_ 2013 VCLEFT_a087_VEH_temperature "Left body controller: a087 VEH temperature";
CM_ SG_ 2013 VCLEFT_a087_VEH_thermalControl "Left body controller: a087 VEH thermal control";
CM_ SG_ 2013 VCLEFT_a087_VEH_torque "Left body controller: a087 VEH torque";
CM_ SG_ 2013 VCLEFT_a087_VEH_status "Left body controller: a087 VEH status";
CM_ SG_ 2013 VCLEFT_a087_PARTY_torque "Left body controller: a087 PARTY torque";
CM_ SG_ 2013 VCLEFT_a087_PARTY_status "Left body controller: a087 PARTY status";
CM_ SG_ 2013 VCLEFT_a087_PARTY_temperature "Left body controller: a087 PARTY temperature";
CM_ SG_ 2013 VCLEFT_a087_PARTY_thermalControl "Left body controller: a087 PARTY thermal control";
CM_ SG_ 2013 VCLEFT_a088_VEH_temperature "Left body controller: a088 VEH temperature";
CM_ SG_ 2013 VCLEFT_a088_VEH_thermalControl "Left body controller: a088 VEH thermal control";
CM_ SG_ 2013 VCLEFT_a088_VEH_torque "Left body controller: a088 VEH torque";
CM_ SG_ 2013 VCLEFT_a088_VEH_status "Left body controller: a088 VEH status";
CM_ SG_ 2013 VCLEFT_a088_PARTY_torque "Left body controller: a088 PARTY torque";
CM_ SG_ 2013 VCLEFT_a088_PARTY_status "Left body controller: a088 PARTY status";
CM_ SG_ 2013 VCLEFT_a088_PARTY_temperature "Left body controller: a088 PARTY temperature";
CM_ SG_ 2013 VCLEFT_a088_PARTY_thermalControl "Left body controller: a088 PARTY thermal control";
CM_ SG_ 2013 VCLEFT_a089_PARTY_party1 "Left body controller: a089 PARTY party1";
CM_ SG_ 2013 VCLEFT_a089_PARTY_status "Left body controller: a089 PARTY status";
CM_ SG_ 2013 VCLEFT_a089_VEH_status "Left body controller: a089 VEH status";
CM_ SG_ 2013 VCLEFT_a089_BDY_party1 "Left body controller: a089 BDY party1";
CM_ SG_ 2013 VCLEFT_a089_BDY_status "Left body controller: a089 BDY status";
BA_DEF_ BO_ "GenMsgCycleTime" INT 0 3600000;
BA_DEF_ BO_ "GenMsgSendType" ENUM "Cyclic","NotUsed","NotUsed","NotUsed","NotUsed","NotUsed","NotUsed","IfActive","NoMsgSendType","NotUsed";
BA_DEF_ BO_ "VFrameFormat" ENUM "StandardCAN","ExtendedCAN","reserved","J1939PG","reserved","reserved","reserved","reserved","reserved","reserved","reserved","reserved","reserved","reserved","StandardCAN_FD","ExtendedCAN_FD";
BA_DEF_ BO_ "CANFD_BRS" ENUM "0","1";
BA_DEF_ SG_ "SystemSignalLongSymbol" STRING;
BA_DEF_ SG_ "Confidence" ENUM "layout-only","plausible","validated";
BA_DEF_DEF_ "GenMsgCycleTime" 0;
BA_DEF_DEF_ "GenMsgSendType" "NoMsgSendType";
BA_DEF_DEF_ "VFrameFormat" "StandardCAN";
BA_DEF_DEF_ "CANFD_BRS" "1";
BA_DEF_DEF_ "SystemSignalLongSymbol" "";
BA_DEF_DEF_ "Confidence" "layout-only";
BA_ "Confidence" SG_ 753 VCFRONT_leftControllerState 1;
BA_ "Confidence" SG_ 753 VCFRONT_vcleftSelfTestResult 1;
BA_ "Confidence" SG_ 753 VCFRONT_leftControllerTemp 1;
BA_ "Confidence" SG_ 753 VCFRONT_leftControllerEFuseVNFSt 1;
BA_ "SystemSignalLongSymbol" SG_ 753 VCFRONT_leftControllerEFuseVNFSt "VCFRONT_leftControllerEFuseVNFState";
BA_ "Confidence" SG_ 753 VCFRONT_leftControllerEFuseOutpu 1;
BA_ "SystemSignalLongSymbol" SG_ 753 VCFRONT_leftControllerEFuseOutpu "VCFRONT_leftControllerEFuseOutput";
BA_ "Confidence" SG_ 753 VCFRONT_leftControllerEFuse_0002 1;
BA_ "SystemSignalLongSymbol" SG_ 753 VCFRONT_leftControllerEFuse_0002 "VCFRONT_leftControllerEFuseOutputDesired";
BA_ "Confidence" SG_ 753 VCFRONT_leftControllerVoltage 1;
BA_ "Confidence" SG_ 753 VCFRONT_leftControllerEFuseBypas 1;
BA_ "SystemSignalLongSymbol" SG_ 753 VCFRONT_leftControllerEFuseBypas "VCFRONT_leftControllerEFuseBypass";
BA_ "Confidence" SG_ 753 VCFRONT_leftControllerEFuse_0001 1;
BA_ "SystemSignalLongSymbol" SG_ 753 VCFRONT_leftControllerEFuse_0001 "VCFRONT_leftControllerEFuseBypassDesired";
BA_ "Confidence" SG_ 753 VCFRONT_leftControllerCurrent 1;
BA_ "Confidence" SG_ 753 VCFRONT_leftControllerEFuseVNFSe 1;
BA_ "SystemSignalLongSymbol" SG_ 753 VCFRONT_leftControllerEFuseVNFSe "VCFRONT_leftControllerEFuseVNFSelfTestStatus";
BA_ "Confidence" SG_ 753 VCFRONT_PCSState 1;
BA_ "Confidence" SG_ 753 VCFRONT_pcsSelfTestResult 1;
BA_ "Confidence" SG_ 753 VCFRONT_PCSTemp 1;
BA_ "Confidence" SG_ 753 VCFRONT_PCSEFuseVNFState 1;
BA_ "Confidence" SG_ 753 VCFRONT_PCSEFuseOutput 1;
BA_ "Confidence" SG_ 753 VCFRONT_PCSEFuseOutputDesired 1;
BA_ "Confidence" SG_ 753 VCFRONT_PCSVoltage 1;
BA_ "Confidence" SG_ 753 VCFRONT_PCSEFuseBypass 1;
BA_ "Confidence" SG_ 753 VCFRONT_PCSEFuseBypassDesired 1;
BA_ "Confidence" SG_ 753 VCFRONT_PCSEFuseVNFSelfTestStatu 1;
BA_ "SystemSignalLongSymbol" SG_ 753 VCFRONT_PCSEFuseVNFSelfTestStatu "VCFRONT_PCSEFuseVNFSelfTestStatus";
BA_ "Confidence" SG_ 753 VCFRONT_iBoosterState 1;
BA_ "Confidence" SG_ 753 VCFRONT_iBoosterSelfTestResult 1;
BA_ "Confidence" SG_ 753 VCFRONT_iBoosterTemp 1;
BA_ "SystemSignalLongSymbol" SG_ 753 VCFRONT_IBoosterEFuseOutputDesir "VCFRONT_IBoosterEFuseOutputDesired";
BA_ "Confidence" SG_ 753 VCFRONT_iBoosterVoltage 1;
BA_ "SystemSignalLongSymbol" SG_ 753 VCFRONT_IBoosterEFuseBypassDesir "VCFRONT_IBoosterEFuseBypassDesired";
BA_ "Confidence" SG_ 753 VCFRONT_iBoosterCurrent 1;
BA_ "SystemSignalLongSymbol" SG_ 753 VCFRONT_IBoosterEFuseVNFSelfTest "VCFRONT_IBoosterEFuseVNFSelfTestStatus";
BA_ "Confidence" SG_ 753 VCFRONT_EPAS3PState 1;
BA_ "Confidence" SG_ 753 VCFRONT_EPAS3PSelfTestResult 1;
BA_ "Confidence" SG_ 753 VCFRONT_EPAS3PTemp 1;
BA_ "Confidence" SG_ 753 VCFRONT_EPAS3PEFuseVNFState 1;
BA_ "Confidence" SG_ 753 VCFRONT_EPAS3PEFuseOutput 1;
BA_ "Confidence" SG_ 753 VCFRONT_EPAS3PEFuseOutputDesired 1;
BA_ "Confidence" SG_ 753 VCFRONT_EPAS3PVoltage 1;
BA_ "Confidence" SG_ 753 VCFRONT_EPAS3PEFuseHardshortThre 1;
BA_ "SystemSignalLongSymbol" SG_ 753 VCFRONT_EPAS3PEFuseHardshortThre "VCFRONT_EPAS3PEFuseHardshortThresholdDbg";
BA_ "Confidence" SG_ 753 VCFRONT_EPAS3PEFuseBypass 1;
BA_ "Confidence" SG_ 753 VCFRONT_EPAS3PEFuseBypassDesired 1;
BA_ "Confidence" SG_ 753 VCFRONT_EPAS3PCurrent 1;
BA_ "Confidence" SG_ 753 VCFRONT_EPAS3PEFuseVNFSelfTestSt 1;
BA_ "SystemSignalLongSymbol" SG_ 753 VCFRONT_EPAS3PEFuseVNFSelfTestSt "VCFRONT_EPAS3PEFuseVNFSelfTestStatus";
BA_ "Confidence" SG_ 753 VCFRONT_EPAS3SState 1;
BA_ "Confidence" SG_ 753 VCFRONT_EPAS3SSelfTestResult 1;
BA_ "Confidence" SG_ 753 VCFRONT_EPAS3STemp 1;
BA_ "Confidence" SG_ 753 VCFRONT_EPAS3SEFuseVNFState 1;
BA_ "Confidence" SG_ 753 VCFRONT_EPAS3SEFuseOutput 1;
BA_ "Confidence" SG_ 753 VCFRONT_EPAS3SEFuseOutputDesired 1;
BA_ "Confidence" SG_ 753 VCFRONT_EPAS3SVoltage 1;
BA_ "Confidence" SG_ 753 VCFRONT_EPAS3SEFuseBypass 1;
BA_ "Confidence" SG_ 753 VCFRONT_EPAS3SEFuseBypassDesired 1;
BA_ "Confidence" SG_ 753 VCFRONT_EPAS3SCurrent 1;
BA_ "Confidence" SG_ 753 VCFRONT_EPAS3SEFuseVNFSelfTestSt 1;
BA_ "SystemSignalLongSymbol" SG_ 753 VCFRONT_EPAS3SEFuseVNFSelfTestSt "VCFRONT_EPAS3SEFuseVNFSelfTestStatus";
BA_ "Confidence" SG_ 753 VCFRONT_ESPMotorState 1;
BA_ "Confidence" SG_ 753 VCFRONT_ESPMotorSelfTestResult 1;
BA_ "Confidence" SG_ 753 VCFRONT_ESPMotorTemp 1;
BA_ "Confidence" SG_ 753 VCFRONT_ESPMotorEFuseVNFState 1;
BA_ "Confidence" SG_ 753 VCFRONT_ESPMotorEFuseOutput 1;
BA_ "Confidence" SG_ 753 VCFRONT_ESPMotorEFuseOutputDesir 1;
BA_ "SystemSignalLongSymbol" SG_ 753 VCFRONT_ESPMotorEFuseOutputDesir "VCFRONT_ESPMotorEFuseOutputDesired";
BA_ "Confidence" SG_ 753 VCFRONT_ESPMotorVoltage 1;
BA_ "Confidence" SG_ 753 VCFRONT_ESPMotorEFuseBypass 1;
BA_ "Confidence" SG_ 753 VCFRONT_ESPMotorEFuseBypassDesir 1;
BA_ "SystemSignalLongSymbol" SG_ 753 VCFRONT_ESPMotorEFuseBypassDesir "VCFRONT_ESPMotorEFuseBypassDesired";
BA_ "Confidence" SG_ 753 VCFRONT_ESPMotorCurrent 1;
BA_ "Confidence" SG_ 753 VCFRONT_ESPMotorEFuseVNFSelfTest 1;
BA_ "SystemSignalLongSymbol" SG_ 753 VCFRONT_ESPMotorEFuseVNFSelfTest "VCFRONT_ESPMotorEFuseVNFSelfTestStatus";
BA_ "Confidence" SG_ 753 VCFRONT_ESPValveState 1;
BA_ "Confidence" SG_ 753 VCFRONT_ESPValveTemp 1;
BA_ "Confidence" SG_ 753 VCFRONT_ESPValveVoltage 1;
BA_ "Confidence" SG_ 753 VCFRONT_ESPValveCurrent 1;
BA_ "Confidence" SG_ 753 VCFRONT_autopilot2State 1;
BA_ "Confidence" SG_ 753 VCFRONT_autopilot2Temp 1;
BA_ "Confidence" SG_ 753 VCFRONT_autopilot2Voltage 1;
BA_ "Confidence" SG_ 753 VCFRONT_autopilot2Current 1;
BA_ "Confidence" SG_ 753 VCFRONT_sleepBypassState 1;
BA_ "Confidence" SG_ 753 VCFRONT_sleepBypassVoltage 1;
BA_ "Confidence" SG_ 753 VCFRONT_sleepBypassCurrent 1;
BA_ "Confidence" SG_ 753 VCFRONT_vbatFusedSelfTestResult 1;
BA_ "Confidence" SG_ 753 VCFRONT_vbatFusedHighTemp 1;
BA_ "Confidence" SG_ 753 VCFRONT_vbatFusedHighVoltage 1;
BA_ "Confidence" SG_ 753 VCFRONT_vbatFusedHighCurrent 1;
BA_ "Confidence" SG_ 753 VCFRONT_chargedIBSAmpHours 1;
BA_ "Confidence" SG_ 753 VCFRONT_dischargedIBSAmpHours 1;
BA_ "Confidence" SG_ 753 VCFRONT_IBSUnfilteredTemperature 1;
BA_ "Confidence" SG_ 769 VCFRONT_infoBuildType 1;
BA_ "Confidence" SG_ 1014 VCFRONT_lowBeamLeftStatus 1;
BA_ "Confidence" SG_ 1014 VCFRONT_lowBeamRightStatus 1;
BA_ "Confidence" SG_ 1014 VCFRONT_highBeamLeftStatus 1;
BA_ "Confidence" SG_ 1014 VCFRONT_highBeamRightStatus 1;
BA_ "Confidence" SG_ 1014 VCFRONT_DRLLeftStatus 1;
BA_ "Confidence" SG_ 1014 VCFRONT_DRLRightStatus 1;
BA_ "Confidence" SG_ 1014 VCFRONT_fogLeftStatus 1;
BA_ "Confidence" SG_ 1014 VCFRONT_fogRightStatus 1;
BA_ "Confidence" SG_ 1014 VCFRONT_sideMarkersStatus 1;
BA_ "Confidence" SG_ 1014 VCFRONT_sideRepeaterLeftStatus 1;
BA_ "Confidence" SG_ 1014 VCFRONT_sideRepeaterRightStatus 1;
BA_ "Confidence" SG_ 1014 VCFRONT_turnSignalLeftStatus 1;
BA_ "Confidence" SG_ 1014 VCFRONT_turnSignalRightStatus 1;
BA_ "Confidence" SG_ 1014 VCFRONT_parkLeftStatus 1;
BA_ "Confidence" SG_ 1014 VCFRONT_parkRightStatus 1;
BA_ "SystemSignalLongSymbol" SG_ 1014 VCFRONT_lowBeamLeftReadyForAimin "VCFRONT_lowBeamLeftReadyForAiming";
BA_ "SystemSignalLongSymbol" SG_ 1014 VCFRONT_lowBeamRightReadyForAimi "VCFRONT_lowBeamRightReadyForAiming";
BA_ "Confidence" SG_ 1014 VCFRONT_lowBeamsOnForDRL 1;
BA_ "Confidence" SG_ 1014 VC_rightHeadlampHealth 1;
BA_ "Confidence" SG_ 1014 VC_leftHeadlampHealth 1;
BA_ "Confidence" SG_ 1014 VCFRONT_isAdaptiveHighBeamAvaila 1;
BA_ "SystemSignalLongSymbol" SG_ 1014 VCFRONT_isAdaptiveHighBeamAvaila "VCFRONT_isAdaptiveHighBeamAvailable";
BA_ "Confidence" SG_ 1014 VCFRONT_isAdaptiveHighBeamFaulte 1;
BA_ "SystemSignalLongSymbol" SG_ 1014 VCFRONT_isAdaptiveHighBeamFaulte "VCFRONT_isAdaptiveHighBeamFaulted";
BA_ "Confidence" SG_ 1014 VCFRONT_isBendLightingAvailable 1;
BA_ "Confidence" SG_ 1014 VCFRONT_advancedDrivingBeamStatu 1;
BA_ "SystemSignalLongSymbol" SG_ 1014 VCFRONT_advancedDrivingBeamStatu "VCFRONT_advancedDrivingBeamStatus";
BA_ "Confidence" SG_ 1014 VCFRONT_headlampBendAngle 1;
BA_ "Confidence" SG_ 1014 VCFRONT_headlampRoadClass 1;
BA_ "Confidence" SG_ 1013 VCFRONT_indicatorLeftRequest 1;
BA_ "Confidence" SG_ 1013 VCFRONT_indicatorRightRequest 1;
BA_ "Confidence" SG_ 1013 VCFRONT_hazardLightRequest 1;
BA_ "Confidence" SG_ 1013 VCFRONT_ambientLightingBrightnes 1;
BA_ "Confidence" SG_ 1013 VCFRONT_switchLightingBrightness 1;
BA_ "Confidence" SG_ 1013 VCFRONT_courtesyLightingRequest 1;
BA_ "Confidence" SG_ 1013 VCFRONT_highBeamControlState 1;
BA_ "Confidence" SG_ 1013 VCFRONT_dynamicBrakeLightState 1;
BA_ "Confidence" SG_ 1013 VCFRONT_lightingCoreState 1;
BA_ "Confidence" SG_ 1013 VCFRONT_intHighBeamsFunctionStat 1;
BA_ "SystemSignalLongSymbol" SG_ 1013 VCFRONT_intHighBeamsFunctionStat "VCFRONT_intHighBeamsFunctionState";
BA_ "Confidence" SG_ 1013 VCFRONT_latchedHighBeamsFunction 1;
BA_ "SystemSignalLongSymbol" SG_ 1013 VCFRONT_latchedHighBeamsFunction "VCFRONT_latchedHighBeamsFunctionState";
BA_ "Confidence" SG_ 1013 VCFRONT_frontFogFunctionState 1;
BA_ "SystemSignalLongSymbol" SG_ 1013 VCFRONT_headlightsReadyOrTimedOu "VCFRONT_headlightsReadyOrTimedOut";
BA_ "Confidence" SG_ 1013 VCFRONT_turnIndicatorStalk 1;
BA_ "Confidence" SG_ 1013 VCFRONT_highBeamLatchingState 1;
BA_ "Confidence" SG_ 1013 VCFRONT_lightingCustomState 1;
BA_ "Confidence" SG_ 1013 VCFRONT_indicatorLeftInternal 1;
BA_ "Confidence" SG_ 1013 VCFRONT_indicatorRightInternal 1;
BA_ "Confidence" SG_ 1801 VC_hcmlFactoryOfOrigin 1;
BA_ "Confidence" SG_ 1801 VC_hcmlHellaPartNumberStatus 1;
BA_ "Confidence" SG_ 1801 VC_hcmlHellaPartNumber 1;
BA_ "Confidence" SG_ 1801 VC_hcmlCurrentBinMappingType 1;
BA_ "Confidence" SG_ 1801 VC_hcmlCurrentBin0Value 1;
BA_ "Confidence" SG_ 1801 VC_hcmlCurrentBin1Value 1;
BA_ "Confidence" SG_ 1801 VC_hcmlCurrentBin2Value 1;
BA_ "Confidence" SG_ 1801 VC_hcmlCurrentBin3Value 1;
BA_ "Confidence" SG_ 1801 VC_hcmlCurrentBin4Value 1;
BA_ "Confidence" SG_ 1801 VC_hcmlCurrentBin5Value 1;
BA_ "Confidence" SG_ 1801 VC_hcmlRegionAndSide 1;
BA_ "Confidence" SG_ 1801 VC_hcmrFactoryOfOrigin 1;
BA_ "Confidence" SG_ 1801 VC_hcmrHellaPartNumberStatus 1;
BA_ "Confidence" SG_ 1801 VC_hcmrHellaPartNumber 1;
BA_ "Confidence" SG_ 1801 VC_hcmrCurrentBinMappingType 1;
BA_ "Confidence" SG_ 1801 VC_hcmrCurrentBin0Value 1;
BA_ "Confidence" SG_ 1801 VC_hcmrCurrentBin1Value 1;
BA_ "Confidence" SG_ 1801 VC_hcmrCurrentBin2Value 1;
BA_ "Confidence" SG_ 1801 VC_hcmrCurrentBin3Value 1;
BA_ "Confidence" SG_ 1801 VC_hcmrCurrentBin4Value 1;
BA_ "Confidence" SG_ 1801 VC_hcmrCurrentBin5Value 1;
BA_ "Confidence" SG_ 1801 VC_hcmrRegionAndSide 1;
BA_ "Confidence" SG_ 705 VCFRONT_pumpBatteryOutVoltage 1;
BA_ "Confidence" SG_ 705 VCFRONT_pumpPowertrainOutVoltage 1;
BA_ "Confidence" SG_ 705 VCFRONT_coolantFlowChillerActual 1;
BA_ "Confidence" SG_ 705 VCFRONT_radiatorFanOutVoltage 1;
BA_ "Confidence" SG_ 705 VCFRONT_radiatorFanEnabled 1;
BA_ "Confidence" SG_ 705 VCFRONT_radiatorFanPowerOn 1;
BA_ "Confidence" SG_ 705 VCFRONT_radiatorFanPhaseCurrent 1;
BA_ "Confidence" SG_ 705 VCFRONT_radiatorFanPhaseIMax 1;
BA_ "SystemSignalLongSymbol" SG_ 705 VCFRONT_chargeTrapNominalCOP1Bat "VCFRONT_chargeTrapNominalCOP1BattHeat";
BA_ "SystemSignalLongSymbol" SG_ 705 VCFRONT_chargeTrapNominalCOP1Chi "VCFRONT_chargeTrapNominalCOP1ChillerBattHeat";
BA_ "Confidence" SG_ 897 VCFRONT_modeTransitionID 1;
BA_ "Confidence" SG_ 897 VCFRONT_modeDesired 1;
BA_ "Confidence" SG_ 897 VCFRONT_targetPTActiveCool 1;
BA_ "Confidence" SG_ 897 VCFRONT_targetPtOptionalActiveCo 1;
BA_ "SystemSignalLongSymbol" SG_ 897 VCFRONT_targetPtOptionalActiveCo "VCFRONT_targetPtOptionalActiveCool";
BA_ "Confidence" SG_ 897 VCFRONT_targetPTPassive 1;
BA_ "Confidence" SG_ 897 VCFRONT_targetBatActiveCool 1;
BA_ "Confidence" SG_ 897 VCFRONT_targetBatOptionalActiveC 1;
BA_ "SystemSignalLongSymbol" SG_ 897 VCFRONT_targetBatOptionalActiveC "VCFRONT_targetBatOptionalActiveCool";
BA_ "Confidence" SG_ 897 VCFRONT_targetBatPassive 1;
BA_ "Confidence" SG_ 897 VCFRONT_targetBatActiveHeat 1;
BA_ "Confidence" SG_ 897 VCFRONT_condenserPressureLimit 1;
BA_ "Confidence" SG_ 897 VCFRONT_fanDemandCondenser 1;
BA_ "Confidence" SG_ 897 VCFRONT_fanDemandRadiator 1;
BA_ "Confidence" SG_ 897 VCFRONT_tempRefrigSuction 1;
BA_ "Confidence" SG_ 897 VCFRONT_pumpBatteryFETTemp 1;
BA_ "Confidence" SG_ 897 VCFRONT_pumpPowertrainFETTemp 1;
BA_ "Confidence" SG_ 897 VCFRONT_radiatorFanFETTemp 1;
BA_ "Confidence" SG_ 897 VCFRONT_radiatorFanRunReason 1;
BA_ "Confidence" SG_ 897 VCFRONT_coolantTempBasedMode 1;
BA_ "Confidence" SG_ 897 VCFRONT_coolantValveRecalReason 1;
BA_ "Confidence" SG_ 897 VCFRONT_coolantValveCountRange 1;
BA_ "Confidence" SG_ 897 VCFRONT_coolantValveAngleDrift 1;
BA_ "Confidence" SG_ 897 VCFRONT_coolantValveRecalCount 1;
BA_ "Confidence" SG_ 897 VCFRONT_coolantValveWindupEst 1;
BA_ "Confidence" SG_ 897 VCFRONT_coolantValveRadBypass 1;
BA_ "Confidence" SG_ 897 VCFRONT_hpChargeCableType 1;
BA_ "Confidence" SG_ 897 VCFRONT_subcoolActual 1;
BA_ "Confidence" SG_ 897 VCFRONT_hpSubcoolTarget 1;
BA_ "Confidence" SG_ 897 VCFRONT_CMPDischargeSuperheat 1;
BA_ "Confidence" SG_ 897 VCFRONT_hpCOP 1;
BA_ "Confidence" SG_ 897 VCFRONT_lowSideWattsLift 1;
BA_ "Confidence" SG_ 897 VCFRONT_tempSuperheatActual 1;
BA_ "Confidence" SG_ 897 VCFRONT_tempSuperheatTarget 1;
BA_ "Confidence" SG_ 897 VCFRONT_refCommissionStatus 1;
BA_ "Confidence" SG_ 897 VCFRONT_LCCPurgeActive 1;
BA_ "Confidence" SG_ 897 VCFRONT_CCQdotFdFrwrdTarget 1;
BA_ "Confidence" SG_ 897 VCFRONT_CCQdotFdbk 1;
BA_ "Confidence" SG_ 897 VCFRONT_CCQdotActual 1;
BA_ "Confidence" SG_ 897 VCFRONT_evapFdFrwrdTarget 1;
BA_ "Confidence" SG_ 897 VCFRONT_evapFdbk 1;
BA_ "Confidence" SG_ 897 VCFRONT_DIQdotA 1;
BA_ "Confidence" SG_ 897 VCFRONT_evapFdFrwrdTargetMinimum 1;
BA_ "Confidence" SG_ 897 VCFRONT_passiveCoolingState 1;
BA_ "SystemSignalLongSymbol" SG_ 897 VCFRONT_feedfwdLoadCoolingDomina "VCFRONT_feedfwdLoadCoolingDominant";
BA_ "Confidence" SG_ 897 VCFRONT_hpRefrigerantPurgeState 1;
BA_ "Confidence" SG_ 897 VCFRONT_estPressureLiq 1;
BA_ "Confidence" SG_ 897 VCFRONT_estPressureSuct 1;
BA_ "Confidence" SG_ 897 VCFRONT_estPressureDisch 1;
BA_ "Confidence" SG_ 897 VCFRONT_estTempLiq 1;
BA_ "Confidence" SG_ 897 VCFRONT_estTempSuct 1;
BA_ "Confidence" SG_ 897 VCFRONT_estTempDisch 1;
BA_ "Confidence" SG_ 897 VCFRONT_estCompressorRpm 1;
BA_ "Confidence" SG_ 897 VCFRONT_estQLift 1;
BA_ "Confidence" SG_ 897 VCFRONT_chillerExvCalibOffset 1;
BA_ "Confidence" SG_ 897 VCFRONT_evapExvCalibOffset 1;
BA_ "Confidence" SG_ 897 VCFRONT_recircExvCalibOffset 1;
BA_ "Confidence" SG_ 897 VCFRONT_lccExvCalibOffset 1;
BA_ "Confidence" SG_ 897 VCFRONT_ccLeftExvCalibOffset 1;
BA_ "Confidence" SG_ 897 VCFRONT_ccRightExvCalibOffset 1;
BA_ "Confidence" SG_ 897 VCFRONT_chillerEXVControlState 1;
BA_ "Confidence" SG_ 897 VCFRONT_evapEXVControlState 1;
BA_ "Confidence" SG_ 897 VCFRONT_recircEXVControlState 1;
BA_ "Confidence" SG_ 897 VCFRONT_lccEXVControlState 1;
BA_ "Confidence" SG_ 897 VCFRONT_cclEXVControlState 1;
BA_ "Confidence" SG_ 897 VCFRONT_ccrEXVControlState 1;
BA_ "Confidence" SG_ 897 VCFRONT_chillerExvCalibFailed 1;
BA_ "Confidence" SG_ 897 VCFRONT_evapExvCalibFailed 1;
BA_ "Confidence" SG_ 897 VCFRONT_recircExvCalibFailed 1;
BA_ "Confidence" SG_ 897 VCFRONT_lccExvCalibFailed 1;
BA_ "Confidence" SG_ 897 VCFRONT_ccLeftExvCalibFailed 1;
BA_ "Confidence" SG_ 897 VCFRONT_ccRightExvCalibFailed 1;
BA_ "SystemSignalLongSymbol" SG_ 897 VCFRONT_ambientTempPassiveSniffi "VCFRONT_ambientTempPassiveSniffing";
BA_ "Confidence" SG_ 897 VCFRONT_feedFwdMDotEvaporator 1;
BA_ "SystemSignalLongSymbol" SG_ 897 VCFRONT_hpCabinHeatBatteryHeatAm "VCFRONT_hpCabinHeatBatteryHeatAmbSrc";
BA_ "SystemSignalLongSymbol" SG_ 897 VCFRONT_hpCabinHeatBatteryHeatCO "VCFRONT_hpCabinHeatBatteryHeatCOP1";
BA_ "Confidence" SG_ 897 VCFRONT_feedFwdMDotCabinCondense 1;
BA_ "SystemSignalLongSymbol" SG_ 897 VCFRONT_feedFwdMDotCabinCondense "VCFRONT_feedFwdMDotCabinCondenser";
BA_ "Confidence" SG_ 897 VCFRONT_feedBackEvapTempControll 1;
BA_ "SystemSignalLongSymbol" SG_ 897 VCFRONT_feedBackEvapTempControll "VCFRONT_feedBackEvapTempController";
BA_ "Confidence" SG_ 897 VCFRONT_feedBackDuctTempControll 1;
BA_ "SystemSignalLongSymbol" SG_ 897 VCFRONT_feedBackDuctTempControll "VCFRONT_feedBackDuctTempController";
BA_ "Confidence" SG_ 897 VCFRONT_maxChillerCoolingPower 1;
BA_ "Confidence" SG_ 897 VCFRONT_fanControlRadiatorUa 1;
BA_ "Confidence" SG_ 897 VCFRONT_fanControlRadiatorInletT 1;
BA_ "SystemSignalLongSymbol" SG_ 897 VCFRONT_fanControlRadiatorInletT "VCFRONT_fanControlRadiatorInletTemp";
BA_ "SystemSignalLongSymbol" SG_ 897 VCFRONT_hpASBatteryHeatingAllowe "VCFRONT_hpASBatteryHeatingAllowed";
BA_ "SystemSignalLongSymbol" SG_ 897 VCFRONT_hpCOP1BatteryHeatingAllo "VCFRONT_hpCOP1BatteryHeatingAllowed";
BA_ "SystemSignalLongSymbol" SG_ 897 VCFRONT_hpCabinHeatReheatScaveng "VCFRONT_hpCabinHeatReheatScavenge";
BA_ "SystemSignalLongSymbol" SG_ 897 VCFRONT_hpCabinHeatReheatAmbient "VCFRONT_hpCabinHeatReheatAmbientSource";
BA_ "SystemSignalLongSymbol" SG_ 897 VCFRONT_hpCabinHeatBatteryHeatRe "VCFRONT_hpCabinHeatBatteryHeatReheatAmbSrc";
BA_ "SystemSignalLongSymbol" SG_ 897 VCFRONT_hpCabinHeatBatteryCoolRe "VCFRONT_hpCabinHeatBatteryCoolReheat";
BA_ "SystemSignalLongSymbol" SG_ 897 VCFRONT_hpCabinCoolEvaporatorReh "VCFRONT_hpCabinCoolEvaporatorReheat";
BA_ "SystemSignalLongSymbol" SG_ 897 VCFRONT_hpBatteryHeatAmbientSour "VCFRONT_hpBatteryHeatAmbientSource";
BA_ "SystemSignalLongSymbol" SG_ 897 VCFRONT_hpBatteryCoolCabinConden "VCFRONT_hpBatteryCoolCabinCondenserCD";
BA_ "SystemSignalLongSymbol" SG_ 897 VCFRONT_hpBatteryCoolCabinC_0001 "VCFRONT_hpBatteryCoolCabinCondenserHD";
BA_ "Confidence" SG_ 897 VCFRONT_suctionSuperheatEstTsSNA 1;
BA_ "Confidence" SG_ 897 VCFRONT_tempRefrigSuctionEst 1;
BA_ "SystemSignalLongSymbol" SG_ 897 VCFRONT_hpBattOverTempHvacDisabl "VCFRONT_hpBattOverTempHvacDisable";
BA_ "Confidence" SG_ 897 VCFRONT_hpDiagLouverCalib 1;
BA_ "Confidence" SG_ 897 VCFRONT_estPressureDischargeSat 1;
BA_ "Confidence" SG_ 897 VCFRONT_tempRefrigLiquid 1;
BA_ "Confidence" SG_ 897 VCFRONT_totalBattHeatingPower 1;
BA_ "SystemSignalLongSymbol" SG_ 897 VCFRONT_hpPotentialFrozenRadiato "VCFRONT_hpPotentialFrozenRadiator";
BA_ "Confidence" SG_ 897 VCFRONT_passiveDemandRadBypass 1;
BA_ "Confidence" SG_ 897 VCFRONT_targetLccActiveCoolCap 1;
BA_ "Confidence" SG_ 897 VCFRONT_targetLccActiveCoolEff 1;
BA_ "Confidence" SG_ 897 VCFRONT_coolantValveDailyAngleTr 1;
BA_ "SystemSignalLongSymbol" SG_ 897 VCFRONT_coolantValveDailyAngleTr "VCFRONT_coolantValveDailyAngleTravel";
BA_ "Confidence" SG_ 897 VCFRONT_dischargePressureLimit 1;
BA_ "Confidence" SG_ 897 VCFRONT_radBypassMoveReason 1;
BA_ "Confidence" SG_ 897 VCFRONT_hpBattHeatingPower 1;
BA_ "SystemSignalLongSymbol" SG_ 897 VCFRONT_tempCoolantPTInletEstSta "VCFRONT_tempCoolantPTInletEstStatus";
BA_ "Confidence" SG_ 897 VCFRONT_hpColdStagnationLimit 1;
BA_ "Confidence" SG_ 897 VCFRONT_hpHotStagnationLimit 1;
BA_ "Confidence" SG_ 897 VCFRONT_hpCompFlowIndex 1;
BA_ "Confidence" SG_ 897 VCFRONT_hpCompFlowIndexFiltered 1;
BA_ "Confidence" SG_ 897 VCFRONT_subcoolEstTlSNA 1;
BA_ "Confidence" SG_ 897 VCFRONT_subcoolEstPlSNA 1;
BA_ "Confidence" SG_ 897 VCFRONT_tempRefrigLiquidEst 1;
BA_ "Confidence" SG_ 897 VCFRONT_pressureRefrigLiquidEst 1;
BA_ "Confidence" SG_ 897 VCFRONT_louverPosReason 1;
BA_ "Confidence" SG_ 897 VCFRONT_hpEnergyFlowIndex 1;
BA_ "Confidence" SG_ 897 VCFRONT_hpEnergyFlowIndexFiltere 1;
BA_ "SystemSignalLongSymbol" SG_ 897 VCFRONT_hpEnergyFlowIndexFiltere "VCFRONT_hpEnergyFlowIndexFiltered";
BA_ "Confidence" SG_ 897 VCFRONT_minCompressorRPMAllowed 1;
BA_ "Confidence" SG_ 897 VCFRONT_ccRefrigerantMassFlow 1;
BA_ "Confidence" SG_ 897 VCFRONT_highSideDpResidual 1;
BA_ "SystemSignalLongSymbol" SG_ 897 VCFRONT_abnormalHighSuctionSuper "VCFRONT_abnormalHighSuctionSuperheat";
BA_ "Confidence" SG_ 897 VCFRONT_coolantValveAngleTravel 1;
BA_ "Confidence" SG_ 897 VCFRONT_chargeShuttleType 1;
BA_ "SystemSignalLongSymbol" SG_ 897 VCFRONT_hpRefrigTempSensorCheckC "VCFRONT_hpRefrigTempSensorCheckCanFire";
BA_ "SystemSignalLongSymbol" SG_ 897 VCFRONT_hpRefrigPressureSensorCh "VCFRONT_hpRefrigPressureSensorCheckCanFire";
BA_ "Confidence" SG_ 897 VCFRONT_tempSuperheatActFiltered 1;
BA_ "Confidence" SG_ 897 VCFRONT_tempRefrigDischarge 1;
BA_ "Confidence" SG_ 897 VCFRONT_pumpBatteryRPMTarget 1;
BA_ "Confidence" SG_ 897 VCFRONT_pumpPowertrainRPMTarget 1;
BA_ "Confidence" SG_ 897 VCFRONT_coolantFlowChillerTarget 1;
BA_ "Confidence" SG_ 897 VCFRONT_radiatorFanRPMTarget 1;
BA_ "Confidence" SG_ 897 VCFRONT_batteryDischArbState 1;
BA_ "SystemSignalLongSymbol" SG_ 897 VCFRONT_preventReEntryTillNexthp "VCFRONT_preventReEntryTillNexthpResetCOP1";
BA_ "SystemSignalLongSymbol" SG_ 897 VCFRONT_chillerBattHeatingPowerA "VCFRONT_chillerBattHeatingPowerAvailable";
BA_ "SystemSignalLongSymbol" SG_ 897 VCFRONT_isExpectedQChillerVeryHi "VCFRONT_isExpectedQChillerVeryHighCOP1";
BA_ "Confidence" SG_ 897 VCFRONT_superheatProtectionLimit 1;
BA_ "Confidence" SG_ 897 VCFRONT_chillerDemandWatts 1;
BA_ "Confidence" SG_ 897 VCFRONT_nominalTevapHWLimit 1;
BA_ "Confidence" SG_ 897 VCFRONT_ambientTempState 1;
BA_ "Confidence" SG_ 897 VCFRONT_ambientTempUnlatchReason 1;
BA_ "Confidence" SG_ 897 VCFRONT_compressorSuctionVaporQu 1;
BA_ "SystemSignalLongSymbol" SG_ 897 VCFRONT_compressorSuctionVaporQu "VCFRONT_compressorSuctionVaporQuality";
BA_ "Confidence" SG_ 897 VCFRONT_cabinHeatingCOP1MinActiv 1;
BA_ "SystemSignalLongSymbol" SG_ 897 VCFRONT_cabinHeatingCOP1MinActiv "VCFRONT_cabinHeatingCOP1MinActiveRefCharge";
BA_ "SystemSignalLongSymbol" SG_ 513 VCFRONT_loggingAndVitals10HzInde "VCFRONT_loggingAndVitals10HzIndex";
BA_ "Confidence" SG_ 513 VCFRONT_pumpBatteryRPMActual 1;
BA_ "Confidence" SG_ 513 VCFRONT_pumpPowertrainRPMActual 1;
BA_ "Confidence" SG_ 513 VCFRONT_radiatorFanRPMActual 1;
BA_ "Confidence" SG_ 513 VCFRONT_exvFlowTarget 1;
BA_ "Confidence" SG_ 513 VCFRONT_activeLouverOpenPosTarg 1;
BA_ "Confidence" SG_ 513 VCFRONT_pressureRefrigLiquid 1;
BA_ "Confidence" SG_ 513 VCFRONT_fanDemand 1;
BA_ "Confidence" SG_ 513 VCFRONT_compressorState 1;
BA_ "Confidence" SG_ 513 VCFRONT_compDemandEvap 1;
BA_ "Confidence" SG_ 513 VCFRONT_exvState 1;
BA_ "Confidence" SG_ 513 VCFRONT_solenoidEvapState 1;
BA_ "Confidence" SG_ 513 VCFRONT_compDemandChiller 1;
BA_ "Confidence" SG_ 513 VCFRONT_coolantValveMode 1;
BA_ "Confidence" SG_ 513 VCFRONT_compFaultSeverity 1;
BA_ "Confidence" SG_ 513 VCFRONT_hpHighSideHX 1;
BA_ "Confidence" SG_ 513 VCFRONT_hpLowSideHX 1;
BA_ "Confidence" SG_ 513 VCFRONT_hpDominantLoad 1;
BA_ "Confidence" SG_ 513 VCFRONT_hpBlendType 1;
BA_ "Confidence" SG_ 513 VCFRONT_hpCabinLoadType 1;
BA_ "Confidence" SG_ 513 VCFRONT_hpBatteryLoadType 1;
BA_ "Confidence" SG_ 513 VCFRONT_hpReqCoolantMode 1;
BA_ "Confidence" SG_ 513 VCFRONT_compLiqPumpOutState 1;
BA_ "Confidence" SG_ 513 VCFRONT_frunkStateDBG 1;
BA_ "Confidence" SG_ 513 VCFRONT_frunkSwitchGroupState 1;
BA_ "Confidence" SG_ 513 VCFRONT_chillerExvFlow 1;
BA_ "Confidence" SG_ 513 VCFRONT_evapExvFlow 1;
BA_ "Confidence" SG_ 513 VCFRONT_recircExvFlow 1;
BA_ "Confidence" SG_ 513 VCFRONT_lccExvFlow 1;
BA_ "Confidence" SG_ 513 VCFRONT_cclExvFlow 1;
BA_ "Confidence" SG_ 513 VCFRONT_ccrExvFlow 1;
BA_ "Confidence" SG_ 513 VCFRONT_chillerExvState 1;
BA_ "Confidence" SG_ 513 VCFRONT_evapExvState 1;
BA_ "Confidence" SG_ 513 VCFRONT_recircExvState 1;
BA_ "Confidence" SG_ 513 VCFRONT_chillerExvFlowTarget 1;
BA_ "Confidence" SG_ 513 VCFRONT_evapExvFlowTarget 1;
BA_ "Confidence" SG_ 513 VCFRONT_recircExvFlowTarget 1;
BA_ "Confidence" SG_ 513 VCFRONT_lccExvFlowTarget 1;
BA_ "Confidence" SG_ 513 VCFRONT_cclExvFlowTarget 1;
BA_ "Confidence" SG_ 513 VCFRONT_ccrExvFlowTarget 1;
BA_ "Confidence" SG_ 513 VCFRONT_lccExvState 1;
BA_ "Confidence" SG_ 513 VCFRONT_cclExvState 1;
BA_ "Confidence" SG_ 513 VCFRONT_ccrExvState 1;
BA_ "Confidence" SG_ 957 VCFRONT_userEnergyLossSinceDrive 1;
BA_ "Confidence" SG_ 957 VCFRONT_preconditioningEner_0001 1;
BA_ "SystemSignalLongSymbol" SG_ 957 VCFRONT_preconditioningEner_0001 "VCFRONT_preconditioningEnergyLossSinceDrive";
BA_ "Confidence" SG_ 957 VCFRONT_cabinOverheatEnergy_0001 1;
BA_ "SystemSignalLongSymbol" SG_ 957 VCFRONT_cabinOverheatEnergy_0001 "VCFRONT_cabinOverheatEnergyLossSinceDrive";
BA_ "Confidence" SG_ 957 VCFRONT_mobileAppEnergyLoss_0001 1;
BA_ "SystemSignalLongSymbol" SG_ 957 VCFRONT_mobileAppEnergyLoss_0001 "VCFRONT_mobileAppEnergyLossSinceDrive";
BA_ "Confidence" SG_ 957 VCFRONT_summonStandbyEnergy_0001 1;
BA_ "SystemSignalLongSymbol" SG_ 957 VCFRONT_summonStandbyEnergy_0001 "VCFRONT_summonStandbyEnergyLossSinceDrive";
BA_ "Confidence" SG_ 957 VCFRONT_sentryModeEnergyLos_0001 1;
BA_ "SystemSignalLongSymbol" SG_ 957 VCFRONT_sentryModeEnergyLos_0001 "VCFRONT_sentryModeEnergyLossSinceDrive";
BA_ "Confidence" SG_ 957 VCFRONT_backgroundEnergyLos_0001 1;
BA_ "SystemSignalLongSymbol" SG_ 957 VCFRONT_backgroundEnergyLos_0001 "VCFRONT_backgroundEnergyLossSinceDrive";
BA_ "Confidence" SG_ 957 VCFRONT_evapDryingEnergyLos_0001 1;
BA_ "SystemSignalLongSymbol" SG_ 957 VCFRONT_evapDryingEnergyLos_0001 "VCFRONT_evapDryingEnergyLossSinceDrive";
BA_ "Confidence" SG_ 957 VCFRONT_userEnergyLossSinceCharg 1;
BA_ "SystemSignalLongSymbol" SG_ 957 VCFRONT_userEnergyLossSinceCharg "VCFRONT_userEnergyLossSinceCharge";
BA_ "Confidence" SG_ 957 VCFRONT_preconditioningEnergyLos 1;
BA_ "SystemSignalLongSymbol" SG_ 957 VCFRONT_preconditioningEnergyLos "VCFRONT_preconditioningEnergyLossSinceCharge";
BA_ "Confidence" SG_ 957 VCFRONT_cabinOverheatEnergyLossS 1;
BA_ "SystemSignalLongSymbol" SG_ 957 VCFRONT_cabinOverheatEnergyLossS "VCFRONT_cabinOverheatEnergyLossSinceCharge";
BA_ "Confidence" SG_ 957 VCFRONT_mobileAppEnergyLossSince 1;
BA_ "SystemSignalLongSymbol" SG_ 957 VCFRONT_mobileAppEnergyLossSince "VCFRONT_mobileAppEnergyLossSinceCharge";
BA_ "Confidence" SG_ 957 VCFRONT_summonStandbyEnergyLossS 1;
BA_ "SystemSignalLongSymbol" SG_ 957 VCFRONT_summonStandbyEnergyLossS "VCFRONT_summonStandbyEnergyLossSinceCharge";
BA_ "Confidence" SG_ 957 VCFRONT_sentryModeEnergyLossSinc 1;
BA_ "SystemSignalLongSymbol" SG_ 957 VCFRONT_sentryModeEnergyLossSinc "VCFRONT_sentryModeEnergyLossSinceCharge";
BA_ "Confidence" SG_ 957 VCFRONT_backgroundEnergyLossSinc 1;
BA_ "SystemSignalLongSymbol" SG_ 957 VCFRONT_backgroundEnergyLossSinc "VCFRONT_backgroundEnergyLossSinceCharge";
BA_ "Confidence" SG_ 957 VCFRONT_evapDryingEnergyLossSinc 1;
BA_ "SystemSignalLongSymbol" SG_ 957 VCFRONT_evapDryingEnergyLossSinc "VCFRONT_evapDryingEnergyLossSinceCharge";
BA_ "Confidence" SG_ 260 VCFRONT_vehicleSM 1;
BA_ "Confidence" SG_ 260 VCFRONT_battSM 1;
BA_ "Confidence" SG_ 260 VCFRONT_battVoltage 1;
BA_ "Confidence" SG_ 260 VCFRONT_battCurrent 1;
BA_ "Confidence" SG_ 801 VCFRONT_tempCoolantBatInlet 1;
BA_ "Confidence" SG_ 801 VCFRONT_tempCoolantPTInlet 1;
BA_ "Confidence" SG_ 801 VCFRONT_coolantLevel 1;
BA_ "Confidence" SG_ 801 VCFRONT_brakeFluidLevel 1;
BA_ "Confidence" SG_ 801 VCFRONT_tempAmbient 1;
BA_ "Confidence" SG_ 801 VCFRONT_washerFluidLevel 1;
BA_ "Confidence" SG_ 801 VCFRONT_tempAmbientFiltered 1;
BA_ "Confidence" SG_ 737 VCFRONT_frunkLatchStatus 1;
BA_ "Confidence" SG_ 737 VCFRONT_wiperSpeed 1;
BA_ "Confidence" SG_ 737 VCFRONT_wiperPosition 1;
BA_ "Confidence" SG_ 737 VCFRONT_wiperBlocked 1;
BA_ "Confidence" SG_ 737 VCFRONT_wiperState 1;
BA_ "Confidence" SG_ 737 VCFRONT_crashDetectedType 1;
BA_ "Confidence" SG_ 737 VCFRONT_crashState 1;
BA_ "Confidence" SG_ 737 VCFRONT_crashUnlockOverrideSet 1;
BA_ "Confidence" SG_ 737 VCFRONT_washPumpState 1;
BA_ "Confidence" SG_ 737 VCFRONT_turnIndicatorControlType 1;
BA_ "Confidence" SG_ 737 VCFRONT_wiperHealth 1;
BA_ "Confidence" SG_ 737 VCFRONT_frunkLatchCurrent 1;
BA_ "Confidence" SG_ 737 VCFRONT_frunkInteriorRelSwitch 1;
BA_ "Confidence" SG_ 737 VCFRONT_hornOn 1;
BA_ "Confidence" SG_ 737 VCFRONT_radarHeaterState 1;
BA_ "Confidence" SG_ 737 VCFRONT_trunkExteriorWakeSwitch 1;
BA_ "Confidence" SG_ 737 VCFRONT_passengerBuckleStatus 1;
BA_ "Confidence" SG_ 737 VCFRONT_frunkLatchType 1;
BA_ "Confidence" SG_ 737 VCFRONT_iBoosterStateDBG 1;
BA_ "Confidence" SG_ 737 VCFRONT_vehicleStatusDBG 1;
BA_ "Confidence" SG_ 737 VCFRONT_timeSpentSleeping 1;
BA_ "Confidence" SG_ 737 VCFRONT_sleepCurrent 1;
BA_ "Confidence" SG_ 737 VCFRONT_hibernationState 1;
BA_ "Confidence" SG_ 737 VCFRONT_wiperECUType 1;
BA_ "Confidence" SG_ 737 VCFRONT_wiperHeaterState 1;
BA_ "Confidence" SG_ 737 VCFRONT_closureEasterEggState 1;
BA_ "Confidence" SG_ 737 VCFRONT_hvacReqOffForFasterCharg 1;
BA_ "SystemSignalLongSymbol" SG_ 737 VCFRONT_hvacReqOffForFasterCharg "VCFRONT_hvacReqOffForFasterCharge";
BA_ "Confidence" SG_ 737 VCFRONT_homelinkCommStatus 1;
BA_ "Confidence" SG_ 737 VCFRONT_maxEvapHeatRejection 1;
BA_ "Confidence" SG_ 737 VCFRONT_minEvapHeatRejection 1;
BA_ "Confidence" SG_ 737 VCFRONT_pressureRefrigSuction 1;
BA_ "Confidence" SG_ 737 VCFRONT_pressureRefrigDischarge 1;
BA_ "Confidence" SG_ 737 VCFRONT_hvacPerfTestCommand 1;
BA_ "Confidence" SG_ 737 VCFRONT_coolantFillRoutineStatus 1;
BA_ "Confidence" SG_ 737 VCFRONT_refrigFillRoutineStatus 1;
BA_ "Confidence" SG_ 737 VCFRONT_closeValvesRoutineStatus 1;
BA_ "Confidence" SG_ 737 VCFRONT_vbatMonitorVoltage 1;
BA_ "Confidence" SG_ 737 VCFRONT_AS8510Voltage 1;
BA_ "Confidence" SG_ 737 VCFRONT_vbatProt 1;
BA_ "SystemSignalLongSymbol" SG_ 737 VCFRONT_cabinCoolingCapacityLimi "VCFRONT_cabinCoolingCapacityLimited";
BA_ "SystemSignalLongSymbol" SG_ 737 VCFRONT_cabinHeatingCapacityLimi "VCFRONT_cabinHeatingCapacityLimited";
BA_ "Confidence" SG_ 737 VCFRONT_compPowerSupportingHvac 1;
BA_ "Confidence" SG_ 737 VCFRONT_compPowerSupportingPT 1;
BA_ "Confidence" SG_ 737 VCFRONT_maxHeatingPowerLeftCC 1;
BA_ "Confidence" SG_ 737 VCFRONT_maxHeatingPowerRightCC 1;
BA_ "Confidence" SG_ 737 VCFRONT_activeLouverOpenPos 1;
BA_ "Confidence" SG_ 737 VCFRONT_activeLouverState 1;
BA_ "Confidence" SG_ 737 VCFRONT_windshieldCameraHeaterPo 1;
BA_ "SystemSignalLongSymbol" SG_ 737 VCFRONT_windshieldCameraHeaterPo "VCFRONT_windshieldCameraHeaterPower";
BA_ "Confidence" SG_ 1349 VCFRONT_loadShedReason 1;
BA_ "SystemSignalLongSymbol" SG_ 1349 VCFRONT_VCRightEFuseLoadShedStag "VCFRONT_VCRightEFuseLoadShedStage";
BA_ "SystemSignalLongSymbol" SG_ 1349 VCFRONT_DCDCSaturationLoadShedSt "VCFRONT_DCDCSaturationLoadShedStage";
BA_ "Confidence" SG_ 1349 VCFRONT_vehicleLoadShedStage 1;
BA_ "SystemSignalLongSymbol" SG_ 1349 VCFRONT_HVFaultVehicleLoadShedRe "VCFRONT_HVFaultVehicleLoadShedRequest";
BA_ "SystemSignalLongSymbol" SG_ 1349 VCFRONT_postCrashVehicleLoadShed "VCFRONT_postCrashVehicleLoadShedActive";
BA_ "SystemSignalLongSymbol" SG_ 1349 VCFRONT_HVFaultVehicleLoadShedAc "VCFRONT_HVFaultVehicleLoadShedActive";
BA_ "Confidence" SG_ 1349 VCFRONT_factoryVehicleLoadShedAc 1;
BA_ "SystemSignalLongSymbol" SG_ 1349 VCFRONT_factoryVehicleLoadShedAc "VCFRONT_factoryVehicleLoadShedActive";
BA_ "Confidence" SG_ 1349 VCFRONT_HVFaultLoadShedStateDBG 1;
BA_ "SystemSignalLongSymbol" SG_ 1349 VCFRONT_LVUnhealthyVehicleLoadSh "VCFRONT_LVUnhealthyVehicleLoadShedActive";
BA_ "Confidence" SG_ 1349 VCFRONT_IBSCurrentRMS_loadShed 1;
BA_ "Confidence" SG_ 1349 VCFRONT_loadShedAhLeakyBktCntDBG 1;
BA_ "Confidence" SG_ 1349 VCFRONT_loadShedBackStopBktCntDB 1;
BA_ "SystemSignalLongSymbol" SG_ 1349 VCFRONT_loadShedBackStopBktCntDB "VCFRONT_loadShedBackStopBktCntDBG";
BA_ "Confidence" SG_ 1349 VCFRONT_loadShedPCSLeakyBktCtDBG 1;
BA_ "Confidence" SG_ 929 VCFRONT_APGlassHeaterState 1;
BA_ "Confidence" SG_ 929 VCFRONT_thermalSystemType 1;
BA_ "Confidence" SG_ 929 VCFRONT_diPowerOnState 1;
BA_ "Confidence" SG_ 929 VCFRONT_12vStatusForDrive 1;
BA_ "Confidence" SG_ 929 VCFRONT_dcr12VMilliOhms 1;
BA_ "Confidence" SG_ 929 VC_userPresenceState 1;
BA_ "Confidence" SG_ 929 VCFRONT_driverBuckleStatus 1;
BA_ "Confidence" SG_ 929 VCFRONT_driverDoorStatus 1;
BA_ "Confidence" SG_ 929 VCFRONT_driverUnbuckled 1;
BA_ "Confidence" SG_ 929 VCFRONT_passengerUnbuckled 1;
BA_ "Confidence" SG_ 929 VCFRONT_2RowLeftUnbuckled 1;
BA_ "Confidence" SG_ 929 VCFRONT_2RowCenterUnbuckled 1;
BA_ "Confidence" SG_ 929 VCFRONT_2RowRightUnbuckled 1;
BA_ "Confidence" SG_ 929 VCFRONT_pcsEFuseVoltage 1;
BA_ "Confidence" SG_ 929 VCFRONT_3RowLeftUnbuckled 1;
BA_ "Confidence" SG_ 929 VCFRONT_3RowRightUnbuckled 1;
BA_ "Confidence" SG_ 929 VCFRONT_maxBattHeatRejection 1;
BA_ "Confidence" SG_ 929 VCFRONT_hvacReqBattCoolOutTemp 1;
BA_ "Confidence" SG_ 929 VCFRONT_PCSCurrent 1;
BA_ "SystemSignalLongSymbol" SG_ 929 VCFRONT_driverEnteredCabinEstima "VCFRONT_driverEnteredCabinEstimateDBG";
BA_ "Confidence" SG_ 929 VCFRONT_hpBattHeatingPowerTrgt 1;
BA_ "Confidence" SG_ 507 VCLEFT_TLCTemperature 1;
BA_ "Confidence" SG_ 507 VCLEFT_TLCLeftTurnVoltage 1;
BA_ "Confidence" SG_ 507 VCLEFT_TLCRightTurnVoltage 1;
BA_ "Confidence" SG_ 507 VCLEFT_TLCState_LeftTurn 1;
BA_ "Confidence" SG_ 507 VCLEFT_TLCState_RightTurn 1;
BA_ "Confidence" SG_ 507 VCLEFT_TLCState_Tail 1;
BA_ "Confidence" SG_ 507 VCLEFT_TLCState_Stop 1;
BA_ "Confidence" SG_ 507 VCLEFT_TLCState_Fog 1;
BA_ "Confidence" SG_ 507 VCLEFT_TLCState_Reverse 1;
VAL_ 753 VCFRONT_leftControllerState 3 "EFUSE_STATE_SNA" 2 "EFUSE_STATE_LOCKED_OUT" 1 "EFUSE_STATE_ON" 0 "EFUSE_STATE_OFF" ;
VAL_ 753 VCFRONT_vcleftSelfTestResult 12 "EFUSE_SELF_TEST_EFUSE_RESULT_SNA" 11 "EFUSE_SELF_TEST_EFUSE_RESULT_SKIPPED" 10 "EFUSE_SELF_TEST_EFUSE_RESULT_FAILED_NOT_LATCHED" 9 "EFUSE_SELF_TEST_EFUSE_RESULT_FAILED_TURN_OFF_PATH_TOO_SLOW" 8 "EFUSE_SELF_TEST_EFUSE_RESULT_FAILED_ENABLE_HIGH_MALFUNCTION" 7 "EFUSE_SELF_TEST_EFUSE_RESULT_FAILED_POWER_FET_CHANNEL_OPEN" 6 "EFUSE_SELF_TEST_EFUSE_RESULT_FAILED_ENABLE_LOW_MALFUNCTION" 5 "EFUSE_SELF_TEST_EFUSE_RESULT_FAILED_POWER_FET_STUCK_ON" 4 "EFUSE_SELF_TEST_EFUSE_RESULT_FAILED_EFUSE_OUTPUT_SHORT" 3 "EFUSE_SELF_TEST_EFUSE_RESULT_FAILED_RAILS_UNSTABLE" 2 "EFUSE_SELF_TEST_EFUSE_RESULT_PASSED" 1 "EFUSE_SELF_TEST_EFUSE_RESULT_RUNNING" 0 "EFUSE_SELF_TEST_EFUSE_RESULT_NOT_RUN" ;
VAL_ 753 VCFRONT_leftControllerEFuseVNFSt 7 "EFUSE_ASIC_STATE_SELF_TEST" 6 "EFUSE_ASIC_STATE_SELF_TEST_PREP" 5 "EFUSE_ASIC_STATE_LOCKED" 4 "EFUSE_ASIC_STATE_UNLOCKED" 3 "EFUSE_ASIC_STATE_CONFIGURATION" 2 "EFUSE_ASIC_STATE_WAKEUP" 1 "EFUSE_ASIC_STATE_STANDBY" 0 "EFUSE_ASIC_STATE_UNKNOWN" ;
VAL_ 753 VCFRONT_leftControllerEFuseVNFSe 3 "EFUSE_SELF_TEST_SKIPPED" 2 "EFUSE_SELF_TEST_COMPLETE" 1 "EFUSE_SELF_TEST_ACTIVE" 0 "EFUSE_SELF_TEST_NOT_COMPLETE" ;
VAL_ 753 VCFRONT_PCSState 3 "EFUSE_STATE_SNA" 2 "EFUSE_STATE_LOCKED_OUT" 1 "EFUSE_STATE_ON" 0 "EFUSE_STATE_OFF" ;
VAL_ 753 VCFRONT_pcsSelfTestResult 12 "EFUSE_SELF_TEST_EFUSE_RESULT_SNA" 11 "EFUSE_SELF_TEST_EFUSE_RESULT_SKIPPED" 10 "EFUSE_SELF_TEST_EFUSE_RESULT_FAILED_NOT_LATCHED" 9 "EFUSE_SELF_TEST_EFUSE_RESULT_FAILED_TURN_OFF_PATH_TOO_SLOW" 8 "EFUSE_SELF_TEST_EFUSE_RESULT_FAILED_ENABLE_HIGH_MALFUNCTION" 7 "EFUSE_SELF_TEST_EFUSE_RESULT_FAILED_POWER_FET_CHANNEL_OPEN" 6 "EFUSE_SELF_TEST_EFUSE_RESULT_FAILED_ENABLE_LOW_MALFUNCTION" 5 "EFUSE_SELF_TEST_EFUSE_RESULT_FAILED_POWER_FET_STUCK_ON" 4 "EFUSE_SELF_TEST_EFUSE_RESULT_FAILED_EFUSE_OUTPUT_SHORT" 3 "EFUSE_SELF_TEST_EFUSE_RESULT_FAILED_RAILS_UNSTABLE" 2 "EFUSE_SELF_TEST_EFUSE_RESULT_PASSED" 1 "EFUSE_SELF_TEST_EFUSE_RESULT_RUNNING" 0 "EFUSE_SELF_TEST_EFUSE_RESULT_NOT_RUN" ;
VAL_ 753 VCFRONT_PCSEFuseVNFState 7 "EFUSE_ASIC_STATE_SELF_TEST" 6 "EFUSE_ASIC_STATE_SELF_TEST_PREP" 5 "EFUSE_ASIC_STATE_LOCKED" 4 "EFUSE_ASIC_STATE_UNLOCKED" 3 "EFUSE_ASIC_STATE_CONFIGURATION" 2 "EFUSE_ASIC_STATE_WAKEUP" 1 "EFUSE_ASIC_STATE_STANDBY" 0 "EFUSE_ASIC_STATE_UNKNOWN" ;
VAL_ 753 VCFRONT_PCSEFuseVNFSelfTestStatu 3 "EFUSE_SELF_TEST_SKIPPED" 2 "EFUSE_SELF_TEST_COMPLETE" 1 "EFUSE_SELF_TEST_ACTIVE" 0 "EFUSE_SELF_TEST_NOT_COMPLETE" ;
VAL_ 753 VCFRONT_iBoosterState 3 "EFUSE_STATE_SNA" 2 "EFUSE_STATE_LOCKED_OUT" 1 "EFUSE_STATE_ON" 0 "EFUSE_STATE_OFF" ;
VAL_ 753 VCFRONT_iBoosterSelfTestResult 12 "EFUSE_SELF_TEST_EFUSE_RESULT_SNA" 11 "EFUSE_SELF_TEST_EFUSE_RESULT_SKIPPED" 10 "EFUSE_SELF_TEST_EFUSE_RESULT_FAILED_NOT_LATCHED" 9 "EFUSE_SELF_TEST_EFUSE_RESULT_FAILED_TURN_OFF_PATH_TOO_SLOW" 8 "EFUSE_SELF_TEST_EFUSE_RESULT_FAILED_ENABLE_HIGH_MALFUNCTION" 7 "EFUSE_SELF_TEST_EFUSE_RESULT_FAILED_POWER_FET_CHANNEL_OPEN" 6 "EFUSE_SELF_TEST_EFUSE_RESULT_FAILED_ENABLE_LOW_MALFUNCTION" 5 "EFUSE_SELF_TEST_EFUSE_RESULT_FAILED_POWER_FET_STUCK_ON" 4 "EFUSE_SELF_TEST_EFUSE_RESULT_FAILED_EFUSE_OUTPUT_SHORT" 3 "EFUSE_SELF_TEST_EFUSE_RESULT_FAILED_RAILS_UNSTABLE" 2 "EFUSE_SELF_TEST_EFUSE_RESULT_PASSED" 1 "EFUSE_SELF_TEST_EFUSE_RESULT_RUNNING" 0 "EFUSE_SELF_TEST_EFUSE_RESULT_NOT_RUN" ;
VAL_ 753 VCFRONT_EPAS3PState 3 "EFUSE_STATE_SNA" 2 "EFUSE_STATE_LOCKED_OUT" 1 "EFUSE_STATE_ON" 0 "EFUSE_STATE_OFF" ;
VAL_ 753 VCFRONT_EPAS3PSelfTestResult 12 "EFUSE_SELF_TEST_EFUSE_RESULT_SNA" 11 "EFUSE_SELF_TEST_EFUSE_RESULT_SKIPPED" 10 "EFUSE_SELF_TEST_EFUSE_RESULT_FAILED_NOT_LATCHED" 9 "EFUSE_SELF_TEST_EFUSE_RESULT_FAILED_TURN_OFF_PATH_TOO_SLOW" 8 "EFUSE_SELF_TEST_EFUSE_RESULT_FAILED_ENABLE_HIGH_MALFUNCTION" 7 "EFUSE_SELF_TEST_EFUSE_RESULT_FAILED_POWER_FET_CHANNEL_OPEN" 6 "EFUSE_SELF_TEST_EFUSE_RESULT_FAILED_ENABLE_LOW_MALFUNCTION" 5 "EFUSE_SELF_TEST_EFUSE_RESULT_FAILED_POWER_FET_STUCK_ON" 4 "EFUSE_SELF_TEST_EFUSE_RESULT_FAILED_EFUSE_OUTPUT_SHORT" 3 "EFUSE_SELF_TEST_EFUSE_RESULT_FAILED_RAILS_UNSTABLE" 2 "EFUSE_SELF_TEST_EFUSE_RESULT_PASSED" 1 "EFUSE_SELF_TEST_EFUSE_RESULT_RUNNING" 0 "EFUSE_SELF_TEST_EFUSE_RESULT_NOT_RUN" ;
VAL_ 753 VCFRONT_EPAS3PEFuseVNFState 7 "EFUSE_ASIC_STATE_SELF_TEST" 6 "EFUSE_ASIC_STATE_SELF_TEST_PREP" 5 "EFUSE_ASIC_STATE_LOCKED" 4 "EFUSE_ASIC_STATE_UNLOCKED" 3 "EFUSE_ASIC_STATE_CONFIGURATION" 2 "EFUSE_ASIC_STATE_WAKEUP" 1 "EFUSE_ASIC_STATE_STANDBY" 0 "EFUSE_ASIC_STATE_UNKNOWN" ;
VAL_ 753 VCFRONT_EPAS3PEFuseHardshortThre 15 "VNF1048_HSHT_160_MV" 14 "VNF1048_HSHT_139_3_MV" 13 "VNF1048_HSHT_121_3_MV" 12 "VNF1048_HSHT_105_6_MV" 11 "VNF1048_HSHT_91_9_MV" 10 "VNF1048_HSHT_80_MV" 9 "VNF1048_HSHT_69_6_MV" 8 "VNF1048_HSHT_60_6_MV" 7 "VNF1048_HSHT_52_8_MV" 6 "VNF1048_HSHT_45_9_MV" 5 "VNF1048_HSHT_40_MV" 4 "VNF1048_HSHT_34_8_MV" 3 "VNF1048_HSHT_30_3_MV" 2 "VNF1048_HSHT_26_4_MV" 1 "VNF1048_HSHT_23_MV" 0 "VNF1048_HSHT_20_MV" ;
VAL_ 753 VCFRONT_EPAS3PEFuseVNFSelfTestSt 3 "EFUSE_SELF_TEST_SKIPPED" 2 "EFUSE_SELF_TEST_COMPLETE" 1 "EFUSE_SELF_TEST_ACTIVE" 0 "EFUSE_SELF_TEST_NOT_COMPLETE" ;
VAL_ 753 VCFRONT_EPAS3SState 3 "EFUSE_STATE_SNA" 2 "EFUSE_STATE_LOCKED_OUT" 1 "EFUSE_STATE_ON" 0 "EFUSE_STATE_OFF" ;
VAL_ 753 VCFRONT_EPAS3SSelfTestResult 12 "EFUSE_SELF_TEST_EFUSE_RESULT_SNA" 11 "EFUSE_SELF_TEST_EFUSE_RESULT_SKIPPED" 10 "EFUSE_SELF_TEST_EFUSE_RESULT_FAILED_NOT_LATCHED" 9 "EFUSE_SELF_TEST_EFUSE_RESULT_FAILED_TURN_OFF_PATH_TOO_SLOW" 8 "EFUSE_SELF_TEST_EFUSE_RESULT_FAILED_ENABLE_HIGH_MALFUNCTION" 7 "EFUSE_SELF_TEST_EFUSE_RESULT_FAILED_POWER_FET_CHANNEL_OPEN" 6 "EFUSE_SELF_TEST_EFUSE_RESULT_FAILED_ENABLE_LOW_MALFUNCTION" 5 "EFUSE_SELF_TEST_EFUSE_RESULT_FAILED_POWER_FET_STUCK_ON" 4 "EFUSE_SELF_TEST_EFUSE_RESULT_FAILED_EFUSE_OUTPUT_SHORT" 3 "EFUSE_SELF_TEST_EFUSE_RESULT_FAILED_RAILS_UNSTABLE" 2 "EFUSE_SELF_TEST_EFUSE_RESULT_PASSED" 1 "EFUSE_SELF_TEST_EFUSE_RESULT_RUNNING" 0 "EFUSE_SELF_TEST_EFUSE_RESULT_NOT_RUN" ;
VAL_ 753 VCFRONT_EPAS3SEFuseVNFState 7 "EFUSE_ASIC_STATE_SELF_TEST" 6 "EFUSE_ASIC_STATE_SELF_TEST_PREP" 5 "EFUSE_ASIC_STATE_LOCKED" 4 "EFUSE_ASIC_STATE_UNLOCKED" 3 "EFUSE_ASIC_STATE_CONFIGURATION" 2 "EFUSE_ASIC_STATE_WAKEUP" 1 "EFUSE_ASIC_STATE_STANDBY" 0 "EFUSE_ASIC_STATE_UNKNOWN" ;
VAL_ 753 VCFRONT_EPAS3SEFuseVNFSelfTestSt 3 "EFUSE_SELF_TEST_SKIPPED" 2 "EFUSE_SELF_TEST_COMPLETE" 1 "EFUSE_SELF_TEST_ACTIVE" 0 "EFUSE_SELF_TEST_NOT_COMPLETE" ;
VAL_ 753 VCFRONT_ESPMotorState 3 "EFUSE_STATE_SNA" 2 "EFUSE_STATE_LOCKED_OUT" 1 "EFUSE_STATE_ON" 0 "EFUSE_STATE_OFF" ;
VAL_ 753 VCFRONT_ESPMotorSelfTestResult 12 "EFUSE_SELF_TEST_EFUSE_RESULT_SNA" 11 "EFUSE_SELF_TEST_EFUSE_RESULT_SKIPPED" 10 "EFUSE_SELF_TEST_EFUSE_RESULT_FAILED_NOT_LATCHED" 9 "EFUSE_SELF_TEST_EFUSE_RESULT_FAILED_TURN_OFF_PATH_TOO_SLOW" 8 "EFUSE_SELF_TEST_EFUSE_RESULT_FAILED_ENABLE_HIGH_MALFUNCTION" 7 "EFUSE_SELF_TEST_EFUSE_RESULT_FAILED_POWER_FET_CHANNEL_OPEN" 6 "EFUSE_SELF_TEST_EFUSE_RESULT_FAILED_ENABLE_LOW_MALFUNCTION" 5 "EFUSE_SELF_TEST_EFUSE_RESULT_FAILED_POWER_FET_STUCK_ON" 4 "EFUSE_SELF_TEST_EFUSE_RESULT_FAILED_EFUSE_OUTPUT_SHORT" 3 "EFUSE_SELF_TEST_EFUSE_RESULT_FAILED_RAILS_UNSTABLE" 2 "EFUSE_SELF_TEST_EFUSE_RESULT_PASSED" 1 "EFUSE_SELF_TEST_EFUSE_RESULT_RUNNING" 0 "EFUSE_SELF_TEST_EFUSE_RESULT_NOT_RUN" ;
VAL_ 753 VCFRONT_ESPMotorEFuseVNFState 7 "EFUSE_ASIC_STATE_SELF_TEST" 6 "EFUSE_ASIC_STATE_SELF_TEST_PREP" 5 "EFUSE_ASIC_STATE_LOCKED" 4 "EFUSE_ASIC_STATE_UNLOCKED" 3 "EFUSE_ASIC_STATE_CONFIGURATION" 2 "EFUSE_ASIC_STATE_WAKEUP" 1 "EFUSE_ASIC_STATE_STANDBY" 0 "EFUSE_ASIC_STATE_UNKNOWN" ;
VAL_ 753 VCFRONT_ESPMotorEFuseVNFSelfTest 3 "EFUSE_SELF_TEST_SKIPPED" 2 "EFUSE_SELF_TEST_COMPLETE" 1 "EFUSE_SELF_TEST_ACTIVE" 0 "EFUSE_SELF_TEST_NOT_COMPLETE" ;
VAL_ 753 VCFRONT_ESPValveState 3 "EFUSE_STATE_SNA" 2 "EFUSE_STATE_LOCKED_OUT" 1 "EFUSE_STATE_ON" 0 "EFUSE_STATE_OFF" ;
VAL_ 753 VCFRONT_autopilot2State 3 "EFUSE_STATE_SNA" 2 "EFUSE_STATE_LOCKED_OUT" 1 "EFUSE_STATE_ON" 0 "EFUSE_STATE_OFF" ;
VAL_ 753 VCFRONT_vbatFusedSelfTestResult 12 "EFUSE_SELF_TEST_EFUSE_RESULT_SNA" 11 "EFUSE_SELF_TEST_EFUSE_RESULT_SKIPPED" 10 "EFUSE_SELF_TEST_EFUSE_RESULT_FAILED_NOT_LATCHED" 9 "EFUSE_SELF_TEST_EFUSE_RESULT_FAILED_TURN_OFF_PATH_TOO_SLOW" 8 "EFUSE_SELF_TEST_EFUSE_RESULT_FAILED_ENABLE_HIGH_MALFUNCTION" 7 "EFUSE_SELF_TEST_EFUSE_RESULT_FAILED_POWER_FET_CHANNEL_OPEN" 6 "EFUSE_SELF_TEST_EFUSE_RESULT_FAILED_ENABLE_LOW_MALFUNCTION" 5 "EFUSE_SELF_TEST_EFUSE_RESULT_FAILED_POWER_FET_STUCK_ON" 4 "EFUSE_SELF_TEST_EFUSE_RESULT_FAILED_EFUSE_OUTPUT_SHORT" 3 "EFUSE_SELF_TEST_EFUSE_RESULT_FAILED_RAILS_UNSTABLE" 2 "EFUSE_SELF_TEST_EFUSE_RESULT_PASSED" 1 "EFUSE_SELF_TEST_EFUSE_RESULT_RUNNING" 0 "EFUSE_SELF_TEST_EFUSE_RESULT_NOT_RUN" ;
VAL_ 769 VCFRONT_infoBuildType 4 "INFO_MFG_BUILD" 3 "INFO_TRACEABLE_CI_BUILD" 2 "INFO_LOCAL_BUILD" 1 "INFO_PLATFORM_BUILD" 0 "INFO_UNKNOWN_BUILD" ;
VAL_ 1014 VCFRONT_lowBeamLeftStatus 3 "LIGHT_SNA" 2 "LIGHT_FAULT" 1 "LIGHT_ON" 0 "LIGHT_OFF" ;
VAL_ 1014 VCFRONT_lowBeamRightStatus 3 "LIGHT_SNA" 2 "LIGHT_FAULT" 1 "LIGHT_ON" 0 "LIGHT_OFF" ;
VAL_ 1014 VCFRONT_highBeamLeftStatus 3 "LIGHT_SNA" 2 "LIGHT_FAULT" 1 "LIGHT_ON" 0 "LIGHT_OFF" ;
VAL_ 1014 VCFRONT_highBeamRightStatus 3 "LIGHT_SNA" 2 "LIGHT_FAULT" 1 "LIGHT_ON" 0 "LIGHT_OFF" ;
VAL_ 1014 VCFRONT_DRLLeftStatus 3 "LIGHT_SNA" 2 "LIGHT_FAULT" 1 "LIGHT_ON" 0 "LIGHT_OFF" ;
VAL_ 1014 VCFRONT_DRLRightStatus 3 "LIGHT_SNA" 2 "LIGHT_FAULT" 1 "LIGHT_ON" 0 "LIGHT_OFF" ;
VAL_ 1014 VCFRONT_fogLeftStatus 3 "LIGHT_SNA" 2 "LIGHT_FAULT" 1 "LIGHT_ON" 0 "LIGHT_OFF" ;
VAL_ 1014 VCFRONT_fogRightStatus 3 "LIGHT_SNA" 2 "LIGHT_FAULT" 1 "LIGHT_ON" 0 "LIGHT_OFF" ;
VAL_ 1014 VCFRONT_sideMarkersStatus 3 "LIGHT_SNA" 2 "LIGHT_FAULT" 1 "LIGHT_ON" 0 "LIGHT_OFF" ;
VAL_ 1014 VCFRONT_sideRepeaterLeftStatus 3 "LIGHT_SNA" 2 "LIGHT_FAULT" 1 "LIGHT_ON" 0 "LIGHT_OFF" ;
VAL_ 1014 VCFRONT_sideRepeaterRightStatus 3 "LIGHT_SNA" 2 "LIGHT_FAULT" 1 "LIGHT_ON" 0 "LIGHT_OFF" ;
VAL_ 1014 VCFRONT_turnSignalLeftStatus 3 "LIGHT_SNA" 2 "LIGHT_FAULT" 1 "LIGHT_ON" 0 "LIGHT_OFF" ;
VAL_ 1014 VCFRONT_turnSignalRightStatus 3 "LIGHT_SNA" 2 "LIGHT_FAULT" 1 "LIGHT_ON" 0 "LIGHT_OFF" ;
VAL_ 1014 VCFRONT_parkLeftStatus 3 "LIGHT_SNA" 2 "LIGHT_FAULT" 1 "LIGHT_ON" 0 "LIGHT_OFF" ;
VAL_ 1014 VCFRONT_parkRightStatus 3 "LIGHT_SNA" 2 "LIGHT_FAULT" 1 "LIGHT_ON" 0 "LIGHT_OFF" ;
VAL_ 1014 VC_rightHeadlampHealth 7 "SMART_LIGHT_HEALTH_RESERVED" 6 "SMART_LIGHT_HEALTH_UPDATING" 5 "SMART_LIGHT_HEALTH_NOT_CONFIGURED" 4 "SMART_LIGHT_HEALTH_COMMS_OK_NO_LIGHT" 3 "SMART_LIGHT_HEALTH_OK" 2 "SMART_LIGHT_HEALTH_TIMEOUT" 1 "SMART_LIGHT_HEALTH_WAIT" 0 "SMART_LIGHT_HEALTH_OFF" ;
VAL_ 1014 VC_leftHeadlampHealth 7 "SMART_LIGHT_HEALTH_RESERVED" 6 "SMART_LIGHT_HEALTH_UPDATING" 5 "SMART_LIGHT_HEALTH_NOT_CONFIGURED" 4 "SMART_LIGHT_HEALTH_COMMS_OK_NO_LIGHT" 3 "SMART_LIGHT_HEALTH_OK" 2 "SMART_LIGHT_HEALTH_TIMEOUT" 1 "SMART_LIGHT_HEALTH_WAIT" 0 "SMART_LIGHT_HEALTH_OFF" ;
VAL_ 1014 VCFRONT_advancedDrivingBeamStatu 3 "ACTIVE_NO_COLUMNS_EXTINGUISHED" 2 "ACTIVE_SOME_COLUMNS_EXTINGUISHED" 1 "ENABLED_AND_INACTIVE" 0 "NOT_SUPPORTED_OR_DISABLED" ;
VAL_ 1014 VCFRONT_headlampRoadClass 3 "WET" 2 "MOTORWAY" 1 "TOWNLIGHT" 0 "NOMINAL" ;
VAL_ 1013 VCFRONT_indicatorLeftRequest 2 "TURN_SIGNAL_ACTIVE_HIGH" 1 "TURN_SIGNAL_ACTIVE_LOW" 0 "TURN_SIGNAL_OFF" ;
VAL_ 1013 VCFRONT_indicatorRightRequest 2 "TURN_SIGNAL_ACTIVE_HIGH" 1 "TURN_SIGNAL_ACTIVE_LOW" 0 "TURN_SIGNAL_OFF" ;
VAL_ 1013 VCFRONT_hazardLightRequest 8 "HAZARD_REQUEST_UDS" 7 "HAZARD_REQUEST_DAS" 6 "HAZARD_REQUEST_CAR_ALARM" 5 "HAZARD_REQUEST_CRASH" 4 "HAZARD_REQUEST_MISLOCK" 3 "HAZARD_REQUEST_UNLOCK" 2 "HAZARD_REQUEST_LOCK" 1 "HAZARD_REQUEST_BUTTON" 0 "HAZARD_REQUEST_NONE" ;
VAL_ 1013 VCFRONT_highBeamControlState 3 "HIGH_BEAM_CONTROL_DAS_AUTO" 2 "HIGH_BEAM_CONTROL_LATCHED" 1 "HIGH_BEAM_CONTROL_INTERMITTENT" 0 "HIGH_BEAM_CONTROL_IDLE" ;
VAL_ 1013 VCFRONT_dynamicBrakeLightState 2 "DYNAMIC_BRAKE_LIGHT_ACTIVE_HIGH" 1 "DYNAMIC_BRAKE_LIGHT_ACTIVE_LOW" 0 "DYNAMIC_BRAKE_LIGHT_OFF" ;
VAL_ 1013 VCFRONT_lightingCoreState 15 "LIGHT_CORE_STATE_SNA" 5 "LIGHT_CORE_STATE_CUSTOM" 4 "LIGHT_CORE_STATE_LOW_BEAMS" 3 "LIGHT_CORE_STATE_DRL_PLUS_REAR_POS_PARK" 2 "LIGHT_CORE_STATE_DRL" 1 "LIGHT_CORE_STATE_POS_PARK" 0 "LIGHT_CORE_STATE_OFF" ;
VAL_ 1013 VCFRONT_turnIndicatorStalk 3 "SIMULATED_LATCHING_STALK_SNA" 2 "SIMULATED_LATCHING_STALK_RIGHT" 1 "SIMULATED_LATCHING_STALK_LEFT" 0 "SIMULATED_LATCHING_STALK_IDLE" ;
VAL_ 1013 VCFRONT_highBeamLatchingState 3 "LATCHING_STATE_LATCHED" 2 "LATCHING_STATE_LATCHING" 1 "LATCHING_STATE_UNLATCHED" 0 "LATCHING_STATE_SNA" ;
VAL_ 1013 VCFRONT_lightingCustomState 31 "CUSTOM_LIGHTING_STATE_RESERVED" 14 "CUSTOM_LIGHTING_STATE_ROBOTAXI_WELCOME_RAMP_DOWN" 13 "CUSTOM_LIGHTING_STATE_ROBOTAXI_WELCOME_RAMP_UP" 12 "CUSTOM_LIGHTING_STATE_WELCOME_GOODBYE_SYHL" 11 "CUSTOM_LIGHTING_STATE_WELCOME_GOODBYE_NIGHT" 10 "CUSTOM_LIGHTING_STATE_WELCOME_GOODBYE_DAY" 9 "CUSTOM_LIGHTING_STATE_WELCOME_GOODBYE_UNLOCK" 8 "CUSTOM_LIGHTING_STATE_WELCOME_GOODBYE_LOCK" 7 "CUSTOM_LIGHTING_STATE_SELFTEST" 6 "CUSTOM_LIGHTING_STATE_HAZARD_WARNING_LIGHTS_OFF" 5 "CUSTOM_LIGHTING_STATE_HAZARD_WARNING_LIGHTS_ON" 4 "CUSTOM_LIGHTING_STATE_HAZARD_WARNING_WAIT_FOR_HEADLAMP_POWER" 3 "CUSTOM_LIGHTING_STATE_SENTRY_AWARE_OFF" 2 "CUSTOM_LIGHTING_STATE_SENTRY_AWARE_RAMP_DOWN" 1 "CUSTOM_LIGHTING_STATE_SENTRY_AWARE_RAMP_UP" 0 "CUSTOM_LIGHTING_STATE_NONE" ;
VAL_ 1013 VCFRONT_indicatorLeftInternal 2 "TURN_SIGNAL_ACTIVE_HIGH" 1 "TURN_SIGNAL_ACTIVE_LOW" 0 "TURN_SIGNAL_OFF" ;
VAL_ 1013 VCFRONT_indicatorRightInternal 2 "TURN_SIGNAL_ACTIVE_HIGH" 1 "TURN_SIGNAL_ACTIVE_LOW" 0 "TURN_SIGNAL_OFF" ;
VAL_ 1801 VC_hcmlFactoryOfOrigin 3 "HELLA_MEXICO" 2 "HELLA_SLOVAKIA" 1 "HELLA_CHINA" 0 "UNKNOWN" ;
VAL_ 1801 VC_hcmlHellaPartNumberStatus 1 "FAULT" 0 "OK" ;
VAL_ 1801 VC_hcmlCurrentBinMappingType 2 "BIN_MAP_TYPE_2" 1 "BIN_MAP_TYPE_1" 0 "BIN_MAP_TYPE_UNKNOWN" ;
VAL_ 1801 VC_hcmlCurrentBin0Value 7 "INVALID_LIGHTCLASS" 4 "LIGHTCLASS_4" 3 "LIGHTCLASS_3" 2 "LIGHTCLASS_2" 1 "LIGHTCLASS_1" 0 "LIGHTCLASS_SNA" ;
VAL_ 1801 VC_hcmlCurrentBin1Value 7 "INVALID_LIGHTCLASS" 4 "LIGHTCLASS_4" 3 "LIGHTCLASS_3" 2 "LIGHTCLASS_2" 1 "LIGHTCLASS_1" 0 "LIGHTCLASS_SNA" ;
VAL_ 1801 VC_hcmlCurrentBin2Value 7 "INVALID_LIGHTCLASS" 4 "LIGHTCLASS_4" 3 "LIGHTCLASS_3" 2 "LIGHTCLASS_2" 1 "LIGHTCLASS_1" 0 "LIGHTCLASS_SNA" ;
VAL_ 1801 VC_hcmlCurrentBin3Value 7 "INVALID_LIGHTCLASS" 4 "LIGHTCLASS_4" 3 "LIGHTCLASS_3" 2 "LIGHTCLASS_2" 1 "LIGHTCLASS_1" 0 "LIGHTCLASS_SNA" ;
VAL_ 1801 VC_hcmlCurrentBin4Value 7 "INVALID_LIGHTCLASS" 4 "LIGHTCLASS_4" 3 "LIGHTCLASS_3" 2 "LIGHTCLASS_2" 1 "LIGHTCLASS_1" 0 "LIGHTCLASS_SNA" ;
VAL_ 1801 VC_hcmlCurrentBin5Value 7 "INVALID_LIGHTCLASS" 4 "LIGHTCLASS_4" 3 "LIGHTCLASS_3" 2 "LIGHTCLASS_2" 1 "LIGHTCLASS_1" 0 "LIGHTCLASS_SNA" ;
VAL_ 1801 VC_hcmlRegionAndSide 6 "HEADLAMP_REGION_AND_SIDE_ECE_RHD_RIGHT" 5 "HEADLAMP_REGION_AND_SIDE_ECE_RHD_LEFT" 4 "HEADLAMP_REGION_AND_SIDE_ECE_LHD_RIGHT" 3 "HEADLAMP_REGION_AND_SIDE_ECE_LHD_LEFT" 2 "HEADLAMP_REGION_AND_SIDE_SAE_RIGHT" 1 "HEADLAMP_REGION_AND_SIDE_SAE_LEFT" 0 "HEADLAMP_REGION_AND_SIDE_SNA" ;
VAL_ 1801 VC_hcmrFactoryOfOrigin 3 "HELLA_MEXICO" 2 "HELLA_SLOVAKIA" 1 "HELLA_CHINA" 0 "UNKNOWN" ;
VAL_ 1801 VC_hcmrHellaPartNumberStatus 1 "FAULT" 0 "OK" ;
VAL_ 1801 VC_hcmrCurrentBinMappingType 2 "BIN_MAP_TYPE_2" 1 "BIN_MAP_TYPE_1" 0 "BIN_MAP_TYPE_UNKNOWN" ;
VAL_ 1801 VC_hcmrCurrentBin0Value 7 "INVALID_LIGHTCLASS" 4 "LIGHTCLASS_4" 3 "LIGHTCLASS_3" 2 "LIGHTCLASS_2" 1 "LIGHTCLASS_1" 0 "LIGHTCLASS_SNA" ;
VAL_ 1801 VC_hcmrCurrentBin1Value 7 "INVALID_LIGHTCLASS" 4 "LIGHTCLASS_4" 3 "LIGHTCLASS_3" 2 "LIGHTCLASS_2" 1 "LIGHTCLASS_1" 0 "LIGHTCLASS_SNA" ;
VAL_ 1801 VC_hcmrCurrentBin2Value 7 "INVALID_LIGHTCLASS" 4 "LIGHTCLASS_4" 3 "LIGHTCLASS_3" 2 "LIGHTCLASS_2" 1 "LIGHTCLASS_1" 0 "LIGHTCLASS_SNA" ;
VAL_ 1801 VC_hcmrCurrentBin3Value 7 "INVALID_LIGHTCLASS" 4 "LIGHTCLASS_4" 3 "LIGHTCLASS_3" 2 "LIGHTCLASS_2" 1 "LIGHTCLASS_1" 0 "LIGHTCLASS_SNA" ;
VAL_ 1801 VC_hcmrCurrentBin4Value 7 "INVALID_LIGHTCLASS" 4 "LIGHTCLASS_4" 3 "LIGHTCLASS_3" 2 "LIGHTCLASS_2" 1 "LIGHTCLASS_1" 0 "LIGHTCLASS_SNA" ;
VAL_ 1801 VC_hcmrCurrentBin5Value 7 "INVALID_LIGHTCLASS" 4 "LIGHTCLASS_4" 3 "LIGHTCLASS_3" 2 "LIGHTCLASS_2" 1 "LIGHTCLASS_1" 0 "LIGHTCLASS_SNA" ;
VAL_ 1801 VC_hcmrRegionAndSide 6 "HEADLAMP_REGION_AND_SIDE_ECE_RHD_RIGHT" 5 "HEADLAMP_REGION_AND_SIDE_ECE_RHD_LEFT" 4 "HEADLAMP_REGION_AND_SIDE_ECE_LHD_RIGHT" 3 "HEADLAMP_REGION_AND_SIDE_ECE_LHD_LEFT" 2 "HEADLAMP_REGION_AND_SIDE_SAE_RIGHT" 1 "HEADLAMP_REGION_AND_SIDE_SAE_LEFT" 0 "HEADLAMP_REGION_AND_SIDE_SNA" ;
VAL_ 897 VCFRONT_modeTransitionID 54 "SER_14_apInletOvertemp" 53 "ENTER_AMBIENTSOURCE_DRIVERLESS_SELF_TEST" 52 "SER_13_driverlessSelfTestActive" 51 "ENTER_SERIES_COP1" 50 "PAR_13_charge_battNeedsActiveCooling" 49 "SER_12_charge_battNeedsCooling" 48 "PAR_12_drive_cabinOverheatProtectActive" 47 "PAR_11_batteryDischarge" 46 "SER_11_service_highCoolantFlowReq" 45 "PAR_10_charge_battNearPassiveTarget" 44 "PAR_9_FC_battAboveHotStagnationTemp" 43 "PAR_8_FC_battNeedsActiveCooling_evapEnabled" 42 "PAR_7_FC_battNeedsActiveCooling_evapDisabled" 41 "PAR_6_drive_battAboveHotStagnationTemp" 40 "PAR_5_drive_cannotPassivelyCoolBatt" 39 "PAR_4_drive_chillerPassivelyCoolsBatt" 38 "PAR_3_drive_ptNeedsActiveCooling" 37 "PAR_2_drive_battNeedsActiveCooling_evapDisabled" 36 "PAR_1_drive_battNeedsActiveCooling_evapEnabled" 35 "SER_10_charge_battBelowPassiveTarget" 34 "SER_9_FC_battNeedsActiveCooling_evapEnabled" 33 "SER_8_FC_battNeedsActiveCooling_evapDisabled" 32 "SER_7_FC_battHeatingNeeded" 31 "SER_6_drive_battBelowPassiveOrNeedsHeat" 30 "SER_5_drive_radPassivelyCoolsBatt" 29 "SER_4_drive_chillerPassivelyCools" 28 "SER_3_drive_battBelowHotStagnationTemp" 27 "SER_2_drive_battNeedsActiveCooling_evapDisabled" 26 "SER_1_drive_battNeedsActiveCooling_evapEnabled" 25 "EXIT_AMBIENTSOURCE" 24 "ENTER_AMBIENTSOURCE" 23 "UNDEFINED" 22 "OVERRIDE" 21 "INIT" 20 "PARALLEL_10_batteryDischarge" 19 "PARALLEL_9_drive_batteryThermalLimiting" 18 "SERIES_9_drive_driveUnitThermalLimiting" 17 "SERIES_8_preConditioning_batteryNeedsHeat" 16 "PARALLEL_8_fastCharge_batteryWantsHeat" 15 "PARALLEL_7_fastCharge_batteryWantsCool" 14 "SERIES_7_fastCharge_batteryWantsCool" 13 "SERIES_6_fastCharge_batteryNeedsHeat" 12 "PARALLEL_6_charge_batteryWantsCool" 11 "PARALLEL_5_charge_batteryWantsHeat" 10 "SERIES_5_charge_batteryWantsHeat" 9 "SERIES_4_charge_batteryNeedsHeat" 8 "PARALLEL_4_drive_batteryNeedsCool" 7 "PARALLEL_3_drive_batteryWantsCool" 6 "PARALLEL_2_drive_batteryWantsHeat" 5 "SERIES_3_drive_batteryWantsHeat" 4 "SERIES_2_drive_batteryNeedsHeat" 3 "SERIES_1_drive_batteryWantsCool" 2 "SERIES_F3_faultTempSensors" 1 "SERIES_F2_faultPumps" 0 "PARALLEL_F1_noFlowRequest" ;
VAL_ 897 VCFRONT_modeDesired 3 "AMBIENT_SOURCE" 2 "BLEND" 1 "PARALLEL" 0 "SERIES" ;
VAL_ 897 VCFRONT_radiatorFanRunReason 13 "FACTORY_NO_COOLANT" 12 "DRIVERLESS_SELF_TEST" 11 "BATTERY_DISCHARGE" 10 "DI_BURN_IN" 9 "RAD_CLEAR" 8 "UDS" 7 "MIN_ON_NVH" 6 "MIN_ON_GLOBAL" 5 "COAST_MODE" 4 "HEAT_PUMP" 3 "NVH_MASKING" 2 "AMBIENT_SNIFF" 1 "ACTIVE_MANAGER" 0 "NONE" ;
VAL_ 897 VCFRONT_coolantTempBasedMode 3 "AMBIENT_SOURCE" 2 "BLEND" 1 "PARALLEL" 0 "SERIES" ;
VAL_ 897 VCFRONT_coolantValveRecalReason 6 "NVRAM_LOSS" 5 "MOTOR_FEEDBACK_INTERRUPTED" 4 "SELF_TEST" 3 "CALIBRATION_FAULT_NO_TRAVEL" 2 "GENERAL_FAULT" 1 "MAX_TRAVEL" 0 "UNDEFINED" ;
VAL_ 897 VCFRONT_hpChargeCableType 2 "AC_CHARGER_PRESENT" 1 "DC_CHARGER_PRESENT" 0 "NO_CHARGER_PRESENT" ;
VAL_ 897 VCFRONT_refCommissionStatus 2 "REFRIGERANT_COMMISSIONED" 1 "REFRIGERANT_UNCOMMISSIONED" 0 "REFRIGERANT_UNKNOWN" ;
VAL_ 897 VCFRONT_passiveCoolingState 3 "CannotCoolBattery" 2 "ChillerAndRadCoolSeriesLoop" 1 "ChillerCoolsParallelBattLoop" 0 "ChillerCoolsSeriesLoop" ;
VAL_ 897 VCFRONT_hpRefrigerantPurgeState 2 "COMPLETE" 1 "EVAP_PURGE" 0 "IDLE" ;
VAL_ 897 VCFRONT_chillerEXVControlState 5 "PARKED" 4 "CALIBRATING_TIMEOUT" 3 "CALIBRATING" 2 "DISCHARGE" 1 "ACTIVE" 0 "INIT" ;
VAL_ 897 VCFRONT_evapEXVControlState 5 "PARKED" 4 "CALIBRATING_TIMEOUT" 3 "CALIBRATING" 2 "DISCHARGE" 1 "ACTIVE" 0 "INIT" ;
VAL_ 897 VCFRONT_recircEXVControlState 5 "PARKED" 4 "CALIBRATING_TIMEOUT" 3 "CALIBRATING" 2 "DISCHARGE" 1 "ACTIVE" 0 "INIT" ;
VAL_ 897 VCFRONT_lccEXVControlState 5 "PARKED" 4 "CALIBRATING_TIMEOUT" 3 "CALIBRATING" 2 "DISCHARGE" 1 "ACTIVE" 0 "INIT" ;
VAL_ 897 VCFRONT_cclEXVControlState 5 "PARKED" 4 "CALIBRATING_TIMEOUT" 3 "CALIBRATING" 2 "DISCHARGE" 1 "ACTIVE" 0 "INIT" ;
VAL_ 897 VCFRONT_ccrEXVControlState 5 "PARKED" 4 "CALIBRATING_TIMEOUT" 3 "CALIBRATING" 2 "DISCHARGE" 1 "ACTIVE" 0 "INIT" ;
VAL_ 897 VCFRONT_radBypassMoveReason 11 "DRIVERLESS_SELF_TEST" 10 "HEATPUMP" 9 "UDS" 8 "EXIT_SERIES" 7 "ACTIVE_BATT_UNBYPASS" 6 "ACTIVE_PT_UNBYPASS" 5 "RAD_HEAT_UNBYPASS" 4 "RAD_HEAT_BYPASS" 3 "PASSIVE_BYPASS" 2 "PASSIVE_UNBYPASS" 1 "INIT_BYPASS" 0 "INIT_UNBYPASS" ;
VAL_ 897 VCFRONT_louverPosReason 11 "DRIVERLESS_SELF_TEST" 10 "BATTERY_DISCHARGE" 9 "HIGH_SPEED" 8 "UDS" 7 "COAST_MODE" 6 "FAN_FAULT" 5 "FAN_RUN" 4 "BOUNDS_CHECK" 3 "SNIFFING" 2 "PASSIVE_MANAGER" 1 "CONDENSOR_MANAGER" 0 "NONE" ;
VAL_ 897 VCFRONT_chargeShuttleType 3 "CHARGE_SHUTTLE_COP1" 2 "CHARGE_SHUTTLE_LCCR" 1 "CHARGE_SHUTTLE_STANDARD" 0 "CHARGE_SHUTTLE_NONE" ;
VAL_ 897 VCFRONT_batteryDischArbState 5 "FAULTED" 4 "INHIBIT_FOR_REST" 3 "BATTERY_DISCHARGE" 2 "BATTERY_HEATING" 1 "READY" 0 "NOT_READY" ;
VAL_ 897 VCFRONT_ambientTempState 3 "SNIFFING" 2 "LATCHED" 1 "MEASUREING" 0 "INIT" ;
VAL_ 897 VCFRONT_ambientTempUnlatchReason 6 "SNIFF_STARTDRIVE" 5 "SNIFF_BLOCKED" 4 "SNIFF_TIMEBASED" 3 "LOUVERS_CLOSED" 2 "FAN_AIRFLOW" 1 "VEHICLE_SPEED" 0 "NONE" ;
VAL_ 513 VCFRONT_compressorState 3 "FAULT" 2 "RUNNING" 1 "READY" 0 "STANDBY" ;
VAL_ 513 VCFRONT_exvState 10 "INIT_CLOSE_OVERDRIVE" 9 "CALIB_CLOSE_OVERDRIVE" 8 "CALIB_CLOSE" 7 "READY_SHUT" 6 "OVERDRIVING_SHUT" 5 "WAIT" 4 "FAULTED" 3 "READY" 2 "INIT_CLOSE" 1 "INIT_OPEN" 0 "UNINIT" ;
VAL_ 513 VCFRONT_solenoidEvapState 3 "SOLENOID_FAULTED" 2 "SOLENOID_CLOSED" 1 "SOLENOID_OPENED" 0 "SOLENOID_UNDEFINED" ;
VAL_ 513 VCFRONT_coolantValveMode 3 "AMBIENT_SOURCE" 2 "BLEND" 1 "PARALLEL" 0 "SERIES" ;
VAL_ 513 VCFRONT_compFaultSeverity 3 "HIGH" 2 "MEDIUM" 1 "LOW" 0 "NONE" ;
VAL_ 513 VCFRONT_hpHighSideHX 3 "hpHighSideHX_BOTH" 2 "hpHighSideHX_CC" 1 "hpHighSideHX_LCC" 0 "hpHighSideHX_NONE" ;
VAL_ 513 VCFRONT_hpLowSideHX 3 "hpLowSideHX_BOTH" 2 "hpLowSideHX_EVAP" 1 "hpLowSideHX_CHILLER" 0 "hpLowSideHX_NONE" ;
VAL_ 513 VCFRONT_hpDominantLoad 6 "hpDominantLoad_HIGH_BOTH" 5 "hpDominantLoad_CC" 4 "hpDominantLoad_LCC" 3 "hpDominantLoad_LOW_BOTH" 2 "hpDominantLoad_CHILLER" 1 "hpDominantLoad_EVAP" 0 "hpDominantLoad_NONE" ;
VAL_ 513 VCFRONT_hpBlendType 2 "HP_FULL" 1 "HP_PARTIAL" 0 "HP_NONE" ;
VAL_ 513 VCFRONT_hpCabinLoadType 3 "hpCabinLoadType_EVAP" 2 "hpCabinLoadType_REHEAT" 1 "hpCabinLoadType_CC" 0 "hpCabinLoadType_NONE" ;
VAL_ 513 VCFRONT_hpBatteryLoadType 2 "BATT_COOL" 1 "BATT_HEAT" 0 "NONE" ;
VAL_ 513 VCFRONT_hpReqCoolantMode 4 "AMBIENT_SOURCE" 3 "PARALLEL" 2 "SERIES_BYPASS" 1 "SERIES_NO_BYPASS" 0 "ANY" ;
VAL_ 513 VCFRONT_compLiqPumpOutState 5 "COMP_LIQ_PUMP_OUT_ABORTED" 4 "COMP_LIQ_PUMP_OUT_COMPLETED" 3 "COMP_LIQ_PUMP_OUT_RUNNING" 2 "COMP_LIQ_PUMP_OUT_ALLOWED" 1 "COMP_LIQ_PUMP_OUT_WAITING" 0 "COMP_LIQ_PUMP_OUT_NOT_ALLOWED" ;
VAL_ 513 VCFRONT_frunkStateDBG 12 "FRUNK_STATE_FAULT_RELEASED" 11 "FRUNK_STATE_RESETTING" 10 "FRUNK_STATE_RELEASING_EXTENDING_2" 9 "FRUNK_STATE_RELEASING_RETRACTING_2" 8 "FRUNK_STATE_RELEASING_EXTENDING_1" 7 "FRUNK_STATE_RELEASING_RETRACTING_1" 6 "FRUNK_STATE_FAULT_CLOSED" 5 "FRUNK_STATE_FAULT_OPENED" 4 "FRUNK_STATE_FAULT" 3 "FRUNK_STATE_AJAR" 2 "FRUNK_STATE_OPENED" 1 "FRUNK_STATE_CLOSED" 0 "FRUNK_STATE_INIT" ;
VAL_ 513 VCFRONT_frunkSwitchGroupState 3 "FRUNKSWITCH_GROUP_CLOSED" 2 "FRUNKSWITCH_GROUP_OPENED" 1 "FRUNKSWITCH_GROUP_MISMATCHED" 0 "FRUNKSWITCH_GROUP_UNKNOWN" ;
VAL_ 513 VCFRONT_chillerExvState 10 "INIT_CLOSE_OVERDRIVE" 9 "CALIB_CLOSE_OVERDRIVE" 8 "CALIB_CLOSE" 7 "READY_SHUT" 6 "OVERDRIVING_SHUT" 5 "WAIT" 4 "FAULTED" 3 "READY" 2 "INIT_CLOSE" 1 "INIT_OPEN" 0 "UNINIT" ;
VAL_ 513 VCFRONT_evapExvState 10 "INIT_CLOSE_OVERDRIVE" 9 "CALIB_CLOSE_OVERDRIVE" 8 "CALIB_CLOSE" 7 "READY_SHUT" 6 "OVERDRIVING_SHUT" 5 "WAIT" 4 "FAULTED" 3 "READY" 2 "INIT_CLOSE" 1 "INIT_OPEN" 0 "UNINIT" ;
VAL_ 513 VCFRONT_recircExvState 10 "INIT_CLOSE_OVERDRIVE" 9 "CALIB_CLOSE_OVERDRIVE" 8 "CALIB_CLOSE" 7 "READY_SHUT" 6 "OVERDRIVING_SHUT" 5 "WAIT" 4 "FAULTED" 3 "READY" 2 "INIT_CLOSE" 1 "INIT_OPEN" 0 "UNINIT" ;
VAL_ 513 VCFRONT_lccExvState 10 "INIT_CLOSE_OVERDRIVE" 9 "CALIB_CLOSE_OVERDRIVE" 8 "CALIB_CLOSE" 7 "READY_SHUT" 6 "OVERDRIVING_SHUT" 5 "WAIT" 4 "FAULTED" 3 "READY" 2 "INIT_CLOSE" 1 "INIT_OPEN" 0 "UNINIT" ;
VAL_ 513 VCFRONT_cclExvState 10 "INIT_CLOSE_OVERDRIVE" 9 "CALIB_CLOSE_OVERDRIVE" 8 "CALIB_CLOSE" 7 "READY_SHUT" 6 "OVERDRIVING_SHUT" 5 "WAIT" 4 "FAULTED" 3 "READY" 2 "INIT_CLOSE" 1 "INIT_OPEN" 0 "UNINIT" ;
VAL_ 513 VCFRONT_ccrExvState 10 "INIT_CLOSE_OVERDRIVE" 9 "CALIB_CLOSE_OVERDRIVE" 8 "CALIB_CLOSE" 7 "READY_SHUT" 6 "OVERDRIVING_SHUT" 5 "WAIT" 4 "FAULTED" 3 "READY" 2 "INIT_CLOSE" 1 "INIT_OPEN" 0 "UNINIT" ;
VAL_ 260 VCFRONT_vehicleSM 18 "VEHICLE_STATUS_SNA" 17 "VEHICLE_STATUS_RESET" 16 "VEHICLE_STATUS_TURN_ON_RAILS" 15 "VEHICLE_STATUS_OTA" 14 "VEHICLE_STATUS_CRASH" 13 "VEHICLE_STATUS_DRIVE" 12 "VEHICLE_STATUS_CONDITIONING" 11 "VEHICLE_STATUS_ACCESSORY_PLUS" 10 "VEHICLE_STATUS_ACCESSORY" 9 "VEHICLE_STATUS_HV_UP_STANDBY" 8 "VEHICLE_STATUS_LV_AWAKE" 7 "VEHICLE_STATUS_LV_SHUTDOWN" 6 "VEHICLE_STATUS_SLEEP_STANDBY" 5 "VEHICLE_STATUS_SLEEP_SHUTDOWN" 4 "VEHICLE_STATUS_SYSTEM_CHECKS" 3 "VEHICLE_STATUS_BATTERY_POST_WAKE" 2 "VEHICLE_STATUS_SILENT_WAKE" 1 "VEHICLE_STATUS_LOW_POWER_STANDBY" 0 "VEHICLE_STATUS_INIT" ;
VAL_ 260 VCFRONT_battSM 10 "BATTERY_SM_STATE_EXTERNAL_LV_BUS_CONTROL" 9 "BATTERY_SM_STATE_RECOVERY" 8 "BATTERY_SM_STATE_FAULT" 7 "BATTERY_SM_STATE_SHORTED_CELL_TEST" 6 "BATTERY_SM_STATE_DISCONNECTED_BATTERY_TEST" 5 "BATTERY_SM_STATE_OTA_STANDBY" 4 "BATTERY_SM_STATE_RESISTANCE_ESTIMATION" 3 "BATTERY_SM_STATE_STANDBY" 2 "BATTERY_SM_STATE_DISCHARGE" 1 "BATTERY_SM_STATE_CHARGE" 0 "BATTERY_SM_STATE_INIT" ;
VAL_ 801 VCFRONT_coolantLevel 1 "FILLED" 0 "NOT_OK" ;
VAL_ 801 VCFRONT_brakeFluidLevel 2 "NORMAL" 1 "LOW" ;
VAL_ 801 VCFRONT_washerFluidLevel 2 "NORMAL" 1 "LOW" ;
VAL_ 737 VCFRONT_frunkLatchStatus 8 "LATCH_FAULT" 7 "LATCH_DEFAULT" 6 "LATCH_TIMEOUT" 5 "LATCH_AJAR" 4 "LATCH_OPENING" 3 "LATCH_CLOSING" 2 "LATCH_CLOSED" 1 "LATCH_OPENED" 0 "LATCH_SNA" ;
VAL_ 737 VCFRONT_wiperSpeed 9 "WIPER_SPEED_NARROW" 8 "WIPER_SPEED_HIGH" 7 "WIPER_SPEED_LOW" 6 "WIPER_SPEED_5" 5 "WIPER_SPEED_4" 4 "WIPER_SPEED_3" 3 "WIPER_SPEED_2" 2 "WIPER_SPEED_1" 1 "WIPER_SPEED_OFF" 0 "WIPER_SPEED_SNA" ;
VAL_ 737 VCFRONT_wiperPosition 4 "WIPER_POSITION_WIPING" 3 "WIPER_POSITION_DELAYED_REST" 2 "WIPER_POSITION_DEPRESSED_PARK" 1 "WIPER_POSITION_SERVICE" 0 "WIPER_POSITION_SNA" ;
VAL_ 737 VCFRONT_wiperState 14 "WIPER_STATE_NARROW_WASH" 13 "WIPER_STATE_NARROW_WIPE" 12 "WIPER_STATE_INT_AUTO_HIGH" 11 "WIPER_STATE_INT_AUTO_LOW" 10 "WIPER_STATE_CONT_SLOW" 9 "WIPER_STATE_CONT_FAST" 8 "WIPER_STATE_INTERMITTENT_LOW" 7 "WIPER_STATE_INTERMITTENT_HIGH" 6 "WIPER_STATE_MOMENTARY_WIPE" 5 "WIPER_STATE_WASH" 4 "WIPER_STATE_PARK" 3 "WIPER_STATE_DELAYED_REST" 2 "WIPER_STATE_FAULT" 1 "WIPER_STATE_SERVICE" 0 "WIPER_STATE_SNA" ;
VAL_ 737 VCFRONT_crashDetectedType 3 "CRASH_DETECTED_TYPE_SEVERE" 2 "CRASH_DETECTED_TYPE_MINOR_2" 1 "CRASH_DETECTED_TYPE_MINOR_1" 0 "CRASH_DETECTED_TYPE_NONE" ;
VAL_ 737 VCFRONT_crashState 3 "CRASH_STATE_SEVERE" 2 "CRASH_STATE_MINOR_2" 1 "CRASH_STATE_MINOR_1" 0 "CRASH_STATE_IDLE" ;
VAL_ 737 VCFRONT_washPumpState 3 "WASH_PUMP_BIDIRECTIONAL_STATE_SNA" 2 "WASH_PUMP_BIDIRECTIONAL_STATE_DRIVING_SECONDARY" 1 "WASH_PUMP_BIDIRECTIONAL_STATE_DRIVING_PRIMARY" 0 "WASH_PUMP_BIDIRECTIONAL_STATE_OFF" ;
VAL_ 737 VCFRONT_turnIndicatorControlType 2 "TURN_INDICATOR_CONTROL_TYPE_SWS_BUTTON" 1 "TURN_INDICATOR_CONTROL_TYPE_SINGLE_DETENT_STALK" 0 "TURN_INDICATOR_CONTROL_TYPE_UNKNOWN" ;
VAL_ 737 VCFRONT_wiperHealth 7 "WIPER_HEALTH_RESERVED" 5 "WIPER_HEALTH_FAULT" 4 "WIPER_HEALTH_UPDATING" 3 "WIPER_HEALTH_TIMEOUT" 2 "WIPER_HEALTH_OK" 1 "WIPER_HEALTH_WAIT" 0 "WIPER_HEALTH_OFF" ;
VAL_ 737 VCFRONT_radarHeaterState 4 "HEATER_STATE_FAULT" 3 "HEATER_STATE_OFF_UNAVAILABLE" 2 "HEATER_STATE_OFF" 1 "HEATER_STATE_ON" 0 "HEATER_STATE_SNA" ;
VAL_ 737 VCFRONT_passengerBuckleStatus 1 "BUCKLED" 0 "UNBUCKLED" ;
VAL_ 737 VCFRONT_frunkLatchType 2 "FRUNK_LATCH_TYPE_DOUBLE_PULL" 1 "FRUNK_LATCH_TYPE_DOUBLE_ACTUATOR" 0 "FRUNK_LATCH_TYPE_UNKNOWN" ;
VAL_ 737 VCFRONT_iBoosterStateDBG 4 "IBOOSTER_FORCE_OFF" 3 "IBOOSTER_WRITING_DATA_SHUTDOWN" 2 "IBOOSTER_GOING_DOWN" 1 "IBOOSTER_ON" 0 "IBOOSTER_OFF" ;
VAL_ 737 VCFRONT_vehicleStatusDBG 18 "VEHICLE_STATUS_SNA" 17 "VEHICLE_STATUS_RESET" 16 "VEHICLE_STATUS_TURN_ON_RAILS" 15 "VEHICLE_STATUS_OTA" 14 "VEHICLE_STATUS_CRASH" 13 "VEHICLE_STATUS_DRIVE" 12 "VEHICLE_STATUS_CONDITIONING" 11 "VEHICLE_STATUS_ACCESSORY_PLUS" 10 "VEHICLE_STATUS_ACCESSORY" 9 "VEHICLE_STATUS_HV_UP_STANDBY" 8 "VEHICLE_STATUS_LV_AWAKE" 7 "VEHICLE_STATUS_LV_SHUTDOWN" 6 "VEHICLE_STATUS_SLEEP_STANDBY" 5 "VEHICLE_STATUS_SLEEP_SHUTDOWN" 4 "VEHICLE_STATUS_SYSTEM_CHECKS" 3 "VEHICLE_STATUS_BATTERY_POST_WAKE" 2 "VEHICLE_STATUS_SILENT_WAKE" 1 "VEHICLE_STATUS_LOW_POWER_STANDBY" 0 "VEHICLE_STATUS_INIT" ;
VAL_ 737 VCFRONT_hibernationState 5 "VC_HIBERNATION_STATE_PREP" 4 "VC_HIBERNATION_STATE_EXIT" 3 "VC_HIBERNATION_STATE_RECOVERY" 2 "VC_HIBERNATION_STATE_ACTIVE" 1 "VC_HIBERNATION_STATE_NOT_ACTIVE" 0 "VC_HIBERNATION_STATE_INIT" ;
VAL_ 737 VCFRONT_wiperECUType 3 "WIPER_ECU_TYPE_VALEO" 2 "WIPER_ECU_TYPE_SHB" 1 "WIPER_ECU_TYPE_BOSCH" 0 "WIPER_ECU_TYPE_UNKNOWN" ;
VAL_ 737 VCFRONT_wiperHeaterState 4 "HEATER_STATE_FAULT" 3 "HEATER_STATE_OFF_UNAVAILABLE" 2 "HEATER_STATE_OFF" 1 "HEATER_STATE_ON" 0 "HEATER_STATE_SNA" ;
VAL_ 737 VCFRONT_closureEasterEggState 5 "CLOSURE_EASTEREGG_STATE_SHOW_CLEANUP" 4 "CLOSURE_EASTEREGG_STATE_PLAY" 3 "CLOSURE_EASTEREGG_STATE_WAITING_FOR_SYNC_PULSE" 2 "CLOSURE_EASTEREGG_STATE_WAITING_FOR_PLAY" 1 "CLOSURE_EASTEREGG_STATE_WAITING_FOR_START_CONDITIONS" 0 "CLOSURE_EASTEREGG_STATE_IDLE" ;
VAL_ 737 VCFRONT_homelinkCommStatus 3 "HOMELINK_COMM_STATUS_FAULT" 2 "HOMELINK_COMM_STATUS_ON" 1 "HOMELINK_COMM_STATUS_OFF" 0 "HOMELINK_COMM_STATUS_SNA" ;
VAL_ 737 VCFRONT_hvacPerfTestCommand 5 "PRECONDITION" 4 "STOP" 3 "BLOW_BILEVEL" 2 "BLOW" 1 "INIT" 0 "NOT_STARTED" ;
VAL_ 737 VCFRONT_coolantFillRoutineStatus 3 "FAULTED" 2 "READY_TO_FILL" 1 "MOVING_TO_FILL_POSITION" 0 "NOT_READY" ;
VAL_ 737 VCFRONT_refrigFillRoutineStatus 3 "FAULTED" 2 "READY_TO_FILL" 1 "MOVING_TO_FILL_POSITION" 0 "NOT_READY" ;
VAL_ 737 VCFRONT_closeValvesRoutineStatus 3 "FAULTED" 2 "READY_TO_FILL" 1 "MOVING_TO_FILL_POSITION" 0 "NOT_READY" ;
VAL_ 737 VCFRONT_activeLouverState 17 "AUTO_DETECT_MEASURE_3" 16 "AUTO_DETECT_WAIT_3" 15 "AUTO_DETECT_PAUSE_3" 14 "AUTO_DETECT_MEASURE_2" 13 "AUTO_DETECT_WAIT_2" 12 "AUTO_DETECT_PAUSE_2" 11 "AUTO_DETECT_MEASURE_1" 10 "AUTO_DETECT_WAIT_1" 9 "AUTO_DETECT_PAUSE_1" 8 "AUTO_DETECT_BACKOFF" 7 "FAILSAFE_LOCKED" 6 "FAILSAFE_OPEN" 5 "FAULTED" 4 "READY" 3 "CALIB_OPEN" 2 "CALIB_CLOSE" 1 "UNCALIBRATED" 0 "NOT_READY" ;
VAL_ 1349 VCFRONT_loadShedReason 256 "VCFRONT_LOAD_SHED_REASON_LV_HEALTH" 128 "VCFRONT_LOAD_SHED_REASON_PRECHARGE" 64 "VCFRONT_LOAD_SHED_REASON_CUSTOM" 32 "VCFRONT_LOAD_SHED_REASON_FACTORY" 16 "VCFRONT_LOAD_SHED_REASON_HV_FAULT" 8 "VCFRONT_LOAD_SHED_REASON_POST_CRASH" 4 "VCFRONT_LOAD_SHED_REASON_VCRIGHT_EFUSE_PROTECTION" 2 "VCFRONT_LOAD_SHED_REASON_VCLEFT_EFUSE_PROTECTION" 1 "VCFRONT_LOAD_SHED_REASON_DCDC_SATURATION" 0 "VCFRONT_LOAD_SHED_REASON_NONE" ;
VAL_ 1349 VCFRONT_vehicleLoadShedStage 3 "VEHICLE_LOADSHEDDING_STAGE_3" 2 "VEHICLE_LOADSHEDDING_STAGE_2" 1 "VEHICLE_LOADSHEDDING_STAGE_1" 0 "VEHICLE_LOADSHEDDING_STAGE_IDLE_OR_UNDEFINED" ;
VAL_ 1349 VCFRONT_HVFaultLoadShedStateDBG 3 "HV_FAULT_LOADSHED_SM_STATE_ACTIVE" 2 "HV_FAULT_LOADSHED_SM_STATE_BLOCKED" 1 "HV_FAULT_LOADSHED_SM_STATE_IDLE" 0 "HV_FAULT_LOADSHED_SM_STATE_INIT" ;
VAL_ 929 VCFRONT_APGlassHeaterState 4 "HEATER_STATE_FAULT" 3 "HEATER_STATE_OFF_UNAVAILABLE" 2 "HEATER_STATE_OFF" 1 "HEATER_STATE_ON" 0 "HEATER_STATE_SNA" ;
VAL_ 929 VCFRONT_thermalSystemType 1 "HEAT_PUMP_THERMAL_SYSTEM" 0 "LEGACY_THERMAL_SYSTEM" ;
VAL_ 929 VCFRONT_diPowerOnState 5 "DI_POWERED_ON_FOR_WINCH" 4 "DI_POWER_GOING_DOWN" 3 "DI_POWERED_ON_FOR_DRIVE" 2 "DI_POWERED_ON_FOR_STATIONARY_HEAT" 1 "DI_POWERED_ON_FOR_SUMMON" 0 "DI_POWERED_OFF" ;
VAL_ 929 VCFRONT_12vStatusForDrive 2 "EXIT_DRIVE_REQUESTED_12V" 1 "READY_FOR_DRIVE_12V" 0 "NOT_READY_FOR_DRIVE_12V" ;
VAL_ 929 VC_userPresenceState 3 "TIMED_OUT" 2 "PRESENT" 1 "NOT_PRESENT" 0 "INIT" ;
VAL_ 929 VCFRONT_driverBuckleStatus 1 "BUCKLED" 0 "UNBUCKLED" ;
VAL_ 929 VCFRONT_driverDoorStatus 1 "DOOR_CLOSED" 0 "DOOR_OPEN" ;
VAL_ 929 VCFRONT_driverUnbuckled 2 "CHIME_SNA" 1 "CHIME_OCCUPIED_AND_UNBUCKLED" 0 "CHIME_NONE" ;
VAL_ 929 VCFRONT_passengerUnbuckled 2 "CHIME_SNA" 1 "CHIME_OCCUPIED_AND_UNBUCKLED" 0 "CHIME_NONE" ;
VAL_ 929 VCFRONT_2RowLeftUnbuckled 2 "CHIME_SNA" 1 "CHIME_OCCUPIED_AND_UNBUCKLED" 0 "CHIME_NONE" ;
VAL_ 929 VCFRONT_2RowCenterUnbuckled 2 "CHIME_SNA" 1 "CHIME_OCCUPIED_AND_UNBUCKLED" 0 "CHIME_NONE" ;
VAL_ 929 VCFRONT_2RowRightUnbuckled 2 "CHIME_SNA" 1 "CHIME_OCCUPIED_AND_UNBUCKLED" 0 "CHIME_NONE" ;
VAL_ 929 VCFRONT_3RowLeftUnbuckled 2 "CHIME_SNA" 1 "CHIME_OCCUPIED_AND_UNBUCKLED" 0 "CHIME_NONE" ;
VAL_ 929 VCFRONT_3RowRightUnbuckled 2 "CHIME_SNA" 1 "CHIME_OCCUPIED_AND_UNBUCKLED" 0 "CHIME_NONE" ;
VAL_ 507 VCLEFT_TLCState_LeftTurn 5 "VCLEFT_TLC_LIGHT_STATE_SNA" 4 "VCLEFT_TLC_LIGHT_STATE_FAULT" 3 "VCLEFT_TLC_LIGHT_STATE_ON_WITH_LOAD" 2 "VCLEFT_TLC_LIGHT_STATE_ON_WITHOUT_LOAD" 1 "VCLEFT_TLC_LIGHT_STATE_OFF_WITH_LOAD" 0 "VCLEFT_TLC_LIGHT_STATE_OFF_WITHOUT_LOAD" ;
VAL_ 507 VCLEFT_TLCState_RightTurn 5 "VCLEFT_TLC_LIGHT_STATE_SNA" 4 "VCLEFT_TLC_LIGHT_STATE_FAULT" 3 "VCLEFT_TLC_LIGHT_STATE_ON_WITH_LOAD" 2 "VCLEFT_TLC_LIGHT_STATE_ON_WITHOUT_LOAD" 1 "VCLEFT_TLC_LIGHT_STATE_OFF_WITH_LOAD" 0 "VCLEFT_TLC_LIGHT_STATE_OFF_WITHOUT_LOAD" ;
VAL_ 507 VCLEFT_TLCState_Tail 5 "VCLEFT_TLC_LIGHT_STATE_SNA" 4 "VCLEFT_TLC_LIGHT_STATE_FAULT" 3 "VCLEFT_TLC_LIGHT_STATE_ON_WITH_LOAD" 2 "VCLEFT_TLC_LIGHT_STATE_ON_WITHOUT_LOAD" 1 "VCLEFT_TLC_LIGHT_STATE_OFF_WITH_LOAD" 0 "VCLEFT_TLC_LIGHT_STATE_OFF_WITHOUT_LOAD" ;
VAL_ 507 VCLEFT_TLCState_Stop 5 "VCLEFT_TLC_LIGHT_STATE_SNA" 4 "VCLEFT_TLC_LIGHT_STATE_FAULT" 3 "VCLEFT_TLC_LIGHT_STATE_ON_WITH_LOAD" 2 "VCLEFT_TLC_LIGHT_STATE_ON_WITHOUT_LOAD" 1 "VCLEFT_TLC_LIGHT_STATE_OFF_WITH_LOAD" 0 "VCLEFT_TLC_LIGHT_STATE_OFF_WITHOUT_LOAD" ;
VAL_ 507 VCLEFT_TLCState_Fog 5 "VCLEFT_TLC_LIGHT_STATE_SNA" 4 "VCLEFT_TLC_LIGHT_STATE_FAULT" 3 "VCLEFT_TLC_LIGHT_STATE_ON_WITH_LOAD" 2 "VCLEFT_TLC_LIGHT_STATE_ON_WITHOUT_LOAD" 1 "VCLEFT_TLC_LIGHT_STATE_OFF_WITH_LOAD" 0 "VCLEFT_TLC_LIGHT_STATE_OFF_WITHOUT_LOAD" ;
VAL_ 507 VCLEFT_TLCState_Reverse 5 "VCLEFT_TLC_LIGHT_STATE_SNA" 4 "VCLEFT_TLC_LIGHT_STATE_FAULT" 3 "VCLEFT_TLC_LIGHT_STATE_ON_WITH_LOAD" 2 "VCLEFT_TLC_LIGHT_STATE_ON_WITHOUT_LOAD" 1 "VCLEFT_TLC_LIGHT_STATE_OFF_WITH_LOAD" 0 "VCLEFT_TLC_LIGHT_STATE_OFF_WITHOUT_LOAD" ;
